VERSION "created by canmatrix"

NS_ :

BS_:

BU_: IPD

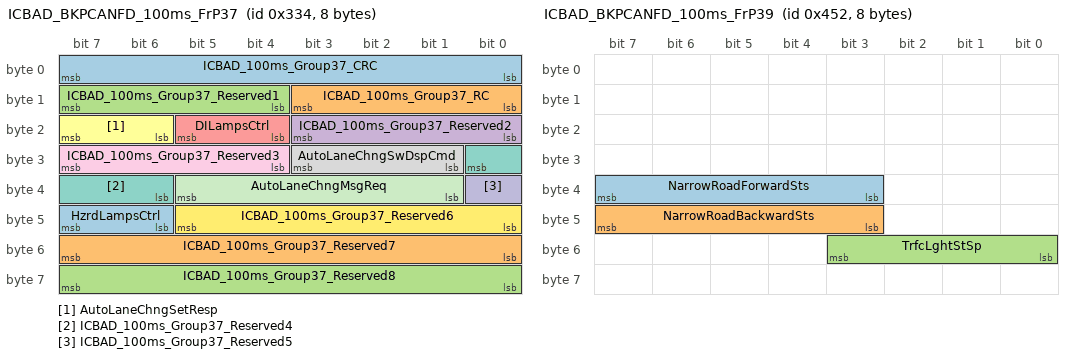
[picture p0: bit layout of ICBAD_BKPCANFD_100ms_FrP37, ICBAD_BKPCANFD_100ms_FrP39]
BO_ 820 ICBAD_BKPCANFD_100ms_FrP37: 8 IPD
 SG_ ICBAD_100ms_Group37_CRC : 7|8@0+ (1,0) [0|255] "null" Vector__XXX
 SG_ ICBAD_100ms_Group37_RC : 11|4@0+ (1,0) [0|15] "null" Vector__XXX
 SG_ ICBAD_100ms_Group37_Reserved1 : 15|4@0+ (1,0) [0|15] "null" Vector__XXX
 SG_ ICBAD_100ms_Group37_Reserved2 : 19|4@0+ (1,0) [0|15] "null" Vector__XXX
 SG_ DILampsCtrl : 21|2@0+ (1,0) [0|3] "null" Vector__XXX
 SG_ AutoLaneChngSetResp : 23|2@0+ (1,0) [0|3] "null" Vector__XXX
 SG_ ICBAD_100ms_Group37_Reserved4 : 24|3@0+ (1,0) [0|7] "null" Vector__XXX
 SG_ AutoLaneChngSwDspCmd : 27|3@0+ (1,0) [0|7] "null" Vector__XXX
 SG_ ICBAD_100ms_Group37_Reserved3 : 31|4@0+ (1,0) [0|15] "null" Vector__XXX
 SG_ ICBAD_100ms_Group37_Reserved5 : 32|1@0+ (1,0) [0|1] "null" Vector__XXX
 SG_ AutoLaneChngMsgReq : 37|5@0+ (1,0) [0|31] "null" Vector__XXX
 SG_ ICBAD_100ms_Group37_Reserved6 : 45|6@0+ (1,0) [0|63] "null" Vector__XXX
 SG_ HzrdLampsCtrl : 47|2@0+ (1,0) [0|3] "null" Vector__XXX
 SG_ ICBAD_100ms_Group37_Reserved7 : 55|8@0+ (1,0) [0|255] "null" Vector__XXX
 SG_ ICBAD_100ms_Group37_Reserved8 : 63|8@0+ (1,0) [0|255] "null" Vector__XXX

BO_ 1105 ICBAD_BKPCANFD_100ms_FrP38: 32 IPD
 SG_ ELKSysFltSts : 74|2@0+ (1,0) [0|3] "null" Vector__XXX
 SG_ NrwroadFwdSta : 122|3@0+ (1,0) [0|7] "null" Vector__XXX
 SG_ NrwroadsltSta : 130|3@0+ (1,0) [0|7] "null" Vector__XXX
 SG_ ELKDspCmd : 194|2@0+ (1,0) [0|3] "null" Vector__XXX
 SG_ MemParkngBtnRcnm : 203|2@0+ (1,0) [0|3] "null" Vector__XXX

BO_ 1106 ICBAD_BKPCANFD_100ms_FrP39: 8 IPD
 SG_ NarrowRoadForwardSts : 39|5@0+ (1,0) [0|31] "null" Vector__XXX
 SG_ NarrowRoadBackwardSts : 47|5@0+ (1,0) [0|31] "null" Vector__XXX
 SG_ TrfcLghtStSp : 51|4@0+ (1,0) [0|15] "null" Vector__XXX

BO_ 151 ICBAD_BKPCANFD_100ms_FrP44: 24 IPD
 SG_ AIParkngEPAMdsts : 32|1@0+ (1,0) [0|1] "null" Vector__XXX
 SG_ D2DSwReqResps : 41|2@0+ (1,0) [0|3] "null" Vector__XXX
 SG_ FCTBSysFltSts : 77|2@0+ (1,0) [0|3] "null" Vector__XXX
 SG_ D2DPriETClanSwReqResps : 79|2@0+ (1,0) [0|3] "null" Vector__XXX

BO_ 382 ICBAD_BKPCANFD_20ms_FrP07: 8 IPD
 SG_ ICBAD_20ms_Group07_CRC : 7|8@0+ (1,0) [0|255] "null" Vector__XXX
 SG_ ICBAD_20ms_Group07_RC : 11|4@0+ (1,0) [0|15] "null" Vector__XXX
 SG_ ACCSdslReq : 12|1@0+ (1,0) [0|1] "null" Vector__XXX
 SG_ ACCGoReq : 13|1@0+ (1,0) [0|1] "null" Vector__XXX
 SG_ ACCAccReqSts_CH : 15|2@0+ (1,0) [0|3] "null" Vector__XXX
 SG_ ACCAccReqVal : 18|11@0+ (0.006,-10.278) [-10.278|2.004] "null" Vector__XXX
 SG_ APAEPBOPReq : 20|2@0+ (1,0) [0|3] "null" Vector__XXX
 SG_ ACCSysFltSts : 23|3@0+ (1,0) [0|7] "null" Vector__XXX
 SG_ AIPkgAPASCSAcclReqVal : 34|11@0+ (0.005,-9.22) [-9.220|1.015] "m/s^2" Vector__XXX
 SG_ ACCSysSts : 37|3@0+ (1,0) [0|7] "null" Vector__XXX
 SG_ APASCSAcclReqSts : 38|1@0+ (1,0) [0|1] "null" Vector__XXX
 SG_ APAEPBOPReqV : 39|1@0+ (1,0) [0|1] "null" Vector__XXX
 SG_ AutodDrvngSysSCSSdslReqV : 48|1@0+ (1,0) [0|1] "null" Vector__XXX
 SG_ AutodDrvngSysSCSSdslReq : 49|1@0+ (1,0) [0|1] "null" Vector__XXX
 SG_ AutodDrvngSysEmgcBrkReqV : 50|1@0+ (1,0) [0|1] "null" Vector__XXX
 SG_ AutodDrvngSysEmgcBrkReq : 51|1@0+ (1,0) [0|1] "null" Vector__XXX
 SG_ ICBAD_20ms_Group07_Reserved1 : 55|4@0+ (1,0) [0|15] "null" Vector__XXX
 SG_ AutodDrvngSysSCSDrvOffReqV : 56|1@0+ (1,0) [0|1] "null" Vector__XXX
 SG_ AutodDrvngSysSCSDrvOffReq : 57|1@0+ (1,0) [0|1] "null" Vector__XXX
 SG_ AutodDrvngSysMdReqV : 58|1@0+ (1,0) [0|1] "null" Vector__XXX
 SG_ AutodDrvngSysMdReq : 59|1@0+ (1,0) [0|1] "null" Vector__XXX
 SG_ AutodDrvngSysFlrStsV : 60|1@0+ (1,0) [0|1] "null" Vector__XXX
 SG_ AutodDrvngSysFlrSts : 63|3@0+ (1,0) [0|7] "null" Vector__XXX

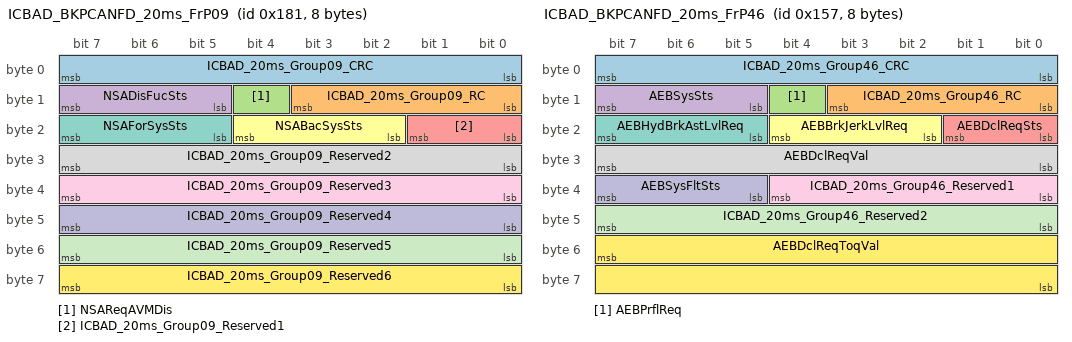
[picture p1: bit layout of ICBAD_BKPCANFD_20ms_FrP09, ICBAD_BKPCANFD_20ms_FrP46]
BO_ 385 ICBAD_BKPCANFD_20ms_FrP09: 8 IPD
 SG_ ICBAD_20ms_Group09_CRC : 7|8@0+ (1,0) [0|255] "null" Vector__XXX
 SG_ ICBAD_20ms_Group09_RC : 11|4@0+ (1,0) [0|15] "null" Vector__XXX
 SG_ NSAReqAVMDis : 12|1@0+ (1,0) [0|1] "null" Vector__XXX
 SG_ NSADisFucSts : 15|3@0+ (1,0) [0|7] "null" Vector__XXX
 SG_ ICBAD_20ms_Group09_Reserved1 : 17|2@0+ (1,0) [0|3] "null" Vector__XXX
 SG_ NSABacSysSts : 20|3@0+ (1,0) [0|7] "null" Vector__XXX
 SG_ NSAForSysSts : 23|3@0+ (1,0) [0|7] "null" Vector__XXX
 SG_ ICBAD_20ms_Group09_Reserved2 : 31|8@0+ (1,0) [0|255] "null" Vector__XXX
 SG_ ICBAD_20ms_Group09_Reserved3 : 39|8@0+ (1,0) [0|255] "null" Vector__XXX
 SG_ ICBAD_20ms_Group09_Reserved4 : 47|8@0+ (1,0) [0|255] "null" Vector__XXX
 SG_ ICBAD_20ms_Group09_Reserved5 : 55|8@0+ (1,0) [0|255] "null" Vector__XXX
 SG_ ICBAD_20ms_Group09_Reserved6 : 63|8@0+ (1,0) [0|255] "null" Vector__XXX

BO_ 343 ICBAD_BKPCANFD_20ms_FrP46: 8 IPD
 SG_ ICBAD_20ms_Group46_CRC : 7|8@0+ (1,0) [0|255] "null" Vector__XXX
 SG_ ICBAD_20ms_Group46_RC : 11|4@0+ (1,0) [0|15] "null" Vector__XXX
 SG_ AEBPrflReq : 12|1@0+ (1,0) [0|1] "null" Vector__XXX
 SG_ AEBSysSts : 15|3@0+ (1,0) [0|7] "null" Vector__XXX
 SG_ AEBDclReqSts : 17|2@0+ (1,0) [0|3] "null" Vector__XXX
 SG_ AEBBrkJerkLvlReq : 20|3@0+ (1,0) [0|7] "null" Vector__XXX
 SG_ AEBHydBrkAstLvlReq : 23|3@0+ (1,0) [0|7] "null" Vector__XXX
 SG_ AEBDclReqVal : 31|8@0+ (0.1,-12.7) [-12.7|12.8] "m/s2" Vector__XXX
 SG_ ICBAD_20ms_Group46_Reserved1 : 36|5@0+ (1,0) [0|31] "null" Vector__XXX
 SG_ AEBSysFltSts : 39|3@0+ (1,0) [0|7] "null" Vector__XXX
 SG_ ICBAD_20ms_Group46_Reserved2 : 47|8@0+ (1,0) [0|255] "null" Vector__XXX
 SG_ AEBDclReqToqVal : 55|16@0+ (1,0) [0|65535] "Nm" Vector__XXX

BO_ 736 ICBAD_BKPCANFD_50ms_FrP17: 20 IPD
 SG_ FrtObsDist : 7|8@0+ (1,0) [0|255] "cm" Vector__XXX
 SG_ FrtMidRObsRng : 11|4@0+ (1,0) [0|15] "null" Vector__XXX
 SG_ FrtPDCAudWrnng : 15|4@0+ (1,0) [0|15] "null" Vector__XXX
 SG_ RrMidLObsRng : 19|4@0+ (1,0) [0|15] "null" Vector__XXX
 SG_ RLObsRng : 23|4@0+ (1,0) [0|15] "null" Vector__XXX
 SG_ RrMidRObsRng : 31|4@0+ (1,0) [0|15] "null" Vector__XXX
 SG_ PDCSysSts : 39|4@0+ (1,0) [0|15] "null" Vector__XXX
 SG_ RrObsDist : 63|8@0+ (1,0) [0|255] "cm" Vector__XXX
 SG_ FLSideObsRng : 67|4@0+ (1,0) [0|15] "null" Vector__XXX
 SG_ RrPDCAudWrnng : 71|4@0+ (1,0) [0|15] "null" Vector__XXX
 SG_ RLSideObsRng : 75|4@0+ (1,0) [0|15] "null" Vector__XXX
 SG_ FRSideObsRng : 79|4@0+ (1,0) [0|15] "null" Vector__XXX
 SG_ RRSideObsRng : 87|4@0+ (1,0) [0|15] "null" Vector__XXX
 SG_ FLObsRng : 123|4@0+ (1,0) [0|15] "null" Vector__XXX
 SG_ RRObsRng : 131|4@0+ (1,0) [0|15] "null" Vector__XXX
 SG_ FRObsRng : 135|4@0+ (1,0) [0|15] "null" Vector__XXX
 SG_ LADSAFnInd_Tester : 139|4@0+ (1,0) [0|15] "null" Vector__XXX
 SG_ FrtMidLObsRng : 143|4@0+ (1,0) [0|15] "null" Vector__XXX
 SG_ FRSObsRng : 147|4@0+ (1,0) [0|15] "null" Vector__XXX
 SG_ FLSObsRng : 151|4@0+ (1,0) [0|15] "null" Vector__XXX
 SG_ RRSObsRng : 155|4@0+ (1,0) [0|15] "null" Vector__XXX
 SG_ RLSObsRng : 159|4@0+ (1,0) [0|15] "null" Vector__XXX

BO_ 893 ICBAD_CHCANFD_100ms_FrP25: 24 IPD
 SG_ ICBAD_100ms_Group25_CRC : 7|8@0+ (1,0) [0|255] "null" Vector__XXX
 SG_ ICBAD_100ms_Group25_RC : 11|4@0+ (1,0) [0|15] "null" Vector__XXX
 SG_ ICBAD_100ms_Group25_Reserved15 : 15|4@0+ (1,0) [0|15] "null" Vector__XXX
 SG_ ICBAD_100ms_Group25_Reserved23 : 23|8@0+ (1,0) [0|255] "null" Vector__XXX
 SG_ ICBAD_100ms_Group25_Reserved31 : 31|8@0+ (1,0) [0|255] "null" Vector__XXX
 SG_ ICBAD_100ms_Group25_Reserved39 : 39|8@0+ (1,0) [0|255] "null" Vector__XXX
 SG_ ICBAD_100ms_Group25_Reserved47 : 47|8@0+ (1,0) [0|255] "null" Vector__XXX
 SG_ ICBAD_100ms_Group25_Reserved55 : 55|8@0+ (1,0) [0|255] "null" Vector__XXX
 SG_ ICBAD_100ms_Group25_Reserved63 : 63|8@0+ (1,0) [0|255] "null" Vector__XXX
 SG_ ICBAD_100ms_Group25_Reserved71 : 71|8@0+ (1,0) [0|255] "null" Vector__XXX
 SG_ ICBAD_100ms_Group25_Reserved79 : 79|8@0+ (1,0) [0|255] "null" Vector__XXX
 SG_ ICBAD_100ms_Group25_Reserved87 : 87|8@0+ (1,0) [0|255] "null" Vector__XXX
 SG_ ICBAD_100ms_Group25_Reserved95 : 95|8@0+ (1,0) [0|255] "null" Vector__XXX
 SG_ MemPkngSwResp : 97|2@0+ (1,0) [0|3] "null" Vector__XXX
 SG_ ICBAD_100ms_Group25_Reserved103 : 103|6@0+ (1,0) [0|63] "null" Vector__XXX
 SG_ MemPkngSlntPtrlEnbSwResp : 105|2@0+ (1,0) [0|3] "null" Vector__XXX
 SG_ ICBAD_100ms_Group25_Reserved111 : 111|6@0+ (1,0) [0|63] "null" Vector__XXX
 SG_ ICBAD_100ms_Group25_Reserved119 : 119|8@0+ (1,0) [0|255] "null" Vector__XXX
 SG_ PEBSysFltSts : 121|2@0+ (1,0) [0|3] "null" Vector__XXX
 SG_ ICBAD_100ms_Group25_Reserved127 : 127|6@0+ (1,0) [0|63] "null" Vector__XXX
 SG_ ICBAD_100ms_Group25_Reserved135 : 135|8@0+ (1,0) [0|255] "null" Vector__XXX
 SG_ ICBAD_100ms_Group25_Reserved143 : 143|8@0+ (1,0) [0|255] "null" Vector__XXX
 SG_ ICBAD_100ms_Group25_Reserved151 : 151|8@0+ (1,0) [0|255] "null" Vector__XXX
 SG_ ICBAD_100ms_Group25_Reserved159 : 159|8@0+ (1,0) [0|255] "null" Vector__XXX
 SG_ ICBAD_100ms_Group25_Reserved167 : 167|8@0+ (1,0) [0|255] "null" Vector__XXX
 SG_ ICBAD_100ms_Group25_Reserved175 : 175|8@0+ (1,0) [0|255] "null" Vector__XXX
 SG_ ICBAD_100ms_Group25_Reserved183 : 183|8@0+ (1,0) [0|255] "null" Vector__XXX
 SG_ ICBAD_100ms_Group25_Reserved191 : 191|8@0+ (1,0) [0|255] "null" Vector__XXX

BO_ 314 ICBAD_CHCANFD_20ms_FrP08: 8 IPD
 SG_ D2DSysSts : 31|4@0+ (1,0) [0|15] "null" Vector__XXX
 SG_ ACCObjDet : 56|1@0+ (1,0) [0|1] "null" Vector__XXX

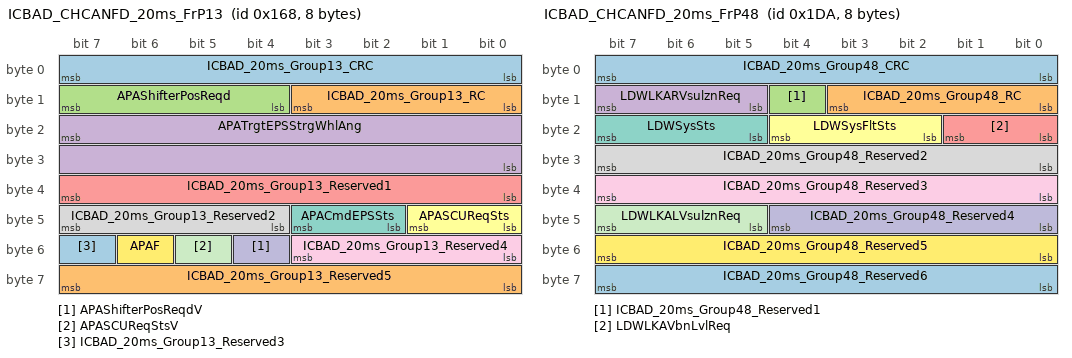
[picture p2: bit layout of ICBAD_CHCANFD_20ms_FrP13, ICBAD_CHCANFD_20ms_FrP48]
BO_ 360 ICBAD_CHCANFD_20ms_FrP13: 8 IPD
 SG_ ICBAD_20ms_Group13_CRC : 7|8@0+ (1,0) [0|255] "null" Vector__XXX
 SG_ ICBAD_20ms_Group13_RC : 11|4@0+ (1,0) [0|15] "null" Vector__XXX
 SG_ APAShifterPosReqd : 15|4@0+ (1,0) [0|15] "null" Vector__XXX
 SG_ APATrgtEPSStrgWhlAng : 23|16@0+ (0.0625,-2048) [-2048.0000|2047.9375] "percent" Vector__XXX
 SG_ ICBAD_20ms_Group13_Reserved1 : 39|8@0+ (1,0) [0|255] "null" Vector__XXX
 SG_ APASCUReqSts : 41|2@0+ (1,0) [0|3] "null" Vector__XXX
 SG_ APACmdEPSSts : 43|2@0+ (1,0) [0|3] "null" Vector__XXX
 SG_ ICBAD_20ms_Group13_Reserved2 : 47|4@0+ (1,0) [0|15] "null" Vector__XXX
 SG_ ICBAD_20ms_Group13_Reserved4 : 51|4@0+ (1,0) [0|15] "null" Vector__XXX
 SG_ APAShifterPosReqdV : 52|1@0+ (1,0) [0|1] "null" Vector__XXX
 SG_ APASCUReqStsV : 53|1@0+ (1,0) [0|1] "null" Vector__XXX
 SG_ APAF : 54|1@0+ (1,0) [0|1] "null" Vector__XXX
 SG_ ICBAD_20ms_Group13_Reserved3 : 55|1@0+ (1,0) [0|1] "null" Vector__XXX
 SG_ ICBAD_20ms_Group13_Reserved5 : 63|8@0+ (1,0) [0|255] "null" Vector__XXX

BO_ 474 ICBAD_CHCANFD_20ms_FrP48: 8 IPD
 SG_ ICBAD_20ms_Group48_CRC : 7|8@0+ (1,0) [0|255] "null" Vector__XXX
 SG_ ICBAD_20ms_Group48_RC : 11|4@0+ (1,0) [0|15] "null" Vector__XXX
 SG_ ICBAD_20ms_Group48_Reserved1 : 12|1@0+ (1,0) [0|1] "null" Vector__XXX
 SG_ LDWLKARVsulznReq : 15|3@0+ (1,0) [0|7] "null" Vector__XXX
 SG_ LDWLKAVbnLvlReq : 17|2@0+ (1,0) [0|3] "null" Vector__XXX
 SG_ LDWSysFltSts : 20|3@0+ (1,0) [0|7] "null" Vector__XXX
 SG_ LDWSysSts : 23|3@0+ (1,0) [0|7] "null" Vector__XXX
 SG_ ICBAD_20ms_Group48_Reserved2 : 31|8@0+ (1,0) [0|255] "null" Vector__XXX
 SG_ ICBAD_20ms_Group48_Reserved3 : 39|8@0+ (1,0) [0|255] "null" Vector__XXX
 SG_ ICBAD_20ms_Group48_Reserved4 : 44|5@0+ (1,0) [0|31] "null" Vector__XXX
 SG_ LDWLKALVsulznReq : 47|3@0+ (1,0) [0|7] "null" Vector__XXX
 SG_ ICBAD_20ms_Group48_Reserved5 : 55|8@0+ (1,0) [0|255] "null" Vector__XXX
 SG_ ICBAD_20ms_Group48_Reserved6 : 63|8@0+ (1,0) [0|255] "null" Vector__XXX

BO_ 351 ICBAD_RZCUCANFD_20ms_FrP05: 20 IPD
 SG_ ICBAD_20ms_Group05_CRC : 7|8@0+ (1,0) [0|255] "null" Vector__XXX
 SG_ ICBAD_20ms_Group05_RC : 11|4@0+ (1,0) [0|15] "null" Vector__XXX
 SG_ ICBAD_20ms_Group05_Reserved1 : 12|1@0+ (1,0) [0|1] "null" Vector__XXX
 SG_ APAVCUReqSts : 15|3@0+ (1,0) [0|7] "null" Vector__XXX
 SG_ ICBAD_20ms_Group05_Reserved2 : 23|8@0+ (1,0) [0|255] "null" Vector__XXX
 SG_ APAToqReqVal : 31|12@0+ (0.5,-848) [-848|1199.5] "Nm" Vector__XXX
 SG_ APACrpSpdReqVal_IPD : 33|10@0+ (0.1,0) [0|102.3] "km/h" Vector__XXX
 SG_ ICBAD_20ms_Group05_Reserved3 : 34|1@0+ (1,0) [0|1] "null" Vector__XXX
 SG_ APARevrDrgReq : 35|1@0+ (1,0) [0|1] "null" Vector__XXX
 SG_ ICBAD_20ms_Group05_Reserved4 : 55|8@0+ (1,0) [0|255] "null" Vector__XXX
 SG_ ICBAD_20ms_Group05_Reserved5 : 63|8@0+ (1,0) [0|255] "null" Vector__XXX
 SG_ APATotWhlToqReqVal : 71|16@0+ (1,-30000) [-30000|35535] "Nm" Vector__XXX
 SG_ ICBAD_20ms_Group05_Reserved6 : 87|8@0+ (1,0) [0|255] "null" Vector__XXX
 SG_ ICBAD_20ms_Group05_Reserved7 : 95|8@0+ (1,0) [0|255] "null" Vector__XXX
 SG_ ICBAD_20ms_Group05_Reserved8 : 103|8@0+ (1,0) [0|255] "null" Vector__XXX
 SG_ ICBAD_20ms_Group05_Reserved9 : 111|8@0+ (1,0) [0|255] "null" Vector__XXX
 SG_ ICBAD_20ms_Group05_Reserved10 : 119|8@0+ (1,0) [0|255] "null" Vector__XXX
 SG_ ICBAD_20ms_Group05_Reserved11 : 127|8@0+ (1,0) [0|255] "null" Vector__XXX
 SG_ ICBAD_20ms_Group05_Reserved12 : 135|8@0+ (1,0) [0|255] "null" Vector__XXX
 SG_ ICBAD_20ms_Group05_Reserved13 : 143|8@0+ (1,0) [0|255] "null" Vector__XXX
 SG_ ICBAD_20ms_Group05_Reserved14 : 151|8@0+ (1,0) [0|255] "null" Vector__XXX
 SG_ ICBAD_20ms_Group05_Reserved15 : 159|8@0+ (1,0) [0|255] "null" Vector__XXX

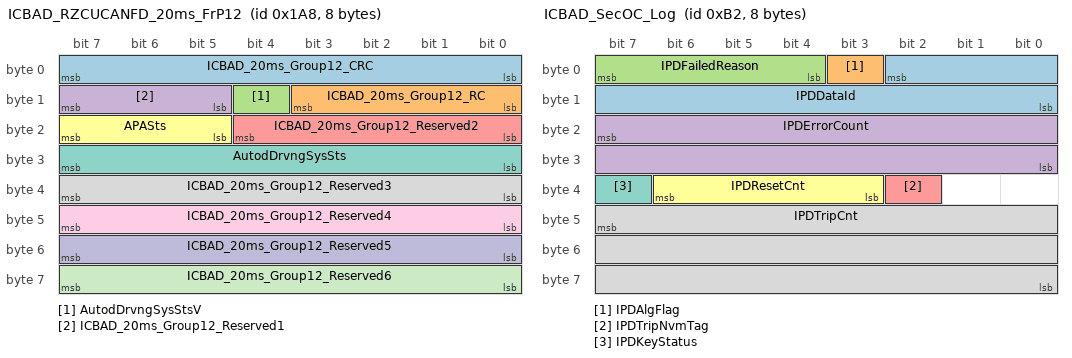
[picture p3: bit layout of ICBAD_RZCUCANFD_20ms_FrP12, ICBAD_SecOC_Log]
BO_ 424 ICBAD_RZCUCANFD_20ms_FrP12: 8 IPD
 SG_ ICBAD_20ms_Group12_CRC : 7|8@0+ (1,0) [0|255] "null" Vector__XXX
 SG_ ICBAD_20ms_Group12_RC : 11|4@0+ (1,0) [0|15] "null" Vector__XXX
 SG_ AutodDrvngSysStsV : 12|1@0+ (1,0) [0|1] "null" Vector__XXX
 SG_ ICBAD_20ms_Group12_Reserved1 : 15|3@0+ (1,0) [0|7] "null" Vector__XXX
 SG_ ICBAD_20ms_Group12_Reserved2 : 20|5@0+ (1,0) [0|31] "null" Vector__XXX
 SG_ APASts : 23|3@0+ (1,0) [0|7] "null" Vector__XXX
 SG_ AutodDrvngSysSts : 31|8@0+ (1,0) [0|255] "null" Vector__XXX
 SG_ ICBAD_20ms_Group12_Reserved3 : 39|8@0+ (1,0) [0|255] "null" Vector__XXX
 SG_ ICBAD_20ms_Group12_Reserved4 : 47|8@0+ (1,0) [0|255] "null" Vector__XXX
 SG_ ICBAD_20ms_Group12_Reserved5 : 55|8@0+ (1,0) [0|255] "null" Vector__XXX
 SG_ ICBAD_20ms_Group12_Reserved6 : 63|8@0+ (1,0) [0|255] "null" Vector__XXX

BO_ 50 ICBAD_SecOC_ComKeyResp: 8 IPD
 SG_ IPDTripCntResetResp : 6|1@0+ (1,0) [0|1] "null" Vector__XXX

BO_ 178 ICBAD_SecOC_Log: 8 IPD
 SG_ IPDDataId : 2|11@0+ (1,0) [0|2047] "null" Vector__XXX
 SG_ IPDAlgFlag : 3|1@0+ (1,0) [0|1] "null" Vector__XXX
 SG_ IPDFailedReason : 7|4@0+ (1,0) [0|15] "null" Vector__XXX
 SG_ IPDErrorCount : 23|16@0+ (1,0) [0|65535] "null" Vector__XXX
 SG_ IPDTripNvmTag : 34|1@0+ (1,0) [0|1] "null" Vector__XXX
 SG_ IPDResetCnt : 38|4@0+ (1,0) [0|15] "null" Vector__XXX
 SG_ IPDKeyStatus : 39|1@0+ (1,0) [0|1] "null" Vector__XXX
 SG_ IPDTripCnt : 47|24@0+ (1,0) [0|16777215] "null" Vector__XXX

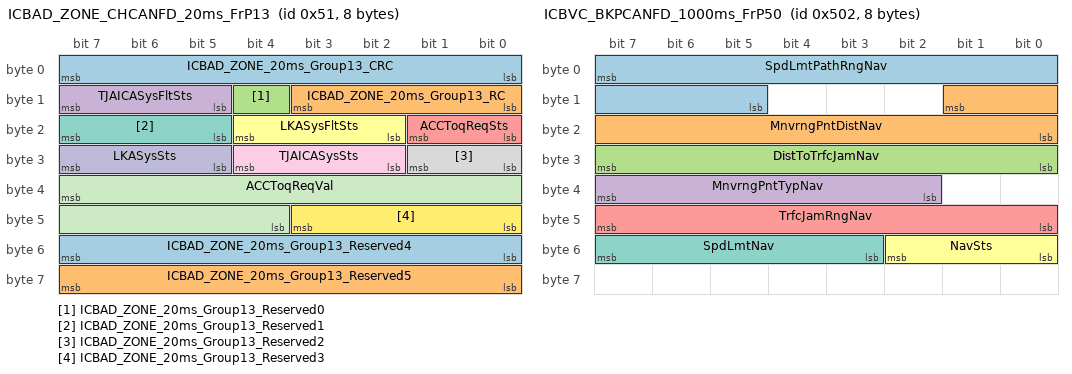
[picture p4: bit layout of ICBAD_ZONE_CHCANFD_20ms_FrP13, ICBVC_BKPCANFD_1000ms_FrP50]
BO_ 81 ICBAD_ZONE_CHCANFD_20ms_FrP13: 8 IPD
 SG_ ICBAD_ZONE_20ms_Group13_CRC : 7|8@0+ (1,0) [0|255] "null" Vector__XXX
 SG_ ICBAD_ZONE_20ms_Group13_RC : 11|4@0+ (1,0) [0|15] "null" Vector__XXX
 SG_ ICBAD_ZONE_20ms_Group13_Reserved0 : 12|1@0+ (1,0) [0|1] "null" Vector__XXX
 SG_ TJAICASysFltSts : 15|3@0+ (1,0) [0|7] "null" Vector__XXX
 SG_ ACCToqReqSts : 17|2@0+ (1,0) [0|3] "null" Vector__XXX
 SG_ LKASysFltSts : 20|3@0+ (1,0) [0|7] "null" Vector__XXX
 SG_ ICBAD_ZONE_20ms_Group13_Reserved1 : 23|3@0+ (1,0) [0|7] "null" Vector__XXX
 SG_ ICBAD_ZONE_20ms_Group13_Reserved2 : 25|2@0+ (1,0) [0|3] "null" Vector__XXX
 SG_ TJAICASysSts : 28|3@0+ (1,0) [0|7] "null" Vector__XXX
 SG_ LKASysSts : 31|3@0+ (1,0) [0|7] "null" Vector__XXX
 SG_ ACCToqReqVal : 39|12@0+ (0.5,-848) [-848|1199.5] "null" Vector__XXX
 SG_ ICBAD_ZONE_20ms_Group13_Reserved3 : 43|4@0+ (1,0) [0|15] "null" Vector__XXX
 SG_ ICBAD_ZONE_20ms_Group13_Reserved4 : 55|8@0+ (1,0) [0|255] "null" Vector__XXX
 SG_ ICBAD_ZONE_20ms_Group13_Reserved5 : 63|8@0+ (1,0) [0|255] "null" Vector__XXX

BO_ 1282 ICBVC_BKPCANFD_1000ms_FrP50: 8 Vector__XXX
 SG_ SpdLmtPathRngNav : 7|11@0+ (0.01,0) [0.00|20.47] "km" IPD
 SG_ MnvrngPntDistNav : 9|10@0+ (1,0) [0|1023] "m" IPD
 SG_ DistToTrfcJamNav : 31|8@0+ (0.1,0) [0|25.5] "km" IPD
 SG_ MnvrngPntTypNav : 39|6@0+ (1,0) [0|63] "null" IPD
 SG_ TrfcJamRngNav : 47|8@0+ (0.1,0) [0|25.5] "km" IPD
 SG_ NavSts : 50|3@0+ (1,0) [0|7] "null" IPD
 SG_ SpdLmtNav : 55|5@0+ (5,0) [0|155] "kph" IPD

BO_ 66 ICBVC_BKPCANFD_100ms_FrP01: 16 Vector__XXX
 SG_ ICBVC_100ms_Group01_CRC : 7|8@0+ (1,0) [0|255] "null" IPD
 SG_ ICBVC_100ms_Group01_RC : 11|4@0+ (1,0) [0|15] "null" IPD
 SG_ ICBVC_100ms_Group01_Reserved14 : 14|3@0+ (1,0) [0|7] "null" IPD
 SG_ DspMeasmtSys : 15|1@0+ (1,0) [0|1] "null" IPD
 SG_ ICBVC_100ms_Group01_Reserved21 : 21|6@0+ (1,0) [0|63] "null" IPD
 SG_ PDCSwReq : 23|2@0+ (1,0) [0|3] "null" IPD
 SG_ PwrMdExtrCtrlAvlbl : 24|1@0+ (1,0) [0|1] "null" IPD
 SG_ MdOfPwrMd : 25|1@0+ (1,0) [0|1] "null" IPD
 SG_ ICBVC_100ms_Group01_Reserved31 : 31|6@0+ (1,0) [0|63] "null" IPD
 SG_ ClstrDspdVehSpd : 39|8@0+ (1,0) [0|255] "kph" IPD
 SG_ ICBVC_100ms_Group01_Reserved47 : 47|8@0+ (1,0) [0|255] "null" IPD
 SG_ ICBVC_100ms_Group01_Reserved55 : 55|8@0+ (1,0) [0|255] "null" IPD
 SG_ ICBVC_100ms_Group01_Reserved63 : 63|8@0+ (1,0) [0|255] "null" IPD
 SG_ ICBVC_100ms_Group01_Reserved71 : 71|8@0+ (1,0) [0|255] "null" IPD
 SG_ ICBVC_100ms_Group01_Reserved72 : 72|1@0+ (1,0) [0|1] "null" IPD
 SG_ FRSeatVentCtrlSts : 75|3@0+ (1,0) [0|7] "null" IPD
 SG_ ICBVC_100ms_Group01_Reserved79 : 79|4@0+ (1,0) [0|15] "null" IPD
 SG_ ICBVC_100ms_Group01_Reserved80 : 80|1@0+ (1,0) [0|1] "null" IPD
 SG_ FLSeatVentCtrlSts : 83|3@0+ (1,0) [0|7] "null" IPD
 SG_ ICBVC_100ms_Group01_Reserved84 : 84|1@0+ (1,0) [0|1] "null" IPD
 SG_ FRSeatHeatCtrlSts : 87|3@0+ (1,0) [0|7] "null" IPD
 SG_ ICBVC_100ms_Group01_Reserved92 : 92|5@0+ (1,0) [0|31] "null" IPD
 SG_ FLSeatHeatCtrlSts : 95|3@0+ (1,0) [0|7] "null" IPD
 SG_ ICBVC_100ms_Group01_Reserved103 : 103|8@0+ (1,0) [0|255] "null" IPD
 SG_ ICBVC_100ms_Group01_Reserved111 : 111|8@0+ (1,0) [0|255] "null" IPD
 SG_ ICBVC_100ms_Group01_Reserved119 : 119|8@0+ (1,0) [0|255] "null" IPD
 SG_ ICBVC_100ms_Group01_Reserved127 : 127|8@0+ (1,0) [0|255] "null" IPD

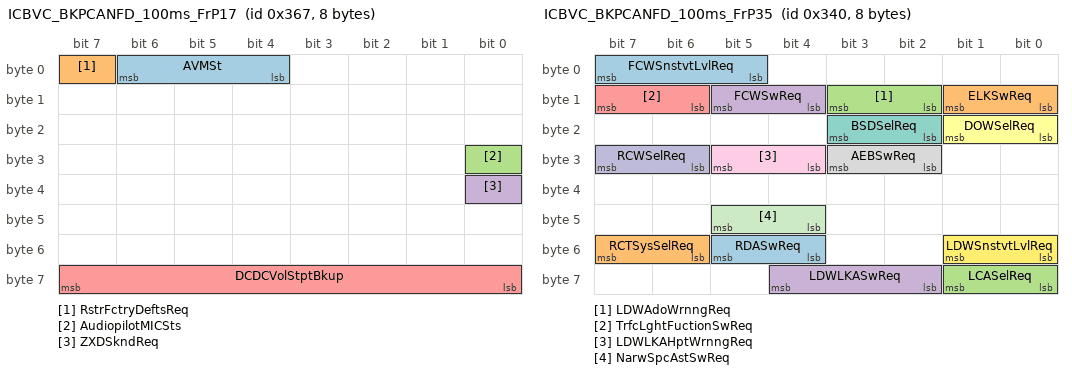
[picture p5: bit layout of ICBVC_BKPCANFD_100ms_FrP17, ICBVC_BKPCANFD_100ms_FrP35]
BO_ 871 ICBVC_BKPCANFD_100ms_FrP17: 8 Vector__XXX
 SG_ AVMSt : 6|3@0+ (1,0) [0|7] "null" IPD
 SG_ RstrFctryDeftsReq : 7|1@0+ (1,0) [0|1] "null" IPD
 SG_ AudiopilotMICSts : 24|1@0+ (1,0) [0|1] "null" Vector__XXX
 SG_ ZXDSkndReq : 32|1@0+ (1,0) [0|1] "null" Vector__XXX
 SG_ DCDCVolStptBkup : 63|8@0+ (0.03125,8.5) [8.50000|16.46875] "V" Vector__XXX

BO_ 906 ICBVC_BKPCANFD_100ms_FrP25: 24 Vector__XXX
 SG_ NavCrntRoadTyp : 3|4@0+ (1,0) [0|15] "null" IPD
 SG_ NavSpdLmtValUnit : 66|2@0+ (1,0) [0|3] "null" IPD
 SG_ NavNewIconDist : 71|5@0+ (0.1,0) [0|3.1] "null" IPD
 SG_ NavSpdLmtValSts : 73|2@0+ (1,0) [0|3] "null" IPD
 SG_ NavDistFromFrtEleccEye : 79|6@0+ (0.1,0) [0|6.3] "null" IPD
 SG_ NavItvalSpdDetnDistRetDist : 87|15@0+ (0.1,0) [0|3276.7] "null" IPD
 SG_ NavSpdLmtVal : 103|15@0+ (0.015625,0) [0.000000|511.984375] "null" IPD
 SG_ NavCndSpdLmtVal : 119|8@0+ (1,0) [0|255] "null" IPD
 SG_ NavSpdLmtTyp : 126|4@0+ (1,0) [0|15] "null" IPD
 SG_ NavNextRampOffset : 135|13@0+ (8.235,-100) [-100.000|67352.885] "m" IPD

BO_ 1104 ICBVC_BKPCANFD_100ms_FrP31: 20 Vector__XXX
 SG_ NrwroadFwdCtlReq : 39|4@0+ (1,0) [0|15] "null" IPD
 SG_ AIParkngSpdsw : 84|3@0+ (1,0) [0|7] "null" IPD
 SG_ NrwroadsltReq : 100|3@0+ (1,0) [0|7] "null" IPD
 SG_ NrwroadFwdReq : 103|3@0+ (1,0) [0|7] "null" IPD
 SG_ MemPkngSwReq : 121|2@0+ (1,0) [0|3] "null" IPD
 SG_ MemPkngSlntPtrlEnbSwReq : 131|2@0+ (1,0) [0|3] "null" IPD

BO_ 832 ICBVC_BKPCANFD_100ms_FrP35: 8 Vector__XXX
 SG_ FCWSnstvtLvlReq : 7|3@0+ (1,0) [0|7] "null" IPD
 SG_ ELKSwReq : 9|2@0+ (1,0) [0|3] "null" IPD
 SG_ LDWAdoWrnngReq : 11|2@0+ (1,0) [0|3] "null" IPD
 SG_ FCWSwReq : 13|2@0+ (1,0) [0|3] "null" IPD
 SG_ TrfcLghtFuctionSwReq : 15|2@0+ (1,0) [0|3] "null" IPD
 SG_ DOWSelReq : 17|2@0+ (1,0) [0|3] "null" IPD
 SG_ BSDSelReq : 19|2@0+ (1,0) [0|3] "null" IPD
 SG_ AEBSwReq : 27|2@0+ (1,0) [0|3] "null" IPD
 SG_ LDWLKAHptWrnngReq : 29|2@0+ (1,0) [0|3] "null" IPD
 SG_ RCWSelReq : 31|2@0+ (1,0) [0|3] "null" IPD
 SG_ NarwSpcAstSwReq : 45|2@0+ (1,0) [0|3] "null" IPD
 SG_ LDWSnstvtLvlReq : 49|2@0+ (1,0) [0|3] "null" IPD
 SG_ RDASwReq : 53|2@0+ (1,0) [0|3] "null" IPD
 SG_ RCTSysSelReq : 55|2@0+ (1,0) [0|3] "null" IPD
 SG_ LCASelReq : 57|2@0+ (1,0) [0|3] "null" IPD
 SG_ LDWLKASwReq : 60|3@0+ (1,0) [0|7] "null" IPD

BO_ 482 ICBVC_BKPCANFD_50ms_FrP11: 8 Vector__XXX
 SG_ ICBVC_50ms_Group11_CRC : 7|8@0+ (1,0) [0|255] "null" IPD
 SG_ ICBVC_50ms_Group11_RC : 11|4@0+ (1,0) [0|15] "null" IPD
 SG_ TrPfShftPtrnSw3A : 12|1@0+ (1,0) [0|1] "null" IPD
 SG_ TrPfShftPtrnSw2A : 13|1@0+ (1,0) [0|1] "null" IPD
 SG_ PfTrTapUpDwnSwSta : 15|2@0+ (1,0) [0|3] "null" IPD
 SG_ ICBVC_50ms_Group11_Reserved1 : 23|8@0+ (1,0) [0|255] "null" IPD
 SG_ ICBVC_50ms_Group11_Reserved2 : 31|8@0+ (1,0) [0|255] "null" IPD
 SG_ StrgWhlTipcSwDataIntgty : 32|1@0+ (1,0) [0|1] "null" IPD
 SG_ ICBVC_50ms_Group11_Reserved3 : 33|1@0+ (1,0) [0|1] "null" IPD
 SG_ CCSwStsDistIncSwA : 34|1@0+ (1,0) [0|1] "null" IPD
 SG_ CCSwStsDistDecSwA : 35|1@0+ (1,0) [0|1] "null" IPD
 SG_ CCSwStsSpdIncSwA : 36|1@0+ (1,0) [0|1] "null" IPD
 SG_ CCSwStsSpdDecSwA : 37|1@0+ (1,0) [0|1] "null" IPD
 SG_ CCSwStsSwDataIntgty : 39|2@0+ (1,0) [0|3] "null" IPD
 SG_ CCSwStsOnSwA : 40|1@0+ (1,0) [0|1] "null" IPD
 SG_ CCSwStsCanclSwA : 41|1@0+ (1,0) [0|1] "null" IPD
 SG_ PfTrTapUpDwnEnbSwSta : 43|2@0+ (1,0) [0|3] "null" IPD
 SG_ PfTrTapUpDwnSecySwSta : 45|2@0+ (1,0) [0|3] "null" IPD
 SG_ ICBVC_50ms_Group11_Reserved4 : 47|2@0+ (1,0) [0|3] "null" IPD
 SG_ TrPfShftPtrnSw1A : 48|1@0+ (1,0) [0|1] "null" IPD
 SG_ ICBVC_50ms_Group11_Reserved5 : 49|1@0+ (1,0) [0|1] "null" IPD
 SG_ SWSSelUpSwA : 50|1@0+ (1,0) [0|1] "null" IPD
 SG_ SWSSelRSwA : 51|1@0+ (1,0) [0|1] "null" IPD
 SG_ SWSSelLSwA : 52|1@0+ (1,0) [0|1] "null" IPD
 SG_ SWSSelDwnSwA : 53|1@0+ (1,0) [0|1] "null" IPD
 SG_ SWSCnfmSwA : 54|1@0+ (1,0) [0|1] "null" IPD
 SG_ CCSwStsRsmSwA : 55|1@0+ (1,0) [0|1] "null" IPD
 SG_ ICBVC_50ms_Group11_Reserved6 : 56|1@0+ (1,0) [0|1] "null" IPD
 SG_ HMISafFltsts : 59|3@0+ (1,0) [0|7] "null" IPD
 SG_ SwStaE2EErr : 62|3@0+ (1,0) [0|7] "null" IPD
 SG_ TrPfShftPtrnSw4A : 63|1@0+ (1,0) [0|1] "null" IPD

BO_ 1010 ICBVC_BKPCANFD_50ms_FrP13: 16 Vector__XXX
 SG_ ICBVC_50ms_Group13_CRC : 7|8@0+ (1,0) [0|255] "null" IPD
 SG_ ICBVC_50ms_Group13_RC : 11|4@0+ (1,0) [0|15] "null" IPD
 SG_ ICBVC_50ms_Group13_Reserved1 : 15|4@0+ (1,0) [0|15] "null" IPD
 SG_ ICBVC_50ms_Group13_Reserved2 : 23|8@0+ (1,0) [0|255] "null" IPD
 SG_ ICBVC_50ms_Group13_Reserved3 : 31|8@0+ (1,0) [0|255] "null" IPD
 SG_ TgtParkingChosed : 35|4@0+ (1,0) [0|15] "null" IPD
 SG_ SpdLmtMdFICM : 37|2@0+ (1,0) [0|3] "null" IPD
 SG_ AutocParkngSwReq : 39|2@0+ (1,0) [0|3] "null" IPD
 SG_ IMATESysSts : 42|3@0+ (1,0) [0|7] "null" IPD
 SG_ ICBVC_50ms_Group13_Reserved4 : 47|5@0+ (1,0) [0|31] "null" IPD
 SG_ ICBVC_50ms_Group13_Reserved5 : 55|8@0+ (1,0) [0|255] "null" IPD
 SG_ PwrMdCtrlResp : 58|3@0+ (1,0) [0|7] "null" IPD
 SG_ ICBVC_50ms_Group13_Reserved6 : 63|5@0+ (1,0) [0|31] "null" IPD
 SG_ ICBVC_50ms_Group13_Reserved7 : 71|8@0+ (1,0) [0|255] "null" IPD
 SG_ ICBVC_50ms_Group13_Reserved8 : 79|8@0+ (1,0) [0|255] "null" IPD
 SG_ ICBVC_50ms_Group13_Reserved10 : 84|5@0+ (1,0) [0|31] "null" IPD
 SG_ FRDircnLghtFltsts : 85|1@0+ (1,0) [0|1] "null" IPD
 SG_ ICBVC_50ms_Group13_Reserved9 : 86|1@0+ (1,0) [0|1] "null" IPD
 SG_ FLDircnLghtFltsts : 87|1@0+ (1,0) [0|1] "null" IPD
 SG_ ICBVC_50ms_Group13_Reserved12 : 90|3@0+ (1,0) [0|7] "null" IPD
 SG_ FrSsdManuCtrl : 92|2@0+ (1,0) [0|3] "null" IPD
 SG_ ICBVC_50ms_Group13_Reserved11 : 95|3@0+ (1,0) [0|7] "null" IPD
 SG_ ICBVC_50ms_Group13_Reserved13 : 103|8@0+ (1,0) [0|255] "null" IPD
 SG_ ICBVC_50ms_Group13_Reserved14 : 111|8@0+ (1,0) [0|255] "null" IPD
 SG_ ICBVC_50ms_Group13_Reserved15 : 119|8@0+ (1,0) [0|255] "null" IPD
 SG_ ICBVC_50ms_Group13_Reserved16 : 127|8@0+ (1,0) [0|255] "null" IPD

BA_DEF_ BO_ "FrameTriggeringName" STRING;
BA_DEF_ BO_ "GenMsgCycleTime" INT 0 65535;
BA_DEF_ BO_ "GenMsgDelayTime" INT 0 65535;
BA_DEF_ BO_ "GenMsgSendType" ENUM  "cyclicX","spontanX","cyclicIfActiveX","spontanWithDelay","cyclicAndSpontanX","cyclicAndSpontanWithDelay","spontanWithRepitition","cyclicIfActiveAndSpontanWD","cyclicIfActiveFast","cyclicWithRepeatOnDemand","none";
BA_DEF_ BO_ "GenMsgStartValue" STRING;
BA_DEF_ BO_ "PduName" STRING;
BA_DEF_ BO_ "SystemMessageLongSymbol" STRING;
BA_DEF_ BO_ "VFrameFormat" ENUM  "StandardCAN","ExtendedCAN","reserved","reserved","reserved","reserved","reserved","reserved","reserved","reserved","reserved","reserved","reserved","reserved","StandardCAN_FD","ExtendedCAN_FD";
BA_DEF_ SG_ "CompuMethodName" STRING;
BA_DEF_ SG_ "GenSigStartValue" FLOAT 0 100000000000;
BA_DEF_ SG_ "ISignalName" STRING;
BA_DEF_ SG_ "LongName" STRING;
BA_DEF_ SG_ "SysSignalName" STRING;
BA_DEF_ SG_ "SystemSignalLongSymbol" STRING;
BA_ "FrameTriggeringName" BO_ 820 "ICBAD_BKPCANFD_100ms_FrP37";
BA_ "GenMsgCycleTime" BO_ 820 100;
BA_ "GenMsgSendType" BO_ 820 0;
BA_ "GenMsgStartValue" BO_ 820 "00f00ff1c13fffff";
BA_ "PduName" BO_ 820 "ICBAD_100ms_PDU37";
BA_ "VFrameFormat" BO_ 820 14;
BA_ "FrameTriggeringName" BO_ 1105 "ICBAD_BKPCANFD_100ms_FrP38";
BA_ "GenMsgCycleTime" BO_ 1105 100;
BA_ "GenMsgSendType" BO_ 1105 0;
BA_ "GenMsgStartValue" BO_ 1105 "0000000000000000000000000000000000000000000000000000000000000000";
BA_ "PduName" BO_ 1105 "ICBAD_100ms_PDU38";
BA_ "VFrameFormat" BO_ 1105 14;
BA_ "FrameTriggeringName" BO_ 1106 "ICBAD_BKPCANFD_100ms_FrP39";
BA_ "GenMsgCycleTime" BO_ 1106 100;
BA_ "GenMsgSendType" BO_ 1106 0;
BA_ "GenMsgStartValue" BO_ 1106 "0000000000000000";
BA_ "PduName" BO_ 1106 "ICBAD_100ms_PDU39";
BA_ "VFrameFormat" BO_ 1106 14;
BA_ "FrameTriggeringName" BO_ 151 "ICBAD_BKPCANFD_100ms_FrP44";
BA_ "GenMsgCycleTime" BO_ 151 100;
BA_ "GenMsgSendType" BO_ 151 0;
BA_ "GenMsgStartValue" BO_ 151 "000000000000000000000000000000000000000000000000";
BA_ "PduName" BO_ 151 "ICBAD_100ms_PDU44";
BA_ "VFrameFormat" BO_ 151 14;
BA_ "FrameTriggeringName" BO_ 382 "ICBAD_BKPCANFD_20ms_FrP07";
BA_ "GenMsgCycleTime" BO_ 382 20;
BA_ "GenMsgSendType" BO_ 382 0;
BA_ "GenMsgStartValue" BO_ 382 "000006b10000f000";
BA_ "PduName" BO_ 382 "ICBAD_20ms_PDU07";
BA_ "VFrameFormat" BO_ 382 14;
BA_ "FrameTriggeringName" BO_ 385 "ICBAD_BKPCANFD_20ms_FrP09";
BA_ "GenMsgCycleTime" BO_ 385 20;
BA_ "GenMsgSendType" BO_ 385 0;
BA_ "GenMsgStartValue" BO_ 385 "000003ffffffffff";
BA_ "PduName" BO_ 385 "ICBAD_20ms_PDU09";
BA_ "VFrameFormat" BO_ 385 14;
BA_ "FrameTriggeringName" BO_ 343 "ICBAD_BKPCANFD_20ms_FrP46";
BA_ "GenMsgCycleTime" BO_ 343 20;
BA_ "GenMsgSendType" BO_ 343 0;
BA_ "GenMsgStartValue" BO_ 343 "0020007f1fff0000";
BA_ "PduName" BO_ 343 "ICBAD_20ms_PDU46";
BA_ "VFrameFormat" BO_ 343 14;
BA_ "FrameTriggeringName" BO_ 736 "ICBAD_BKPCANFD_50ms_FrP17";
BA_ "GenMsgCycleTime" BO_ 736 50;
BA_ "GenMsgSendType" BO_ 736 0;
BA_ "GenMsgStartValue" BO_ 736 "0000000000000000000000000000000000000000";
BA_ "PduName" BO_ 736 "ICBAD_50ms_PDU17";
BA_ "VFrameFormat" BO_ 736 14;
BA_ "FrameTriggeringName" BO_ 893 "ICBAD_CHCANFD_100ms_FrP25";
BA_ "GenMsgCycleTime" BO_ 893 100;
BA_ "GenMsgSendType" BO_ 893 0;
BA_ "GenMsgStartValue" BO_ 893 "00f0fffffffffffffffffffffcfcfffcffffffffffffffff";
BA_ "PduName" BO_ 893 "ICBAD_100ms_PDU25";
BA_ "VFrameFormat" BO_ 893 14;
BA_ "FrameTriggeringName" BO_ 314 "ICBAD_CHCANFD_20ms_FrP08";
BA_ "GenMsgCycleTime" BO_ 314 20;
BA_ "GenMsgSendType" BO_ 314 0;
BA_ "GenMsgStartValue" BO_ 314 "0000000000000000";
BA_ "PduName" BO_ 314 "ICBAD_20ms_PDU08";
BA_ "VFrameFormat" BO_ 314 14;
BA_ "FrameTriggeringName" BO_ 360 "ICBAD_CHCANFD_20ms_FrP13";
BA_ "GenMsgCycleTime" BO_ 360 20;
BA_ "GenMsgSendType" BO_ 360 0;
BA_ "GenMsgStartValue" BO_ 360 "00008000fff08fff";
BA_ "PduName" BO_ 360 "ICBAD_20ms_PDU13";
BA_ "VFrameFormat" BO_ 360 14;
BA_ "FrameTriggeringName" BO_ 474 "ICBAD_CHCANFD_20ms_FrP48";
BA_ "GenMsgCycleTime" BO_ 474 20;
BA_ "GenMsgSendType" BO_ 474 0;
BA_ "GenMsgStartValue" BO_ 474 "001000ffff1fffff";
BA_ "PduName" BO_ 474 "ICBAD_20ms_PDU48";
BA_ "VFrameFormat" BO_ 474 14;
BA_ "FrameTriggeringName" BO_ 351 "ICBAD_RZCUCANFD_20ms_FrP05";
BA_ "GenMsgCycleTime" BO_ 351 20;
BA_ "GenMsgSendType" BO_ 351 0;
BA_ "GenMsgStartValue" BO_ 351 "0010ff000400ffff0000ffffffffffffffffffff";
BA_ "PduName" BO_ 351 "ICBAD_20ms_PDU05";
BA_ "VFrameFormat" BO_ 351 14;
BA_ "FrameTriggeringName" BO_ 424 "ICBAD_RZCUCANFD_20ms_FrP12";
BA_ "GenMsgCycleTime" BO_ 424 20;
BA_ "GenMsgSendType" BO_ 424 0;
BA_ "GenMsgStartValue" BO_ 424 "00e01f00ffffffff";
BA_ "PduName" BO_ 424 "ICBAD_20ms_PDU12";
BA_ "VFrameFormat" BO_ 424 14;
BA_ "FrameTriggeringName" BO_ 50 "ICBAD_SecOC_ComKeyResp";
BA_ "GenMsgSendType" BO_ 50 1;
BA_ "GenMsgStartValue" BO_ 50 "0000000000000000";
BA_ "PduName" BO_ 50 "ICBAD_SecOCComKeyResp_PDU01";
BA_ "VFrameFormat" BO_ 50 14;
BA_ "FrameTriggeringName" BO_ 178 "ICBAD_SecOC_Log";
BA_ "GenMsgSendType" BO_ 178 1;
BA_ "GenMsgStartValue" BO_ 178 "0000000000000000";
BA_ "PduName" BO_ 178 "ICBAD_SecOCLog_PDU01";
BA_ "VFrameFormat" BO_ 178 14;
BA_ "FrameTriggeringName" BO_ 81 "ICBAD_ZONE_CHCANFD_20ms_FrP13";
BA_ "GenMsgCycleTime" BO_ 81 20;
BA_ "GenMsgSendType" BO_ 81 0;
BA_ "GenMsgStartValue" BO_ 81 "0010e0036a0fffff";
BA_ "PduName" BO_ 81 "ICBAD_ZONE_20ms_PDU13";
BA_ "VFrameFormat" BO_ 81 14;
BA_ "FrameTriggeringName" BO_ 1282 "ICBVC_BKPCANFD_1000ms_FrP50";
BA_ "GenMsgCycleTime" BO_ 1282 1000;
BA_ "GenMsgSendType" BO_ 1282 0;
BA_ "GenMsgStartValue" BO_ 1282 "ffe3ffff00fff800";
BA_ "PduName" BO_ 1282 "ICBVC_1000ms_PDU50";
BA_ "VFrameFormat" BO_ 1282 14;
BA_ "FrameTriggeringName" BO_ 66 "ICBVC_BKPCANFD_100ms_FrP01";
BA_ "GenMsgCycleTime" BO_ 66 100;
BA_ "GenMsgSendType" BO_ 66 0;
BA_ "GenMsgStartValue" BO_ 66 "00703ffc00fffffffff1111fffffffff";
BA_ "PduName" BO_ 66 "ICBVC_100ms_PDU01";
BA_ "VFrameFormat" BO_ 66 14;
BA_ "FrameTriggeringName" BO_ 871 "ICBVC_BKPCANFD_100ms_FrP17";
BA_ "GenMsgCycleTime" BO_ 871 100;
BA_ "GenMsgSendType" BO_ 871 0;
BA_ "GenMsgStartValue" BO_ 871 "00000000000000fe";
BA_ "PduName" BO_ 871 "ICBVC_100ms_PDU17";
BA_ "VFrameFormat" BO_ 871 14;
BA_ "FrameTriggeringName" BO_ 906 "ICBVC_BKPCANFD_100ms_FrP25";
BA_ "GenMsgCycleTime" BO_ 906 100;
BA_ "GenMsgSendType" BO_ 906 0;
BA_ "GenMsgStartValue" BO_ 906 "000000000000000004020000000000000000000000000000";
BA_ "PduName" BO_ 906 "ICBVC_100ms_PDU25";
BA_ "VFrameFormat" BO_ 906 14;
BA_ "FrameTriggeringName" BO_ 1104 "ICBVC_BKPCANFD_100ms_FrP31";
BA_ "GenMsgCycleTime" BO_ 1104 100;
BA_ "GenMsgSendType" BO_ 1104 0;
BA_ "GenMsgStartValue" BO_ 1104 "0000000000000000000000000000000000000000";
BA_ "PduName" BO_ 1104 "ICBVC_100ms_PDU31";
BA_ "VFrameFormat" BO_ 1104 14;
BA_ "FrameTriggeringName" BO_ 832 "ICBVC_BKPCANFD_100ms_FrP35";
BA_ "GenMsgCycleTime" BO_ 832 100;
BA_ "GenMsgSendType" BO_ 832 0;
BA_ "GenMsgStartValue" BO_ 832 "0000000000000000";
BA_ "PduName" BO_ 832 "ICBVC_100ms_PDU35";
BA_ "VFrameFormat" BO_ 832 14;
BA_ "FrameTriggeringName" BO_ 482 "ICBVC_BKPCANFD_50ms_FrP11";
BA_ "GenMsgCycleTime" BO_ 482 50;
BA_ "GenMsgSendType" BO_ 482 0;
BA_ "GenMsgStartValue" BO_ 482 "0000ffff02c00201";
BA_ "PduName" BO_ 482 "ICBVC_50ms_PDU11";
BA_ "VFrameFormat" BO_ 482 14;
BA_ "FrameTriggeringName" BO_ 1010 "ICBVC_BKPCANFD_50ms_FrP13";
BA_ "GenMsgCycleTime" BO_ 1010 50;
BA_ "GenMsgSendType" BO_ 1010 0;
BA_ "GenMsgStartValue" BO_ 1010 "00f0ffff00f8fff8ffff5fe7ffffffff";
BA_ "PduName" BO_ 1010 "ICBVC_50ms_PDU13";
BA_ "VFrameFormat" BO_ 1010 14;
BA_ "CompuMethodName" SG_ 820 ICBAD_100ms_Group37_CRC "ICBAD_100ms_Group37_CRC";
BA_ "ISignalName" SG_ 820 ICBAD_100ms_Group37_CRC "IICBAD_100ms_Group37_CRC";
BA_ "LongName" SG_ 820 ICBAD_100ms_Group37_CRC "ICBAD_100ms_Group38_CRC";
BA_ "SysSignalName" SG_ 820 ICBAD_100ms_Group37_CRC "ICBAD_100ms_Group37_CRC";
BA_ "CompuMethodName" SG_ 820 ICBAD_100ms_Group37_RC "ICBAD_100ms_Group37_RC";
BA_ "ISignalName" SG_ 820 ICBAD_100ms_Group37_RC "IICBAD_100ms_Group37_RC";
BA_ "LongName" SG_ 820 ICBAD_100ms_Group37_RC "ICBAD_100ms_Group37_RC";
BA_ "SysSignalName" SG_ 820 ICBAD_100ms_Group37_RC "ICBAD_100ms_Group37_RC";
BA_ "CompuMethodName" SG_ 820 ICBAD_100ms_Group37_Reserved1 "ICBAD_100ms_Group37_Reserved1";
BA_ "GenSigStartValue" SG_ 820 ICBAD_100ms_Group37_Reserved1 15;
BA_ "ISignalName" SG_ 820 ICBAD_100ms_Group37_Reserved1 "IICBAD_100ms_Group37_Reserved1";
BA_ "SysSignalName" SG_ 820 ICBAD_100ms_Group37_Reserved1 "ICBAD_100ms_Group37_Reserved1";
BA_ "CompuMethodName" SG_ 820 ICBAD_100ms_Group37_Reserved2 "ICBAD_100ms_Group37_Reserved2";
BA_ "GenSigStartValue" SG_ 820 ICBAD_100ms_Group37_Reserved2 15;
BA_ "ISignalName" SG_ 820 ICBAD_100ms_Group37_Reserved2 "IICBAD_100ms_Group37_Reserved2";
BA_ "SysSignalName" SG_ 820 ICBAD_100ms_Group37_Reserved2 "ICBAD_100ms_Group37_Reserved2";
BA_ "CompuMethodName" SG_ 820 DILampsCtrl "DILampsCtrl";
BA_ "ISignalName" SG_ 820 DILampsCtrl "IDILampsCtrl";
BA_ "LongName" SG_ 820 DILampsCtrl "Direction_Lamps_Control";
BA_ "SysSignalName" SG_ 820 DILampsCtrl "DILampsCtrl";
BA_ "CompuMethodName" SG_ 820 AutoLaneChngSetResp "AutoLaneChngSetResp";
BA_ "ISignalName" SG_ 820 AutoLaneChngSetResp "IAutoLaneChngSetResp";
BA_ "LongName" SG_ 820 AutoLaneChngSetResp "Auto Lane Change Set Response";
BA_ "SysSignalName" SG_ 820 AutoLaneChngSetResp "AutoLaneChngSetResp";
BA_ "CompuMethodName" SG_ 820 ICBAD_100ms_Group37_Reserved4 "ICBAD_100ms_Group37_Reserved4";
BA_ "GenSigStartValue" SG_ 820 ICBAD_100ms_Group37_Reserved4 7;
BA_ "ISignalName" SG_ 820 ICBAD_100ms_Group37_Reserved4 "IICBAD_100ms_Group37_Reserved4";
BA_ "SysSignalName" SG_ 820 ICBAD_100ms_Group37_Reserved4 "ICBAD_100ms_Group37_Reserved4";
BA_ "CompuMethodName" SG_ 820 AutoLaneChngSwDspCmd "AutoLaneChngSwDspCmd";
BA_ "ISignalName" SG_ 820 AutoLaneChngSwDspCmd "IAutoLaneChngSwDspCmd";
BA_ "LongName" SG_ 820 AutoLaneChngSwDspCmd "Auto_Lane_Change_Switch_Display_Command";
BA_ "SysSignalName" SG_ 820 AutoLaneChngSwDspCmd "AutoLaneChngSwDspCmd";
BA_ "CompuMethodName" SG_ 820 ICBAD_100ms_Group37_Reserved3 "ICBAD_100ms_Group37_Reserved3";
BA_ "GenSigStartValue" SG_ 820 ICBAD_100ms_Group37_Reserved3 15;
BA_ "ISignalName" SG_ 820 ICBAD_100ms_Group37_Reserved3 "IICBAD_100ms_Group37_Reserved3";
BA_ "SysSignalName" SG_ 820 ICBAD_100ms_Group37_Reserved3 "ICBAD_100ms_Group37_Reserved3";
BA_ "CompuMethodName" SG_ 820 ICBAD_100ms_Group37_Reserved5 "ICBAD_100ms_Group37_Reserved5";
BA_ "GenSigStartValue" SG_ 820 ICBAD_100ms_Group37_Reserved5 1;
BA_ "ISignalName" SG_ 820 ICBAD_100ms_Group37_Reserved5 "IICBAD_100ms_Group37_Reserved5";
BA_ "SysSignalName" SG_ 820 ICBAD_100ms_Group37_Reserved5 "ICBAD_100ms_Group37_Reserved5";
BA_ "CompuMethodName" SG_ 820 AutoLaneChngMsgReq "AutoLaneChngMsgReq";
BA_ "ISignalName" SG_ 820 AutoLaneChngMsgReq "IAutoLaneChngMsgReq";
BA_ "LongName" SG_ 820 AutoLaneChngMsgReq "Auto Lane Change Message Request";
BA_ "SysSignalName" SG_ 820 AutoLaneChngMsgReq "AutoLaneChngMsgReq";
BA_ "CompuMethodName" SG_ 820 ICBAD_100ms_Group37_Reserved6 "ICBAD_100ms_Group37_Reserved6";
BA_ "GenSigStartValue" SG_ 820 ICBAD_100ms_Group37_Reserved6 63;
BA_ "ISignalName" SG_ 820 ICBAD_100ms_Group37_Reserved6 "IICBAD_100ms_Group37_Reserved6";
BA_ "SysSignalName" SG_ 820 ICBAD_100ms_Group37_Reserved6 "ICBAD_100ms_Group37_Reserved6";
BA_ "CompuMethodName" SG_ 820 HzrdLampsCtrl "HzrdLampsCtrl";
BA_ "ISignalName" SG_ 820 HzrdLampsCtrl "IHzrdLampsCtrl";
BA_ "LongName" SG_ 820 HzrdLampsCtrl "Hazard Lamps Control";
BA_ "SysSignalName" SG_ 820 HzrdLampsCtrl "HzrdLampsCtrl";
BA_ "CompuMethodName" SG_ 820 ICBAD_100ms_Group37_Reserved7 "ICBAD_100ms_Group37_Reserved7";
BA_ "GenSigStartValue" SG_ 820 ICBAD_100ms_Group37_Reserved7 255;
BA_ "ISignalName" SG_ 820 ICBAD_100ms_Group37_Reserved7 "IICBAD_100ms_Group37_Reserved7";
BA_ "SysSignalName" SG_ 820 ICBAD_100ms_Group37_Reserved7 "ICBAD_100ms_Group37_Reserved7";
BA_ "CompuMethodName" SG_ 820 ICBAD_100ms_Group37_Reserved8 "ICBAD_100ms_Group37_Reserved8";
BA_ "GenSigStartValue" SG_ 820 ICBAD_100ms_Group37_Reserved8 255;
BA_ "ISignalName" SG_ 820 ICBAD_100ms_Group37_Reserved8 "IICBAD_100ms_Group37_Reserved8";
BA_ "SysSignalName" SG_ 820 ICBAD_100ms_Group37_Reserved8 "ICBAD_100ms_Group37_Reserved8";
BA_ "CompuMethodName" SG_ 1105 ELKSysFltSts "ELKSysFltSts";
BA_ "ISignalName" SG_ 1105 ELKSysFltSts "IELKSysFltSts";
BA_ "LongName" SG_ 1105 ELKSysFltSts "ELK System fault status";
BA_ "SysSignalName" SG_ 1105 ELKSysFltSts "ELKSysFltSts";
BA_ "CompuMethodName" SG_ 1105 NrwroadFwdSta "NrwroadFwdSta";
BA_ "ISignalName" SG_ 1105 NrwroadFwdSta "INrwroadFwdSta";
BA_ "LongName" SG_ 1105 NrwroadFwdSta "Narrow Road Forward Switch Response Status";
BA_ "SysSignalName" SG_ 1105 NrwroadFwdSta "NrwroadFwdSta";
BA_ "CompuMethodName" SG_ 1105 NrwroadsltSta "NrwroadsltSta";
BA_ "ISignalName" SG_ 1105 NrwroadsltSta "INrwroadsltSta";
BA_ "LongName" SG_ 1105 NrwroadsltSta "Narrow Road Forward Silently Status";
BA_ "SysSignalName" SG_ 1105 NrwroadsltSta "NrwroadsltSta";
BA_ "CompuMethodName" SG_ 1105 ELKDspCmd "ELKDspCmd";
BA_ "ISignalName" SG_ 1105 ELKDspCmd "IELKDspCmd";
BA_ "LongName" SG_ 1105 ELKDspCmd "ELK Display command";
BA_ "SysSignalName" SG_ 1105 ELKDspCmd "ELKDspCmd";
BA_ "CompuMethodName" SG_ 1105 MemParkngBtnRcnm "MemParkngBtnRcnm";
BA_ "ISignalName" SG_ 1105 MemParkngBtnRcnm "IMemParkngBtnRcnm";
BA_ "LongName" SG_ 1105 MemParkngBtnRcnm "Memory Parking Button Recommand";
BA_ "SysSignalName" SG_ 1105 MemParkngBtnRcnm "MemParkngBtnRcnm";
BA_ "CompuMethodName" SG_ 1106 NarrowRoadForwardSts "NarrowRoadForwardSts";
BA_ "ISignalName" SG_ 1106 NarrowRoadForwardSts "INarrowRoadForwardSts";
BA_ "LongName" SG_ 1106 NarrowRoadForwardSts "Narrow Road Forward Switch Status";
BA_ "SysSignalName" SG_ 1106 NarrowRoadForwardSts "NarrowRoadForwardSts";
BA_ "CompuMethodName" SG_ 1106 NarrowRoadBackwardSts "NarrowRoadBackwardSts";
BA_ "ISignalName" SG_ 1106 NarrowRoadBackwardSts "INarrowRoadBackwardSts";
BA_ "LongName" SG_ 1106 NarrowRoadBackwardSts "Narrow Road Backward Status";
BA_ "SysSignalName" SG_ 1106 NarrowRoadBackwardSts "NarrowRoadBackwardSts";
BA_ "CompuMethodName" SG_ 1106 TrfcLghtStSp "TrfcLghtStSp";
BA_ "ISignalName" SG_ 1106 TrfcLghtStSp "ITrfcLghtStSp";
BA_ "LongName" SG_ 1106 TrfcLghtStSp "Traffic Light Start/Stop Status";
BA_ "SysSignalName" SG_ 1106 TrfcLghtStSp "TrfcLghtStSp";
BA_ "CompuMethodName" SG_ 151 AIParkngEPAMdsts "AIParkngEPAMdsts";
BA_ "ISignalName" SG_ 151 AIParkngEPAMdsts "IAIParkngEPAMdsts";
BA_ "LongName" SG_ 151 AIParkngEPAMdsts "AIParking Exterior Parking Assist Model Status";
BA_ "SysSignalName" SG_ 151 AIParkngEPAMdsts "AIParkngEPAMdsts";
BA_ "CompuMethodName" SG_ 151 D2DSwReqResps "D2DSwReqResps";
BA_ "ISignalName" SG_ 151 D2DSwReqResps "ID2DSwReqResps";
BA_ "LongName" SG_ 151 D2DSwReqResps "D2D Swicth Request Response";
BA_ "SysSignalName" SG_ 151 D2DSwReqResps "D2DSwReqResps";
BA_ "CompuMethodName" SG_ 151 FCTBSysFltSts "FCTBSysFltSts";
BA_ "ISignalName" SG_ 151 FCTBSysFltSts "IFCTBSysFltSts";
BA_ "LongName" SG_ 151 FCTBSysFltSts "FCTB System Fault status";
BA_ "SysSignalName" SG_ 151 FCTBSysFltSts "FCTBSysFltSts";
BA_ "CompuMethodName" SG_ 151 D2DPriETClanSwReqResps "D2DPriETClanSwReqResps";
BA_ "ISignalName" SG_ 151 D2DPriETClanSwReqResps "ID2DPriETClanSwReqResps";
BA_ "LongName" SG_ 151 D2DPriETClanSwReqResps "D2D Priority ETC Lane Switch Request Response";
BA_ "SysSignalName" SG_ 151 D2DPriETClanSwReqResps "D2DPriETClanSwReqResps";
BA_ "CompuMethodName" SG_ 382 ICBAD_20ms_Group07_CRC "ICBAD_20ms_Group07_CRC";
BA_ "ISignalName" SG_ 382 ICBAD_20ms_Group07_CRC "IICBAD_20ms_Group07_CRC";
BA_ "LongName" SG_ 382 ICBAD_20ms_Group07_CRC "ICBAD_20ms_Group07_CRC";
BA_ "SysSignalName" SG_ 382 ICBAD_20ms_Group07_CRC "ICBAD_20ms_Group07_CRC";
BA_ "CompuMethodName" SG_ 382 ICBAD_20ms_Group07_RC "ICBAD_20ms_Group07_RC";
BA_ "ISignalName" SG_ 382 ICBAD_20ms_Group07_RC "IICBAD_20ms_Group07_RC";
BA_ "LongName" SG_ 382 ICBAD_20ms_Group07_RC "ICBAD_20ms_Group07_RC";
BA_ "SysSignalName" SG_ 382 ICBAD_20ms_Group07_RC "ICBAD_20ms_Group07_RC";
BA_ "CompuMethodName" SG_ 382 ACCSdslReq "ACCSdslReq";
BA_ "ISignalName" SG_ 382 ACCSdslReq "IACCSdslReq";
BA_ "LongName" SG_ 382 ACCSdslReq "Adaptive Cruise Control Standstill Request";
BA_ "SysSignalName" SG_ 382 ACCSdslReq "ACCSdslReq";
BA_ "CompuMethodName" SG_ 382 ACCGoReq "ACCGoReq";
BA_ "ISignalName" SG_ 382 ACCGoReq "IACCGoReq";
BA_ "LongName" SG_ 382 ACCGoReq "Adaptive Cruise Control Go Request";
BA_ "SysSignalName" SG_ 382 ACCGoReq "ACCGoReq";
BA_ "CompuMethodName" SG_ 382 ACCAccReqSts_CH "ACCAccReqSts_CH";
BA_ "ISignalName" SG_ 382 ACCAccReqSts_CH "IACCAccReqSts_CH";
BA_ "LongName" SG_ 382 ACCAccReqSts_CH "Adaptive Cruise Control Acceleration Request Status";
BA_ "SysSignalName" SG_ 382 ACCAccReqSts_CH "ACCAccReqSts_CH";
BA_ "CompuMethodName" SG_ 382 ACCAccReqVal "ACCAccReqVal";
BA_ "GenSigStartValue" SG_ 382 ACCAccReqVal 1713;
BA_ "ISignalName" SG_ 382 ACCAccReqVal "IACCAccReqVal";
BA_ "LongName" SG_ 382 ACCAccReqVal "Adaptive Cruise Control Acceleration Request Value";
BA_ "SysSignalName" SG_ 382 ACCAccReqVal "ACCAccReqVal";
BA_ "CompuMethodName" SG_ 382 APAEPBOPReq "APAEPBOPReq";
BA_ "ISignalName" SG_ 382 APAEPBOPReq "IAPAEPBOPReq";
BA_ "LongName" SG_ 382 APAEPBOPReq "Advanced Park Assist Electric Park Brake Operation Request";
BA_ "SysSignalName" SG_ 382 APAEPBOPReq "APAEPBOPReq";
BA_ "CompuMethodName" SG_ 382 ACCSysFltSts "ACCSysFltSts";
BA_ "ISignalName" SG_ 382 ACCSysFltSts "IACCSysFltSts";
BA_ "LongName" SG_ 382 ACCSysFltSts "Adaptive Cruise Control System Fault Status";
BA_ "SysSignalName" SG_ 382 ACCSysFltSts "ACCSysFltSts";
BA_ "CompuMethodName" SG_ 382 AIPkgAPASCSAcclReqVal "AIPkgAPASCSAcclReqVal";
BA_ "ISignalName" SG_ 382 AIPkgAPASCSAcclReqVal "IAIPkgAPASCSAcclReqVal";
BA_ "LongName" SG_ 382 AIPkgAPASCSAcclReqVal "Ai Parking APA Acceleration Request Value";
BA_ "SysSignalName" SG_ 382 AIPkgAPASCSAcclReqVal "AIPkgAPASCSAcclReqVal";
BA_ "CompuMethodName" SG_ 382 ACCSysSts "ACCSysSts";
BA_ "ISignalName" SG_ 382 ACCSysSts "IACCSysSts";
BA_ "LongName" SG_ 382 ACCSysSts "Adaptive Cruise Control System Status";
BA_ "SysSignalName" SG_ 382 ACCSysSts "ACCSysSts";
BA_ "CompuMethodName" SG_ 382 APASCSAcclReqSts "APASCSAcclReqSts";
BA_ "ISignalName" SG_ 382 APASCSAcclReqSts "IAPASCSAcclReqSts";
BA_ "LongName" SG_ 382 APASCSAcclReqSts "Advanced Park Assist Stability Control System Acceleration Request Status";
BA_ "SysSignalName" SG_ 382 APASCSAcclReqSts "APASCSAcclReqSts";
BA_ "CompuMethodName" SG_ 382 APAEPBOPReqV "APAEPBOPReqV";
BA_ "ISignalName" SG_ 382 APAEPBOPReqV "IAPAEPBOPReqV";
BA_ "LongName" SG_ 382 APAEPBOPReqV "Advanced Park Assist Electric Park Brake Operation Request Validity";
BA_ "SysSignalName" SG_ 382 APAEPBOPReqV "APAEPBOPReqV";
BA_ "CompuMethodName" SG_ 382 AutodDrvngSysSCSSdslReqV "AutodDrvngSysSCSSdslReqV";
BA_ "ISignalName" SG_ 382 AutodDrvngSysSCSSdslReqV "IAutodDrvngSysSCSSdslReqV";
BA_ "LongName" SG_ 382 AutodDrvngSysSCSSdslReqV "Automated Driving System Stability Control System Standstill Request Validity";
BA_ "SysSignalName" SG_ 382 AutodDrvngSysSCSSdslReqV "AutodDrvngSysSCSSdslReqV";
BA_ "CompuMethodName" SG_ 382 AutodDrvngSysSCSSdslReq "AutodDrvngSysSCSSdslReq";
BA_ "ISignalName" SG_ 382 AutodDrvngSysSCSSdslReq "IAutodDrvngSysSCSSdslReq";
BA_ "LongName" SG_ 382 AutodDrvngSysSCSSdslReq "Automated Driving System Stability Control System Standstill Request";
BA_ "SysSignalName" SG_ 382 AutodDrvngSysSCSSdslReq "AutodDrvngSysSCSSdslReq";
BA_ "CompuMethodName" SG_ 382 AutodDrvngSysEmgcBrkReqV "AutodDrvngSysEmgcBrkReqV";
BA_ "ISignalName" SG_ 382 AutodDrvngSysEmgcBrkReqV "IAutodDrvngSysEmgcBrkReqV";
BA_ "LongName" SG_ 382 AutodDrvngSysEmgcBrkReqV "Automated_Driving_System_Emergency_Brake_Request_Validity";
BA_ "SysSignalName" SG_ 382 AutodDrvngSysEmgcBrkReqV "AutodDrvngSysEmgcBrkReqV";
BA_ "CompuMethodName" SG_ 382 AutodDrvngSysEmgcBrkReq "AutodDrvngSysEmgcBrkReq";
BA_ "ISignalName" SG_ 382 AutodDrvngSysEmgcBrkReq "IAutodDrvngSysEmgcBrkReq";
BA_ "LongName" SG_ 382 AutodDrvngSysEmgcBrkReq "Automated_Driving_System_Emergency_Brake_Request";
BA_ "SysSignalName" SG_ 382 AutodDrvngSysEmgcBrkReq "AutodDrvngSysEmgcBrkReq";
BA_ "CompuMethodName" SG_ 382 ICBAD_20ms_Group07_Reserved1 "ICBAD_20ms_Group07_Reserved1";
BA_ "GenSigStartValue" SG_ 382 ICBAD_20ms_Group07_Reserved1 15;
BA_ "ISignalName" SG_ 382 ICBAD_20ms_Group07_Reserved1 "IICBAD_20ms_Group07_Reserved1";
BA_ "SysSignalName" SG_ 382 ICBAD_20ms_Group07_Reserved1 "ICBAD_20ms_Group07_Reserved1";
BA_ "CompuMethodName" SG_ 382 AutodDrvngSysSCSDrvOffReqV "AutodDrvngSysSCSDrvOffReqV";
BA_ "ISignalName" SG_ 382 AutodDrvngSysSCSDrvOffReqV "IAutodDrvngSysSCSDrvOffReqV";
BA_ "LongName" SG_ 382 AutodDrvngSysSCSDrvOffReqV "Automated Driving System Stability Control System Drive Off Request Validity";
BA_ "SysSignalName" SG_ 382 AutodDrvngSysSCSDrvOffReqV "AutodDrvngSysSCSDrvOffReqV";
BA_ "CompuMethodName" SG_ 382 AutodDrvngSysSCSDrvOffReq "AutodDrvngSysSCSDrvOffReq";
BA_ "ISignalName" SG_ 382 AutodDrvngSysSCSDrvOffReq "IAutodDrvngSysSCSDrvOffReq";
BA_ "LongName" SG_ 382 AutodDrvngSysSCSDrvOffReq "Automated Driving System Stability Control System Drive Off Request";
BA_ "SysSignalName" SG_ 382 AutodDrvngSysSCSDrvOffReq "AutodDrvngSysSCSDrvOffReq";
BA_ "CompuMethodName" SG_ 382 AutodDrvngSysMdReqV "AutodDrvngSysMdReqV";
BA_ "ISignalName" SG_ 382 AutodDrvngSysMdReqV "IAutodDrvngSysMdReqV";
BA_ "LongName" SG_ 382 AutodDrvngSysMdReqV "Automated Driving System Mode Request Validity";
BA_ "SysSignalName" SG_ 382 AutodDrvngSysMdReqV "AutodDrvngSysMdReqV";
BA_ "CompuMethodName" SG_ 382 AutodDrvngSysMdReq "AutodDrvngSysMdReq";
BA_ "ISignalName" SG_ 382 AutodDrvngSysMdReq "IAutodDrvngSysMdReq";
BA_ "LongName" SG_ 382 AutodDrvngSysMdReq "Automated Driving System Mode Request";
BA_ "SysSignalName" SG_ 382 AutodDrvngSysMdReq "AutodDrvngSysMdReq";
BA_ "CompuMethodName" SG_ 382 AutodDrvngSysFlrStsV "AutodDrvngSysFlrStsV";
BA_ "ISignalName" SG_ 382 AutodDrvngSysFlrStsV "IAutodDrvngSysFlrStsV";
BA_ "LongName" SG_ 382 AutodDrvngSysFlrStsV "Automated Driving System Failure Status Validity";
BA_ "SysSignalName" SG_ 382 AutodDrvngSysFlrStsV "AutodDrvngSysFlrStsV";
BA_ "CompuMethodName" SG_ 382 AutodDrvngSysFlrSts "AutodDrvngSysFlrSts";
BA_ "ISignalName" SG_ 382 AutodDrvngSysFlrSts "IAutodDrvngSysFlrSts";
BA_ "LongName" SG_ 382 AutodDrvngSysFlrSts "Automated Driving System Failure Status";
BA_ "SysSignalName" SG_ 382 AutodDrvngSysFlrSts "AutodDrvngSysFlrSts";
BA_ "CompuMethodName" SG_ 385 ICBAD_20ms_Group09_CRC "ICBAD_20ms_Group09_CRC";
BA_ "ISignalName" SG_ 385 ICBAD_20ms_Group09_CRC "IICBAD_20ms_Group09_CRC";
BA_ "LongName" SG_ 385 ICBAD_20ms_Group09_CRC "ICBAD_20ms_Group09_CRC";
BA_ "SysSignalName" SG_ 385 ICBAD_20ms_Group09_CRC "ICBAD_20ms_Group09_CRC";
BA_ "CompuMethodName" SG_ 385 ICBAD_20ms_Group09_RC "ICBAD_20ms_Group09_RC";
BA_ "ISignalName" SG_ 385 ICBAD_20ms_Group09_RC "IICBAD_20ms_Group09_RC";
BA_ "LongName" SG_ 385 ICBAD_20ms_Group09_RC "ICBAD_20ms_Group09_RC";
BA_ "SysSignalName" SG_ 385 ICBAD_20ms_Group09_RC "ICBAD_20ms_Group09_RC";
BA_ "CompuMethodName" SG_ 385 NSAReqAVMDis "NSAReqAVMDis";
BA_ "ISignalName" SG_ 385 NSAReqAVMDis "INSAReqAVMDis";
BA_ "LongName" SG_ 385 NSAReqAVMDis "NSA Request AVM Display";
BA_ "SysSignalName" SG_ 385 NSAReqAVMDis "NSAReqAVMDis";
BA_ "CompuMethodName" SG_ 385 NSADisFucSts "NSADisFucSts";
BA_ "ISignalName" SG_ 385 NSADisFucSts "INSADisFucSts";
BA_ "LongName" SG_ 385 NSADisFucSts "NSA Display Function Status";
BA_ "SysSignalName" SG_ 385 NSADisFucSts "NSADisFucSts";
BA_ "CompuMethodName" SG_ 385 ICBAD_20ms_Group09_Reserved1 "ICBAD_20ms_Group09_Reserved1";
BA_ "GenSigStartValue" SG_ 385 ICBAD_20ms_Group09_Reserved1 3;
BA_ "ISignalName" SG_ 385 ICBAD_20ms_Group09_Reserved1 "IICBAD_20ms_Group09_Reserved1";
BA_ "SysSignalName" SG_ 385 ICBAD_20ms_Group09_Reserved1 "ICBAD_20ms_Group09_Reserved1";
BA_ "CompuMethodName" SG_ 385 NSABacSysSts "NSABacSysSts";
BA_ "ISignalName" SG_ 385 NSABacSysSts "INSABacSysSts";
BA_ "LongName" SG_ 385 NSABacSysSts "NSA Backward Systerm Status";
BA_ "SysSignalName" SG_ 385 NSABacSysSts "NSABacSysSts";
BA_ "CompuMethodName" SG_ 385 NSAForSysSts "NSAForSysSts";
BA_ "ISignalName" SG_ 385 NSAForSysSts "INSAForSysSts";
BA_ "LongName" SG_ 385 NSAForSysSts "NSA Forward Systerm Status";
BA_ "SysSignalName" SG_ 385 NSAForSysSts "NSAForSysSts";
BA_ "CompuMethodName" SG_ 385 ICBAD_20ms_Group09_Reserved2 "ICBAD_20ms_Group09_Reserved2";
BA_ "GenSigStartValue" SG_ 385 ICBAD_20ms_Group09_Reserved2 255;
BA_ "ISignalName" SG_ 385 ICBAD_20ms_Group09_Reserved2 "IICBAD_20ms_Group09_Reserved2";
BA_ "SysSignalName" SG_ 385 ICBAD_20ms_Group09_Reserved2 "ICBAD_20ms_Group09_Reserved2";
BA_ "CompuMethodName" SG_ 385 ICBAD_20ms_Group09_Reserved3 "ICBAD_20ms_Group09_Reserved3";
BA_ "GenSigStartValue" SG_ 385 ICBAD_20ms_Group09_Reserved3 255;
BA_ "ISignalName" SG_ 385 ICBAD_20ms_Group09_Reserved3 "IICBAD_20ms_Group09_Reserved3";
BA_ "SysSignalName" SG_ 385 ICBAD_20ms_Group09_Reserved3 "ICBAD_20ms_Group09_Reserved3";
BA_ "CompuMethodName" SG_ 385 ICBAD_20ms_Group09_Reserved4 "ICBAD_20ms_Group09_Reserved4";
BA_ "GenSigStartValue" SG_ 385 ICBAD_20ms_Group09_Reserved4 255;
BA_ "ISignalName" SG_ 385 ICBAD_20ms_Group09_Reserved4 "IICBAD_20ms_Group09_Reserved4";
BA_ "SysSignalName" SG_ 385 ICBAD_20ms_Group09_Reserved4 "ICBAD_20ms_Group09_Reserved4";
BA_ "CompuMethodName" SG_ 385 ICBAD_20ms_Group09_Reserved5 "ICBAD_20ms_Group09_Reserved5";
BA_ "GenSigStartValue" SG_ 385 ICBAD_20ms_Group09_Reserved5 255;
BA_ "ISignalName" SG_ 385 ICBAD_20ms_Group09_Reserved5 "IICBAD_20ms_Group09_Reserved5";
BA_ "SysSignalName" SG_ 385 ICBAD_20ms_Group09_Reserved5 "ICBAD_20ms_Group09_Reserved5";
BA_ "CompuMethodName" SG_ 385 ICBAD_20ms_Group09_Reserved6 "ICBAD_20ms_Group09_Reserved6";
BA_ "GenSigStartValue" SG_ 385 ICBAD_20ms_Group09_Reserved6 255;
BA_ "ISignalName" SG_ 385 ICBAD_20ms_Group09_Reserved6 "IICBAD_20ms_Group09_Reserved6";
BA_ "SysSignalName" SG_ 385 ICBAD_20ms_Group09_Reserved6 "ICBAD_20ms_Group09_Reserved6";
BA_ "CompuMethodName" SG_ 343 ICBAD_20ms_Group46_CRC "ICBAD_20ms_Group46_CRC";
BA_ "ISignalName" SG_ 343 ICBAD_20ms_Group46_CRC "IICBAD_20ms_Group46_CRC";
BA_ "LongName" SG_ 343 ICBAD_20ms_Group46_CRC "ICBAD_20ms_Group46_CRC";
BA_ "SysSignalName" SG_ 343 ICBAD_20ms_Group46_CRC "ICBAD_20ms_Group46_CRC";
BA_ "CompuMethodName" SG_ 343 ICBAD_20ms_Group46_RC "ICBAD_20ms_Group46_RC";
BA_ "ISignalName" SG_ 343 ICBAD_20ms_Group46_RC "IICBAD_20ms_Group46_RC";
BA_ "LongName" SG_ 343 ICBAD_20ms_Group46_RC "ICBAD_20ms_Group46_RC";
BA_ "SysSignalName" SG_ 343 ICBAD_20ms_Group46_RC "ICBAD_20ms_Group46_RC";
BA_ "CompuMethodName" SG_ 343 AEBPrflReq "AEBPrflReq";
BA_ "ISignalName" SG_ 343 AEBPrflReq "IAEBPrflReq";
BA_ "LongName" SG_ 343 AEBPrflReq "Autonomous Emergency Braking Prefill Request";
BA_ "SysSignalName" SG_ 343 AEBPrflReq "AEBPrflReq";
BA_ "CompuMethodName" SG_ 343 AEBSysSts "AEBSysSts";
BA_ "GenSigStartValue" SG_ 343 AEBSysSts 1;
BA_ "ISignalName" SG_ 343 AEBSysSts "IAEBSysSts";
BA_ "LongName" SG_ 343 AEBSysSts "Autonomous Emergency Braking System Status";
BA_ "SysSignalName" SG_ 343 AEBSysSts "AEBSysSts";
BA_ "CompuMethodName" SG_ 343 AEBDclReqSts "AEBDclReqSts";
BA_ "ISignalName" SG_ 343 AEBDclReqSts "IAEBDclReqSts";
BA_ "LongName" SG_ 343 AEBDclReqSts "Autonomous Emergency Braking Deceleration Request Status";
BA_ "SysSignalName" SG_ 343 AEBDclReqSts "AEBDclReqSts";
BA_ "CompuMethodName" SG_ 343 AEBBrkJerkLvlReq "AEBBrkJerkLvlReq";
BA_ "ISignalName" SG_ 343 AEBBrkJerkLvlReq "IAEBBrkJerkLvlReq";
BA_ "LongName" SG_ 343 AEBBrkJerkLvlReq "Autonomous Emergency Braking Brake Jerk Level Request";
BA_ "SysSignalName" SG_ 343 AEBBrkJerkLvlReq "AEBBrkJerkLvlReq";
BA_ "CompuMethodName" SG_ 343 AEBHydBrkAstLvlReq "AEBHydBrkAstLvlReq";
BA_ "ISignalName" SG_ 343 AEBHydBrkAstLvlReq "IAEBHydBrkAstLvlReq";
BA_ "LongName" SG_ 343 AEBHydBrkAstLvlReq "Autonomous Emergency Braking Hydraulic Brake Assist Level Request";
BA_ "SysSignalName" SG_ 343 AEBHydBrkAstLvlReq "AEBHydBrkAstLvlReq";
BA_ "CompuMethodName" SG_ 343 AEBDclReqVal "AEBDclReqVal";
BA_ "GenSigStartValue" SG_ 343 AEBDclReqVal 127;
BA_ "ISignalName" SG_ 343 AEBDclReqVal "IAEBDclReqVal";
BA_ "LongName" SG_ 343 AEBDclReqVal "Autonomous Emergency Braking Deceleration Request Value";
BA_ "SysSignalName" SG_ 343 AEBDclReqVal "AEBDclReqVal";
BA_ "CompuMethodName" SG_ 343 ICBAD_20ms_Group46_Reserved1 "ICBAD_20ms_Group46_Reserved1";
BA_ "GenSigStartValue" SG_ 343 ICBAD_20ms_Group46_Reserved1 31;
BA_ "ISignalName" SG_ 343 ICBAD_20ms_Group46_Reserved1 "IICBAD_20ms_Group46_Reserved1";
BA_ "SysSignalName" SG_ 343 ICBAD_20ms_Group46_Reserved1 "ICBAD_20ms_Group46_Reserved1";
BA_ "CompuMethodName" SG_ 343 AEBSysFltSts "AEBSysFltSts";
BA_ "ISignalName" SG_ 343 AEBSysFltSts "IAEBSysFltSts";
BA_ "LongName" SG_ 343 AEBSysFltSts "Autonomous Emergency Braking System Fault Status";
BA_ "SysSignalName" SG_ 343 AEBSysFltSts "AEBSysFltSts";
BA_ "CompuMethodName" SG_ 343 ICBAD_20ms_Group46_Reserved2 "ICBAD_20ms_Group46_Reserved2";
BA_ "GenSigStartValue" SG_ 343 ICBAD_20ms_Group46_Reserved2 255;
BA_ "ISignalName" SG_ 343 ICBAD_20ms_Group46_Reserved2 "IICBAD_20ms_Group46_Reserved2";
BA_ "SysSignalName" SG_ 343 ICBAD_20ms_Group46_Reserved2 "ICBAD_20ms_Group46_Reserved2";
BA_ "CompuMethodName" SG_ 343 AEBDclReqToqVal "AEBDclReqToqVal";
BA_ "ISignalName" SG_ 343 AEBDclReqToqVal "IAEBDclReqToqVal";
BA_ "LongName" SG_ 343 AEBDclReqToqVal "Autonomous Emergency Braking Deceleration Request Torque Value";
BA_ "SysSignalName" SG_ 343 AEBDclReqToqVal "AEBDclReqToqVal";
BA_ "CompuMethodName" SG_ 736 FrtObsDist "FrtObsDist";
BA_ "ISignalName" SG_ 736 FrtObsDist "IFrtObsDist";
BA_ "LongName" SG_ 736 FrtObsDist "Front Obstacle Distance";
BA_ "SysSignalName" SG_ 736 FrtObsDist "FrtObsDist";
BA_ "CompuMethodName" SG_ 736 FrtMidRObsRng "FrtMidRObsRng";
BA_ "ISignalName" SG_ 736 FrtMidRObsRng "IFrtMidRObsRng";
BA_ "LongName" SG_ 736 FrtMidRObsRng "Front Middle Right Obstacle Range";
BA_ "SysSignalName" SG_ 736 FrtMidRObsRng "FrtMidRObsRng";
BA_ "CompuMethodName" SG_ 736 FrtPDCAudWrnng "FrtPDCAudWrnng";
BA_ "ISignalName" SG_ 736 FrtPDCAudWrnng "IFrtPDCAudWrnng";
BA_ "LongName" SG_ 736 FrtPDCAudWrnng "Front Park Distance Control Audible Warning";
BA_ "SysSignalName" SG_ 736 FrtPDCAudWrnng "FrtPDCAudWrnng";
BA_ "CompuMethodName" SG_ 736 RrMidLObsRng "RrMidLObsRng";
BA_ "ISignalName" SG_ 736 RrMidLObsRng "IRrMidLObsRng";
BA_ "LongName" SG_ 736 RrMidLObsRng "Rear_Middle_Left_Obstacle_Range";
BA_ "SysSignalName" SG_ 736 RrMidLObsRng "RrMidLObsRng";
BA_ "CompuMethodName" SG_ 736 RLObsRng "RLObsRng";
BA_ "ISignalName" SG_ 736 RLObsRng "IRLObsRng";
BA_ "LongName" SG_ 736 RLObsRng "Rear Left Obstacle Range";
BA_ "SysSignalName" SG_ 736 RLObsRng "RLObsRng";
BA_ "CompuMethodName" SG_ 736 RrMidRObsRng "RrMidRObsRng";
BA_ "ISignalName" SG_ 736 RrMidRObsRng "IRrMidRObsRng";
BA_ "LongName" SG_ 736 RrMidRObsRng "Rear Middle Right Obstacle Range";
BA_ "SysSignalName" SG_ 736 RrMidRObsRng "RrMidRObsRng";
BA_ "CompuMethodName" SG_ 736 PDCSysSts "PDCSysSts";
BA_ "ISignalName" SG_ 736 PDCSysSts "IPDCSysSts";
BA_ "LongName" SG_ 736 PDCSysSts "Park Distance Control System Status";
BA_ "SysSignalName" SG_ 736 PDCSysSts "PDCSysSts";
BA_ "CompuMethodName" SG_ 736 RrObsDist "RrObsDist";
BA_ "ISignalName" SG_ 736 RrObsDist "IRrObsDist";
BA_ "LongName" SG_ 736 RrObsDist "Rear Right Obstacle Distance";
BA_ "SysSignalName" SG_ 736 RrObsDist "RrObsDist";
BA_ "CompuMethodName" SG_ 736 FLSideObsRng "FLSideObsRng";
BA_ "ISignalName" SG_ 736 FLSideObsRng "IFLSideObsRng";
BA_ "LongName" SG_ 736 FLSideObsRng "Front Left Side Obstacle Distance";
BA_ "SysSignalName" SG_ 736 FLSideObsRng "FLSideObsRng";
BA_ "CompuMethodName" SG_ 736 RrPDCAudWrnng "RrPDCAudWrnng";
BA_ "ISignalName" SG_ 736 RrPDCAudWrnng "IRrPDCAudWrnng";
BA_ "LongName" SG_ 736 RrPDCAudWrnng "Body Control Module Rear Park Distance Control Audible Warning";
BA_ "SysSignalName" SG_ 736 RrPDCAudWrnng "RrPDCAudWrnng";
BA_ "CompuMethodName" SG_ 736 RLSideObsRng "RLSideObsRng";
BA_ "ISignalName" SG_ 736 RLSideObsRng "IRLSideObsRng";
BA_ "LongName" SG_ 736 RLSideObsRng "Rear Left Side Obstacle Distance";
BA_ "SysSignalName" SG_ 736 RLSideObsRng "RLSideObsRng";
BA_ "CompuMethodName" SG_ 736 FRSideObsRng "FRSideObsRng";
BA_ "ISignalName" SG_ 736 FRSideObsRng "IFRSideObsRng";
BA_ "LongName" SG_ 736 FRSideObsRng "Front Right Side Obstacle Distance";
BA_ "SysSignalName" SG_ 736 FRSideObsRng "FRSideObsRng";
BA_ "CompuMethodName" SG_ 736 RRSideObsRng "RRSideObsRng";
BA_ "ISignalName" SG_ 736 RRSideObsRng "IRRSideObsRng";
BA_ "LongName" SG_ 736 RRSideObsRng "Rear Right Side Obstacle Distance";
BA_ "SysSignalName" SG_ 736 RRSideObsRng "RRSideObsRng";
BA_ "CompuMethodName" SG_ 736 FLObsRng "FLObsRng";
BA_ "ISignalName" SG_ 736 FLObsRng "IFLObsRng";
BA_ "LongName" SG_ 736 FLObsRng "Front Left Obstacle Range";
BA_ "SysSignalName" SG_ 736 FLObsRng "FLObsRng";
BA_ "CompuMethodName" SG_ 736 RRObsRng "RRObsRng";
BA_ "ISignalName" SG_ 736 RRObsRng "IRRObsRng";
BA_ "LongName" SG_ 736 RRObsRng "Rear Right Obstacle Range";
BA_ "SysSignalName" SG_ 736 RRObsRng "RRObsRng";
BA_ "CompuMethodName" SG_ 736 FRObsRng "FRObsRng";
BA_ "ISignalName" SG_ 736 FRObsRng "IFRObsRng";
BA_ "LongName" SG_ 736 FRObsRng "Front Right Obstacle Range";
BA_ "SysSignalName" SG_ 736 FRObsRng "FRObsRng";
BA_ "CompuMethodName" SG_ 736 LADSAFnInd_Tester "LADSAFnInd_Tester";
BA_ "ISignalName" SG_ 736 LADSAFnInd_Tester "ILADSAFnInd_Tester";
BA_ "LongName" SG_ 736 LADSAFnInd_Tester "Advanced Park Assist Active Function Indication";
BA_ "SysSignalName" SG_ 736 LADSAFnInd_Tester "LADSAFnInd_Tester";
BA_ "CompuMethodName" SG_ 736 FrtMidLObsRng "FrtMidLObsRng";
BA_ "ISignalName" SG_ 736 FrtMidLObsRng "IFrtMidLObsRng";
BA_ "LongName" SG_ 736 FrtMidLObsRng "Front Middle Left Obstacle Range";
BA_ "SysSignalName" SG_ 736 FrtMidLObsRng "FrtMidLObsRng";
BA_ "CompuMethodName" SG_ 736 FRSObsRng "FRSObsRng";
BA_ "ISignalName" SG_ 736 FRSObsRng "IFRSObsRng";
BA_ "LongName" SG_ 736 FRSObsRng "Front Right Side Obstacle Range";
BA_ "SysSignalName" SG_ 736 FRSObsRng "FRSObsRng";
BA_ "CompuMethodName" SG_ 736 FLSObsRng "FLSObsRng";
BA_ "ISignalName" SG_ 736 FLSObsRng "IFLSObsRng";
BA_ "LongName" SG_ 736 FLSObsRng "Front Left Side Obstacle Range";
BA_ "SysSignalName" SG_ 736 FLSObsRng "FLSObsRng";
BA_ "CompuMethodName" SG_ 736 RRSObsRng "RRSObsRng";
BA_ "ISignalName" SG_ 736 RRSObsRng "IRRSObsRng";
BA_ "LongName" SG_ 736 RRSObsRng "Rear Right Side Obstacle Range";
BA_ "SysSignalName" SG_ 736 RRSObsRng "RRSObsRng";
BA_ "CompuMethodName" SG_ 736 RLSObsRng "RLSObsRng";
BA_ "ISignalName" SG_ 736 RLSObsRng "IRLSObsRng";
BA_ "LongName" SG_ 736 RLSObsRng "Rear Left Side Obstacle Range";
BA_ "SysSignalName" SG_ 736 RLSObsRng "RLSObsRng";
BA_ "CompuMethodName" SG_ 893 ICBAD_100ms_Group25_CRC "ICBAD_100ms_Group25_CRC";
BA_ "ISignalName" SG_ 893 ICBAD_100ms_Group25_CRC "IICBAD_100ms_Group25_CRC";
BA_ "SysSignalName" SG_ 893 ICBAD_100ms_Group25_CRC "ICBAD_100ms_Group25_CRC";
BA_ "CompuMethodName" SG_ 893 ICBAD_100ms_Group25_RC "ICBAD_100ms_Group25_RC";
BA_ "ISignalName" SG_ 893 ICBAD_100ms_Group25_RC "IICBAD_100ms_Group25_RC";
BA_ "SysSignalName" SG_ 893 ICBAD_100ms_Group25_RC "ICBAD_100ms_Group25_RC";
BA_ "CompuMethodName" SG_ 893 ICBAD_100ms_Group25_Reserved15 "ICBAD_100ms_Group25_Reserved15";
BA_ "GenSigStartValue" SG_ 893 ICBAD_100ms_Group25_Reserved15 15;
BA_ "ISignalName" SG_ 893 ICBAD_100ms_Group25_Reserved15 "IICBAD_100ms_Group25_Reserved15";
BA_ "SysSignalName" SG_ 893 ICBAD_100ms_Group25_Reserved15 "ICBAD_100ms_Group25_Reserved15";
BA_ "CompuMethodName" SG_ 893 ICBAD_100ms_Group25_Reserved23 "ICBAD_100ms_Group25_Reserved23";
BA_ "GenSigStartValue" SG_ 893 ICBAD_100ms_Group25_Reserved23 255;
BA_ "ISignalName" SG_ 893 ICBAD_100ms_Group25_Reserved23 "IICBAD_100ms_Group25_Reserved23";
BA_ "SysSignalName" SG_ 893 ICBAD_100ms_Group25_Reserved23 "ICBAD_100ms_Group25_Reserved23";
BA_ "CompuMethodName" SG_ 893 ICBAD_100ms_Group25_Reserved31 "ICBAD_100ms_Group25_Reserved31";
BA_ "GenSigStartValue" SG_ 893 ICBAD_100ms_Group25_Reserved31 255;
BA_ "ISignalName" SG_ 893 ICBAD_100ms_Group25_Reserved31 "IICBAD_100ms_Group25_Reserved31";
BA_ "SysSignalName" SG_ 893 ICBAD_100ms_Group25_Reserved31 "ICBAD_100ms_Group25_Reserved31";
BA_ "CompuMethodName" SG_ 893 ICBAD_100ms_Group25_Reserved39 "ICBAD_100ms_Group25_Reserved39";
BA_ "GenSigStartValue" SG_ 893 ICBAD_100ms_Group25_Reserved39 255;
BA_ "ISignalName" SG_ 893 ICBAD_100ms_Group25_Reserved39 "IICBAD_100ms_Group25_Reserved39";
BA_ "SysSignalName" SG_ 893 ICBAD_100ms_Group25_Reserved39 "ICBAD_100ms_Group25_Reserved39";
BA_ "CompuMethodName" SG_ 893 ICBAD_100ms_Group25_Reserved47 "ICBAD_100ms_Group25_Reserved47";
BA_ "GenSigStartValue" SG_ 893 ICBAD_100ms_Group25_Reserved47 255;
BA_ "ISignalName" SG_ 893 ICBAD_100ms_Group25_Reserved47 "IICBAD_100ms_Group25_Reserved47";
BA_ "SysSignalName" SG_ 893 ICBAD_100ms_Group25_Reserved47 "ICBAD_100ms_Group25_Reserved47";
BA_ "CompuMethodName" SG_ 893 ICBAD_100ms_Group25_Reserved55 "ICBAD_100ms_Group25_Reserved55";
BA_ "GenSigStartValue" SG_ 893 ICBAD_100ms_Group25_Reserved55 255;
BA_ "ISignalName" SG_ 893 ICBAD_100ms_Group25_Reserved55 "IICBAD_100ms_Group25_Reserved55";
BA_ "SysSignalName" SG_ 893 ICBAD_100ms_Group25_Reserved55 "ICBAD_100ms_Group25_Reserved55";
BA_ "CompuMethodName" SG_ 893 ICBAD_100ms_Group25_Reserved63 "ICBAD_100ms_Group25_Reserved63";
BA_ "GenSigStartValue" SG_ 893 ICBAD_100ms_Group25_Reserved63 255;
BA_ "ISignalName" SG_ 893 ICBAD_100ms_Group25_Reserved63 "IICBAD_100ms_Group25_Reserved63";
BA_ "SysSignalName" SG_ 893 ICBAD_100ms_Group25_Reserved63 "ICBAD_100ms_Group25_Reserved63";
BA_ "CompuMethodName" SG_ 893 ICBAD_100ms_Group25_Reserved71 "ICBAD_100ms_Group25_Reserved71";
BA_ "GenSigStartValue" SG_ 893 ICBAD_100ms_Group25_Reserved71 255;
BA_ "ISignalName" SG_ 893 ICBAD_100ms_Group25_Reserved71 "IICBAD_100ms_Group25_Reserved71";
BA_ "SysSignalName" SG_ 893 ICBAD_100ms_Group25_Reserved71 "ICBAD_100ms_Group25_Reserved71";
BA_ "CompuMethodName" SG_ 893 ICBAD_100ms_Group25_Reserved79 "ICBAD_100ms_Group25_Reserved79";
BA_ "GenSigStartValue" SG_ 893 ICBAD_100ms_Group25_Reserved79 255;
BA_ "ISignalName" SG_ 893 ICBAD_100ms_Group25_Reserved79 "IICBAD_100ms_Group25_Reserved79";
BA_ "SysSignalName" SG_ 893 ICBAD_100ms_Group25_Reserved79 "ICBAD_100ms_Group25_Reserved79";
BA_ "CompuMethodName" SG_ 893 ICBAD_100ms_Group25_Reserved87 "ICBAD_100ms_Group25_Reserved87";
BA_ "GenSigStartValue" SG_ 893 ICBAD_100ms_Group25_Reserved87 255;
BA_ "ISignalName" SG_ 893 ICBAD_100ms_Group25_Reserved87 "IICBAD_100ms_Group25_Reserved87";
BA_ "SysSignalName" SG_ 893 ICBAD_100ms_Group25_Reserved87 "ICBAD_100ms_Group25_Reserved87";
BA_ "CompuMethodName" SG_ 893 ICBAD_100ms_Group25_Reserved95 "ICBAD_100ms_Group25_Reserved95";
BA_ "GenSigStartValue" SG_ 893 ICBAD_100ms_Group25_Reserved95 255;
BA_ "ISignalName" SG_ 893 ICBAD_100ms_Group25_Reserved95 "IICBAD_100ms_Group25_Reserved95";
BA_ "SysSignalName" SG_ 893 ICBAD_100ms_Group25_Reserved95 "ICBAD_100ms_Group25_Reserved95";
BA_ "CompuMethodName" SG_ 893 MemPkngSwResp "MemPkngSwResp";
BA_ "ISignalName" SG_ 893 MemPkngSwResp "IMemPkngSwResp";
BA_ "LongName" SG_ 893 MemPkngSwResp "Memory_Parking_Switch_Response";
BA_ "SysSignalName" SG_ 893 MemPkngSwResp "MemPkngSwResp";
BA_ "CompuMethodName" SG_ 893 ICBAD_100ms_Group25_Reserved103 "ICBAD_100ms_Group25_Reserved103";
BA_ "GenSigStartValue" SG_ 893 ICBAD_100ms_Group25_Reserved103 63;
BA_ "ISignalName" SG_ 893 ICBAD_100ms_Group25_Reserved103 "IICBAD_100ms_Group25_Reserved103";
BA_ "SysSignalName" SG_ 893 ICBAD_100ms_Group25_Reserved103 "ICBAD_100ms_Group25_Reserved103";
BA_ "CompuMethodName" SG_ 893 MemPkngSlntPtrlEnbSwResp "MemPkngSlntPtrlEnbSwResp";
BA_ "ISignalName" SG_ 893 MemPkngSlntPtrlEnbSwResp "IMemPkngSlntPtrlEnbSwResp";
BA_ "LongName" SG_ 893 MemPkngSlntPtrlEnbSwResp "Memory_Parking_Silent_Patrol_Enable_Switch_Response";
BA_ "SysSignalName" SG_ 893 MemPkngSlntPtrlEnbSwResp "MemPkngSlntPtrlEnbSwResp";
BA_ "CompuMethodName" SG_ 893 ICBAD_100ms_Group25_Reserved111 "ICBAD_100ms_Group25_Reserved111";
BA_ "GenSigStartValue" SG_ 893 ICBAD_100ms_Group25_Reserved111 63;
BA_ "ISignalName" SG_ 893 ICBAD_100ms_Group25_Reserved111 "IICBAD_100ms_Group25_Reserved111";
BA_ "SysSignalName" SG_ 893 ICBAD_100ms_Group25_Reserved111 "ICBAD_100ms_Group25_Reserved111";
BA_ "CompuMethodName" SG_ 893 ICBAD_100ms_Group25_Reserved119 "ICBAD_100ms_Group25_Reserved119";
BA_ "GenSigStartValue" SG_ 893 ICBAD_100ms_Group25_Reserved119 255;
BA_ "ISignalName" SG_ 893 ICBAD_100ms_Group25_Reserved119 "IICBAD_100ms_Group25_Reserved119";
BA_ "SysSignalName" SG_ 893 ICBAD_100ms_Group25_Reserved119 "ICBAD_100ms_Group25_Reserved119";
BA_ "CompuMethodName" SG_ 893 PEBSysFltSts "PEBSysFltSts";
BA_ "ISignalName" SG_ 893 PEBSysFltSts "IPEBSysFltSts";
BA_ "LongName" SG_ 893 PEBSysFltSts "Parking_Emergency_Brake_System_fault_status";
BA_ "SysSignalName" SG_ 893 PEBSysFltSts "PEBSysFltSts";
BA_ "CompuMethodName" SG_ 893 ICBAD_100ms_Group25_Reserved127 "ICBAD_100ms_Group25_Reserved127";
BA_ "GenSigStartValue" SG_ 893 ICBAD_100ms_Group25_Reserved127 63;
BA_ "ISignalName" SG_ 893 ICBAD_100ms_Group25_Reserved127 "IICBAD_100ms_Group25_Reserved127";
BA_ "SysSignalName" SG_ 893 ICBAD_100ms_Group25_Reserved127 "ICBAD_100ms_Group25_Reserved127";
BA_ "CompuMethodName" SG_ 893 ICBAD_100ms_Group25_Reserved135 "ICBAD_100ms_Group25_Reserved135";
BA_ "GenSigStartValue" SG_ 893 ICBAD_100ms_Group25_Reserved135 255;
BA_ "ISignalName" SG_ 893 ICBAD_100ms_Group25_Reserved135 "IICBAD_100ms_Group25_Reserved135";
BA_ "SysSignalName" SG_ 893 ICBAD_100ms_Group25_Reserved135 "ICBAD_100ms_Group25_Reserved135";
BA_ "CompuMethodName" SG_ 893 ICBAD_100ms_Group25_Reserved143 "ICBAD_100ms_Group25_Reserved143";
BA_ "GenSigStartValue" SG_ 893 ICBAD_100ms_Group25_Reserved143 255;
BA_ "ISignalName" SG_ 893 ICBAD_100ms_Group25_Reserved143 "IICBAD_100ms_Group25_Reserved143";
BA_ "SysSignalName" SG_ 893 ICBAD_100ms_Group25_Reserved143 "ICBAD_100ms_Group25_Reserved143";
BA_ "CompuMethodName" SG_ 893 ICBAD_100ms_Group25_Reserved151 "ICBAD_100ms_Group25_Reserved151";
BA_ "GenSigStartValue" SG_ 893 ICBAD_100ms_Group25_Reserved151 255;
BA_ "ISignalName" SG_ 893 ICBAD_100ms_Group25_Reserved151 "IICBAD_100ms_Group25_Reserved151";
BA_ "SysSignalName" SG_ 893 ICBAD_100ms_Group25_Reserved151 "ICBAD_100ms_Group25_Reserved151";
BA_ "CompuMethodName" SG_ 893 ICBAD_100ms_Group25_Reserved159 "ICBAD_100ms_Group25_Reserved159";
BA_ "GenSigStartValue" SG_ 893 ICBAD_100ms_Group25_Reserved159 255;
BA_ "ISignalName" SG_ 893 ICBAD_100ms_Group25_Reserved159 "IICBAD_100ms_Group25_Reserved159";
BA_ "SysSignalName" SG_ 893 ICBAD_100ms_Group25_Reserved159 "ICBAD_100ms_Group25_Reserved159";
BA_ "CompuMethodName" SG_ 893 ICBAD_100ms_Group25_Reserved167 "ICBAD_100ms_Group25_Reserved167";
BA_ "GenSigStartValue" SG_ 893 ICBAD_100ms_Group25_Reserved167 255;
BA_ "ISignalName" SG_ 893 ICBAD_100ms_Group25_Reserved167 "IICBAD_100ms_Group25_Reserved167";
BA_ "SysSignalName" SG_ 893 ICBAD_100ms_Group25_Reserved167 "ICBAD_100ms_Group25_Reserved167";
BA_ "CompuMethodName" SG_ 893 ICBAD_100ms_Group25_Reserved175 "ICBAD_100ms_Group25_Reserved175";
BA_ "GenSigStartValue" SG_ 893 ICBAD_100ms_Group25_Reserved175 255;
BA_ "ISignalName" SG_ 893 ICBAD_100ms_Group25_Reserved175 "IICBAD_100ms_Group25_Reserved175";
BA_ "SysSignalName" SG_ 893 ICBAD_100ms_Group25_Reserved175 "ICBAD_100ms_Group25_Reserved175";
BA_ "CompuMethodName" SG_ 893 ICBAD_100ms_Group25_Reserved183 "ICBAD_100ms_Group25_Reserved183";
BA_ "GenSigStartValue" SG_ 893 ICBAD_100ms_Group25_Reserved183 255;
BA_ "ISignalName" SG_ 893 ICBAD_100ms_Group25_Reserved183 "IICBAD_100ms_Group25_Reserved183";
BA_ "SysSignalName" SG_ 893 ICBAD_100ms_Group25_Reserved183 "ICBAD_100ms_Group25_Reserved183";
BA_ "CompuMethodName" SG_ 893 ICBAD_100ms_Group25_Reserved191 "ICBAD_100ms_Group25_Reserved191";
BA_ "GenSigStartValue" SG_ 893 ICBAD_100ms_Group25_Reserved191 255;
BA_ "ISignalName" SG_ 893 ICBAD_100ms_Group25_Reserved191 "IICBAD_100ms_Group25_Reserved191";
BA_ "SysSignalName" SG_ 893 ICBAD_100ms_Group25_Reserved191 "ICBAD_100ms_Group25_Reserved191";
BA_ "CompuMethodName" SG_ 314 D2DSysSts "D2DSysSts";
BA_ "ISignalName" SG_ 314 D2DSysSts "ID2DSysSts";
BA_ "LongName" SG_ 314 D2DSysSts "D2D System Status";
BA_ "SysSignalName" SG_ 314 D2DSysSts "D2DSysSts";
BA_ "CompuMethodName" SG_ 314 ACCObjDet "ACCObjDet";
BA_ "ISignalName" SG_ 314 ACCObjDet "IACCObjDet";
BA_ "LongName" SG_ 314 ACCObjDet "Adaptive Cruise Control Object Detected";
BA_ "SysSignalName" SG_ 314 ACCObjDet "ACCObjDet";
BA_ "CompuMethodName" SG_ 360 ICBAD_20ms_Group13_CRC "ICBAD_20ms_Group13_CRC";
BA_ "ISignalName" SG_ 360 ICBAD_20ms_Group13_CRC "IICBAD_20ms_Group13_CRC";
BA_ "LongName" SG_ 360 ICBAD_20ms_Group13_CRC "ICBAD_20ms_Group13_CRC";
BA_ "SysSignalName" SG_ 360 ICBAD_20ms_Group13_CRC "ICBAD_20ms_Group13_CRC";
BA_ "CompuMethodName" SG_ 360 ICBAD_20ms_Group13_RC "ICBAD_20ms_Group13_RC";
BA_ "ISignalName" SG_ 360 ICBAD_20ms_Group13_RC "IICBAD_20ms_Group13_RC";
BA_ "LongName" SG_ 360 ICBAD_20ms_Group13_RC "ICBAD_20ms_Group13_RC";
BA_ "SysSignalName" SG_ 360 ICBAD_20ms_Group13_RC "ICBAD_20ms_Group13_RC";
BA_ "CompuMethodName" SG_ 360 APAShifterPosReqd "APAShifterPosReqd";
BA_ "ISignalName" SG_ 360 APAShifterPosReqd "IAPAShifterPosReqd";
BA_ "LongName" SG_ 360 APAShifterPosReqd "Advanced Park Assist Shifter Position Requested";
BA_ "SysSignalName" SG_ 360 APAShifterPosReqd "APAShifterPosReqd";
BA_ "CompuMethodName" SG_ 360 APATrgtEPSStrgWhlAng "APATrgtEPSStrgWhlAng";
BA_ "GenSigStartValue" SG_ 360 APATrgtEPSStrgWhlAng 32768;
BA_ "ISignalName" SG_ 360 APATrgtEPSStrgWhlAng "IAPATrgtEPSStrgWhlAng";
BA_ "LongName" SG_ 360 APATrgtEPSStrgWhlAng "Advanced Park Assist Target Electric Power Steering Steering Wheel Angle";
BA_ "SysSignalName" SG_ 360 APATrgtEPSStrgWhlAng "APATrgtEPSStrgWhlAng";
BA_ "CompuMethodName" SG_ 360 ICBAD_20ms_Group13_Reserved1 "ICBAD_20ms_Group13_Reserved1";
BA_ "GenSigStartValue" SG_ 360 ICBAD_20ms_Group13_Reserved1 255;
BA_ "ISignalName" SG_ 360 ICBAD_20ms_Group13_Reserved1 "IICBAD_20ms_Group13_Reserved1";
BA_ "SysSignalName" SG_ 360 ICBAD_20ms_Group13_Reserved1 "ICBAD_20ms_Group13_Reserved1";
BA_ "CompuMethodName" SG_ 360 APASCUReqSts "APASCUReqSts";
BA_ "ISignalName" SG_ 360 APASCUReqSts "IAPASCUReqSts";
BA_ "LongName" SG_ 360 APASCUReqSts "Advanced Park Assist Shifter Control Unit Request Status";
BA_ "SysSignalName" SG_ 360 APASCUReqSts "APASCUReqSts";
BA_ "CompuMethodName" SG_ 360 APACmdEPSSts "APACmdEPSSts";
BA_ "ISignalName" SG_ 360 APACmdEPSSts "IAPACmdEPSSts";
BA_ "LongName" SG_ 360 APACmdEPSSts "Advanced Park Assist Command Electric Power Steering Status";
BA_ "SysSignalName" SG_ 360 APACmdEPSSts "APACmdEPSSts";
BA_ "CompuMethodName" SG_ 360 ICBAD_20ms_Group13_Reserved2 "ICBAD_20ms_Group13_Reserved2";
BA_ "GenSigStartValue" SG_ 360 ICBAD_20ms_Group13_Reserved2 15;
BA_ "ISignalName" SG_ 360 ICBAD_20ms_Group13_Reserved2 "IICBAD_20ms_Group13_Reserved2";
BA_ "SysSignalName" SG_ 360 ICBAD_20ms_Group13_Reserved2 "ICBAD_20ms_Group13_Reserved2";
BA_ "CompuMethodName" SG_ 360 ICBAD_20ms_Group13_Reserved4 "ICBAD_20ms_Group13_Reserved4";
BA_ "GenSigStartValue" SG_ 360 ICBAD_20ms_Group13_Reserved4 15;
BA_ "ISignalName" SG_ 360 ICBAD_20ms_Group13_Reserved4 "IICBAD_20ms_Group13_Reserved4";
BA_ "SysSignalName" SG_ 360 ICBAD_20ms_Group13_Reserved4 "ICBAD_20ms_Group13_Reserved4";
BA_ "CompuMethodName" SG_ 360 APAShifterPosReqdV "APAShifterPosReqdV";
BA_ "ISignalName" SG_ 360 APAShifterPosReqdV "IAPAShifterPosReqdV";
BA_ "LongName" SG_ 360 APAShifterPosReqdV "Advanced Park Assist Shifter Position Requested Validity";
BA_ "SysSignalName" SG_ 360 APAShifterPosReqdV "APAShifterPosReqdV";
BA_ "CompuMethodName" SG_ 360 APASCUReqStsV "APASCUReqStsV";
BA_ "ISignalName" SG_ 360 APASCUReqStsV "IAPASCUReqStsV";
BA_ "LongName" SG_ 360 APASCUReqStsV "Advanced Park Assist Shifter Control Unit Request Status Validity";
BA_ "SysSignalName" SG_ 360 APASCUReqStsV "APASCUReqStsV";
BA_ "CompuMethodName" SG_ 360 APAF "APAF";
BA_ "ISignalName" SG_ 360 APAF "IAPAF";
BA_ "LongName" SG_ 360 APAF "Advanced Park Assist Failed";
BA_ "SysSignalName" SG_ 360 APAF "APAF";
BA_ "CompuMethodName" SG_ 360 ICBAD_20ms_Group13_Reserved3 "ICBAD_20ms_Group13_Reserved3";
BA_ "GenSigStartValue" SG_ 360 ICBAD_20ms_Group13_Reserved3 1;
BA_ "ISignalName" SG_ 360 ICBAD_20ms_Group13_Reserved3 "IICBAD_20ms_Group13_Reserved3";
BA_ "SysSignalName" SG_ 360 ICBAD_20ms_Group13_Reserved3 "ICBAD_20ms_Group13_Reserved3";
BA_ "CompuMethodName" SG_ 360 ICBAD_20ms_Group13_Reserved5 "ICBAD_20ms_Group13_Reserved5";
BA_ "GenSigStartValue" SG_ 360 ICBAD_20ms_Group13_Reserved5 255;
BA_ "ISignalName" SG_ 360 ICBAD_20ms_Group13_Reserved5 "IICBAD_20ms_Group13_Reserved5";
BA_ "SysSignalName" SG_ 360 ICBAD_20ms_Group13_Reserved5 "ICBAD_20ms_Group13_Reserved5";
BA_ "CompuMethodName" SG_ 474 ICBAD_20ms_Group48_CRC "ICBAD_20ms_Group48_CRC";
BA_ "ISignalName" SG_ 474 ICBAD_20ms_Group48_CRC "IICBAD_20ms_Group48_CRC";
BA_ "LongName" SG_ 474 ICBAD_20ms_Group48_CRC "ICBAD_20ms_Group48_CRC";
BA_ "SysSignalName" SG_ 474 ICBAD_20ms_Group48_CRC "ICBAD_20ms_Group48_CRC";
BA_ "CompuMethodName" SG_ 474 ICBAD_20ms_Group48_RC "ICBAD_20ms_Group48_RC";
BA_ "ISignalName" SG_ 474 ICBAD_20ms_Group48_RC "IICBAD_20ms_Group48_RC";
BA_ "LongName" SG_ 474 ICBAD_20ms_Group48_RC "ICBAD_20ms_Group48_RC";
BA_ "SysSignalName" SG_ 474 ICBAD_20ms_Group48_RC "ICBAD_20ms_Group48_RC";
BA_ "CompuMethodName" SG_ 474 ICBAD_20ms_Group48_Reserved1 "ICBAD_20ms_Group48_Reserved1";
BA_ "GenSigStartValue" SG_ 474 ICBAD_20ms_Group48_Reserved1 1;
BA_ "ISignalName" SG_ 474 ICBAD_20ms_Group48_Reserved1 "IICBAD_20ms_Group48_Reserved1";
BA_ "SysSignalName" SG_ 474 ICBAD_20ms_Group48_Reserved1 "ICBAD_20ms_Group48_Reserved1";
BA_ "CompuMethodName" SG_ 474 LDWLKARVsulznReq "LDWLKARVsulznReq";
BA_ "ISignalName" SG_ 474 LDWLKARVsulznReq "ILDWLKARVsulznReq";
BA_ "LongName" SG_ 474 LDWLKARVsulznReq "Lane Departure Warning Lane Keeping Assist Right Visualization Request";
BA_ "SysSignalName" SG_ 474 LDWLKARVsulznReq "LDWLKARVsulznReq";
BA_ "CompuMethodName" SG_ 474 LDWLKAVbnLvlReq "LDWLKAVbnLvlReq";
BA_ "ISignalName" SG_ 474 LDWLKAVbnLvlReq "ILDWLKAVbnLvlReq";
BA_ "LongName" SG_ 474 LDWLKAVbnLvlReq "Lane Departure Warning Lane Keeping Assist Vibration Level Request";
BA_ "SysSignalName" SG_ 474 LDWLKAVbnLvlReq "LDWLKAVbnLvlReq";
BA_ "CompuMethodName" SG_ 474 LDWSysFltSts "LDWSysFltSts";
BA_ "ISignalName" SG_ 474 LDWSysFltSts "ILDWSysFltSts";
BA_ "LongName" SG_ 474 LDWSysFltSts "Lane Departure Warning System Fault Status";
BA_ "SysSignalName" SG_ 474 LDWSysFltSts "LDWSysFltSts";
BA_ "CompuMethodName" SG_ 474 LDWSysSts "LDWSysSts";
BA_ "ISignalName" SG_ 474 LDWSysSts "ILDWSysSts";
BA_ "LongName" SG_ 474 LDWSysSts "Lane Departure Warning System Status";
BA_ "SysSignalName" SG_ 474 LDWSysSts "LDWSysSts";
BA_ "CompuMethodName" SG_ 474 ICBAD_20ms_Group48_Reserved2 "ICBAD_20ms_Group48_Reserved2";
BA_ "GenSigStartValue" SG_ 474 ICBAD_20ms_Group48_Reserved2 255;
BA_ "ISignalName" SG_ 474 ICBAD_20ms_Group48_Reserved2 "IICBAD_20ms_Group48_Reserved2";
BA_ "SysSignalName" SG_ 474 ICBAD_20ms_Group48_Reserved2 "ICBAD_20ms_Group48_Reserved2";
BA_ "CompuMethodName" SG_ 474 ICBAD_20ms_Group48_Reserved3 "ICBAD_20ms_Group48_Reserved3";
BA_ "GenSigStartValue" SG_ 474 ICBAD_20ms_Group48_Reserved3 255;
BA_ "ISignalName" SG_ 474 ICBAD_20ms_Group48_Reserved3 "IICBAD_20ms_Group48_Reserved3";
BA_ "SysSignalName" SG_ 474 ICBAD_20ms_Group48_Reserved3 "ICBAD_20ms_Group48_Reserved3";
BA_ "CompuMethodName" SG_ 474 ICBAD_20ms_Group48_Reserved4 "ICBAD_20ms_Group48_Reserved4";
BA_ "GenSigStartValue" SG_ 474 ICBAD_20ms_Group48_Reserved4 31;
BA_ "ISignalName" SG_ 474 ICBAD_20ms_Group48_Reserved4 "IICBAD_20ms_Group48_Reserved4";
BA_ "SysSignalName" SG_ 474 ICBAD_20ms_Group48_Reserved4 "ICBAD_20ms_Group48_Reserved4";
BA_ "CompuMethodName" SG_ 474 LDWLKALVsulznReq "LDWLKALVsulznReq";
BA_ "ISignalName" SG_ 474 LDWLKALVsulznReq "ILDWLKALVsulznReq";
BA_ "LongName" SG_ 474 LDWLKALVsulznReq "Lane Departure Warning Lane Keeping Assist Left Visualization Request";
BA_ "SysSignalName" SG_ 474 LDWLKALVsulznReq "LDWLKALVsulznReq";
BA_ "CompuMethodName" SG_ 474 ICBAD_20ms_Group48_Reserved5 "ICBAD_20ms_Group48_Reserved5";
BA_ "GenSigStartValue" SG_ 474 ICBAD_20ms_Group48_Reserved5 255;
BA_ "ISignalName" SG_ 474 ICBAD_20ms_Group48_Reserved5 "IICBAD_20ms_Group48_Reserved5";
BA_ "SysSignalName" SG_ 474 ICBAD_20ms_Group48_Reserved5 "ICBAD_20ms_Group48_Reserved5";
BA_ "CompuMethodName" SG_ 474 ICBAD_20ms_Group48_Reserved6 "ICBAD_20ms_Group48_Reserved6";
BA_ "GenSigStartValue" SG_ 474 ICBAD_20ms_Group48_Reserved6 255;
BA_ "ISignalName" SG_ 474 ICBAD_20ms_Group48_Reserved6 "IICBAD_20ms_Group48_Reserved6";
BA_ "SysSignalName" SG_ 474 ICBAD_20ms_Group48_Reserved6 "ICBAD_20ms_Group48_Reserved6";
BA_ "CompuMethodName" SG_ 351 ICBAD_20ms_Group05_CRC "ICBAD_20ms_Group05_CRC";
BA_ "ISignalName" SG_ 351 ICBAD_20ms_Group05_CRC "IICBAD_20ms_Group05_CRC";
BA_ "LongName" SG_ 351 ICBAD_20ms_Group05_CRC "ICBAD_20ms_Group05_CRC";
BA_ "SysSignalName" SG_ 351 ICBAD_20ms_Group05_CRC "ICBAD_20ms_Group05_CRC";
BA_ "CompuMethodName" SG_ 351 ICBAD_20ms_Group05_RC "ICBAD_20ms_Group05_RC";
BA_ "ISignalName" SG_ 351 ICBAD_20ms_Group05_RC "IICBAD_20ms_Group05_RC";
BA_ "LongName" SG_ 351 ICBAD_20ms_Group05_RC "ICBAD_20ms_Group05_RC";
BA_ "SysSignalName" SG_ 351 ICBAD_20ms_Group05_RC "ICBAD_20ms_Group05_RC";
BA_ "CompuMethodName" SG_ 351 ICBAD_20ms_Group05_Reserved1 "ICBAD_20ms_Group05_Reserved1";
BA_ "GenSigStartValue" SG_ 351 ICBAD_20ms_Group05_Reserved1 1;
BA_ "ISignalName" SG_ 351 ICBAD_20ms_Group05_Reserved1 "IICBAD_20ms_Group05_Reserved1";
BA_ "SysSignalName" SG_ 351 ICBAD_20ms_Group05_Reserved1 "ICBAD_20ms_Group05_Reserved1";
BA_ "CompuMethodName" SG_ 351 APAVCUReqSts "APAVCUReqSts";
BA_ "ISignalName" SG_ 351 APAVCUReqSts "IAPAVCUReqSts";
BA_ "LongName" SG_ 351 APAVCUReqSts "Apa Vcu Request Status";
BA_ "SysSignalName" SG_ 351 APAVCUReqSts "APAVCUReqSts";
BA_ "CompuMethodName" SG_ 351 ICBAD_20ms_Group05_Reserved2 "ICBAD_20ms_Group05_Reserved2";
BA_ "GenSigStartValue" SG_ 351 ICBAD_20ms_Group05_Reserved2 255;
BA_ "ISignalName" SG_ 351 ICBAD_20ms_Group05_Reserved2 "IICBAD_20ms_Group05_Reserved2";
BA_ "SysSignalName" SG_ 351 ICBAD_20ms_Group05_Reserved2 "ICBAD_20ms_Group05_Reserved2";
BA_ "CompuMethodName" SG_ 351 APAToqReqVal "APAToqReqVal";
BA_ "ISignalName" SG_ 351 APAToqReqVal "IAPAToqReqVal";
BA_ "LongName" SG_ 351 APAToqReqVal "Advanced Park Assist Torque Request Value";
BA_ "SysSignalName" SG_ 351 APAToqReqVal "APAToqReqVal";
BA_ "CompuMethodName" SG_ 351 APACrpSpdReqVal_IPD "APACrpSpdReqVal_IPD";
BA_ "ISignalName" SG_ 351 APACrpSpdReqVal_IPD "IAPACrpSpdReqVal_IPD";
BA_ "LongName" SG_ 351 APACrpSpdReqVal_IPD "Advanced Park Assist Creep Speed Request Value";
BA_ "SysSignalName" SG_ 351 APACrpSpdReqVal_IPD "APACrpSpdReqVal_IPD";
BA_ "CompuMethodName" SG_ 351 ICBAD_20ms_Group05_Reserved3 "ICBAD_20ms_Group05_Reserved3";
BA_ "GenSigStartValue" SG_ 351 ICBAD_20ms_Group05_Reserved3 1;
BA_ "ISignalName" SG_ 351 ICBAD_20ms_Group05_Reserved3 "IICBAD_20ms_Group05_Reserved3";
BA_ "SysSignalName" SG_ 351 ICBAD_20ms_Group05_Reserved3 "ICBAD_20ms_Group05_Reserved3";
BA_ "CompuMethodName" SG_ 351 APARevrDrgReq "APARevrDrgReq";
BA_ "ISignalName" SG_ 351 APARevrDrgReq "IAPARevrDrgReq";
BA_ "LongName" SG_ 351 APARevrDrgReq "Advanced Park Assist Reverse Drag Request";
BA_ "SysSignalName" SG_ 351 APARevrDrgReq "APARevrDrgReq";
BA_ "CompuMethodName" SG_ 351 ICBAD_20ms_Group05_Reserved4 "ICBAD_20ms_Group05_Reserved4";
BA_ "GenSigStartValue" SG_ 351 ICBAD_20ms_Group05_Reserved4 255;
BA_ "ISignalName" SG_ 351 ICBAD_20ms_Group05_Reserved4 "IICBAD_20ms_Group05_Reserved4";
BA_ "SysSignalName" SG_ 351 ICBAD_20ms_Group05_Reserved4 "ICBAD_20ms_Group05_Reserved4";
BA_ "CompuMethodName" SG_ 351 ICBAD_20ms_Group05_Reserved5 "ICBAD_20ms_Group05_Reserved5";
BA_ "GenSigStartValue" SG_ 351 ICBAD_20ms_Group05_Reserved5 255;
BA_ "ISignalName" SG_ 351 ICBAD_20ms_Group05_Reserved5 "IICBAD_20ms_Group05_Reserved5";
BA_ "SysSignalName" SG_ 351 ICBAD_20ms_Group05_Reserved5 "ICBAD_20ms_Group05_Reserved5";
BA_ "CompuMethodName" SG_ 351 APATotWhlToqReqVal "APATotWhlToqReqVal";
BA_ "ISignalName" SG_ 351 APATotWhlToqReqVal "IAPATotWhlToqReqVal";
BA_ "LongName" SG_ 351 APATotWhlToqReqVal "Advanced_Park_Assist_Total_Wheel_Torque_Request_Value";
BA_ "SysSignalName" SG_ 351 APATotWhlToqReqVal "APATotWhlToqReqVal";
BA_ "CompuMethodName" SG_ 351 ICBAD_20ms_Group05_Reserved6 "ICBAD_20ms_Group05_Reserved6";
BA_ "GenSigStartValue" SG_ 351 ICBAD_20ms_Group05_Reserved6 255;
BA_ "ISignalName" SG_ 351 ICBAD_20ms_Group05_Reserved6 "IICBAD_20ms_Group05_Reserved6";
BA_ "SysSignalName" SG_ 351 ICBAD_20ms_Group05_Reserved6 "ICBAD_20ms_Group05_Reserved6";
BA_ "CompuMethodName" SG_ 351 ICBAD_20ms_Group05_Reserved7 "ICBAD_20ms_Group05_Reserved7";
BA_ "GenSigStartValue" SG_ 351 ICBAD_20ms_Group05_Reserved7 255;
BA_ "ISignalName" SG_ 351 ICBAD_20ms_Group05_Reserved7 "IICBAD_20ms_Group05_Reserved7";
BA_ "SysSignalName" SG_ 351 ICBAD_20ms_Group05_Reserved7 "ICBAD_20ms_Group05_Reserved7";
BA_ "CompuMethodName" SG_ 351 ICBAD_20ms_Group05_Reserved8 "ICBAD_20ms_Group05_Reserved8";
BA_ "GenSigStartValue" SG_ 351 ICBAD_20ms_Group05_Reserved8 255;
BA_ "ISignalName" SG_ 351 ICBAD_20ms_Group05_Reserved8 "IICBAD_20ms_Group05_Reserved8";
BA_ "SysSignalName" SG_ 351 ICBAD_20ms_Group05_Reserved8 "ICBAD_20ms_Group05_Reserved8";
BA_ "CompuMethodName" SG_ 351 ICBAD_20ms_Group05_Reserved9 "ICBAD_20ms_Group05_Reserved9";
BA_ "GenSigStartValue" SG_ 351 ICBAD_20ms_Group05_Reserved9 255;
BA_ "ISignalName" SG_ 351 ICBAD_20ms_Group05_Reserved9 "IICBAD_20ms_Group05_Reserved9";
BA_ "SysSignalName" SG_ 351 ICBAD_20ms_Group05_Reserved9 "ICBAD_20ms_Group05_Reserved9";
BA_ "CompuMethodName" SG_ 351 ICBAD_20ms_Group05_Reserved10 "ICBAD_20ms_Group05_Reserved10";
BA_ "GenSigStartValue" SG_ 351 ICBAD_20ms_Group05_Reserved10 255;
BA_ "ISignalName" SG_ 351 ICBAD_20ms_Group05_Reserved10 "IICBAD_20ms_Group05_Reserved10";
BA_ "SysSignalName" SG_ 351 ICBAD_20ms_Group05_Reserved10 "ICBAD_20ms_Group05_Reserved10";
BA_ "CompuMethodName" SG_ 351 ICBAD_20ms_Group05_Reserved11 "ICBAD_20ms_Group05_Reserved11";
BA_ "GenSigStartValue" SG_ 351 ICBAD_20ms_Group05_Reserved11 255;
BA_ "ISignalName" SG_ 351 ICBAD_20ms_Group05_Reserved11 "IICBAD_20ms_Group05_Reserved11";
BA_ "SysSignalName" SG_ 351 ICBAD_20ms_Group05_Reserved11 "ICBAD_20ms_Group05_Reserved11";
BA_ "CompuMethodName" SG_ 351 ICBAD_20ms_Group05_Reserved12 "ICBAD_20ms_Group05_Reserved12";
BA_ "GenSigStartValue" SG_ 351 ICBAD_20ms_Group05_Reserved12 255;
BA_ "ISignalName" SG_ 351 ICBAD_20ms_Group05_Reserved12 "IICBAD_20ms_Group05_Reserved12";
BA_ "SysSignalName" SG_ 351 ICBAD_20ms_Group05_Reserved12 "ICBAD_20ms_Group05_Reserved12";
BA_ "CompuMethodName" SG_ 351 ICBAD_20ms_Group05_Reserved13 "ICBAD_20ms_Group05_Reserved13";
BA_ "GenSigStartValue" SG_ 351 ICBAD_20ms_Group05_Reserved13 255;
BA_ "ISignalName" SG_ 351 ICBAD_20ms_Group05_Reserved13 "IICBAD_20ms_Group05_Reserved13";
BA_ "SysSignalName" SG_ 351 ICBAD_20ms_Group05_Reserved13 "ICBAD_20ms_Group05_Reserved13";
BA_ "CompuMethodName" SG_ 351 ICBAD_20ms_Group05_Reserved14 "ICBAD_20ms_Group05_Reserved14";
BA_ "GenSigStartValue" SG_ 351 ICBAD_20ms_Group05_Reserved14 255;
BA_ "ISignalName" SG_ 351 ICBAD_20ms_Group05_Reserved14 "IICBAD_20ms_Group05_Reserved14";
BA_ "SysSignalName" SG_ 351 ICBAD_20ms_Group05_Reserved14 "ICBAD_20ms_Group05_Reserved14";
BA_ "CompuMethodName" SG_ 351 ICBAD_20ms_Group05_Reserved15 "ICBAD_20ms_Group05_Reserved15";
BA_ "GenSigStartValue" SG_ 351 ICBAD_20ms_Group05_Reserved15 255;
BA_ "ISignalName" SG_ 351 ICBAD_20ms_Group05_Reserved15 "IICBAD_20ms_Group05_Reserved15";
BA_ "SysSignalName" SG_ 351 ICBAD_20ms_Group05_Reserved15 "ICBAD_20ms_Group05_Reserved15";
BA_ "CompuMethodName" SG_ 424 ICBAD_20ms_Group12_CRC "ICBAD_20ms_Group12_CRC";
BA_ "ISignalName" SG_ 424 ICBAD_20ms_Group12_CRC "IICBAD_20ms_Group12_CRC";
BA_ "LongName" SG_ 424 ICBAD_20ms_Group12_CRC "ICBAD_20ms_Group12_CRC";
BA_ "SysSignalName" SG_ 424 ICBAD_20ms_Group12_CRC "ICBAD_20ms_Group12_CRC";
BA_ "CompuMethodName" SG_ 424 ICBAD_20ms_Group12_RC "ICBAD_20ms_Group12_RC";
BA_ "ISignalName" SG_ 424 ICBAD_20ms_Group12_RC "IICBAD_20ms_Group12_RC";
BA_ "LongName" SG_ 424 ICBAD_20ms_Group12_RC "ICBAD_20ms_Group12_RC";
BA_ "SysSignalName" SG_ 424 ICBAD_20ms_Group12_RC "ICBAD_20ms_Group12_RC";
BA_ "CompuMethodName" SG_ 424 AutodDrvngSysStsV "AutodDrvngSysStsV";
BA_ "ISignalName" SG_ 424 AutodDrvngSysStsV "IAutodDrvngSysStsV";
BA_ "LongName" SG_ 424 AutodDrvngSysStsV "Automated Driving System Status Validity";
BA_ "SysSignalName" SG_ 424 AutodDrvngSysStsV "AutodDrvngSysStsV";
BA_ "CompuMethodName" SG_ 424 ICBAD_20ms_Group12_Reserved1 "ICBAD_20ms_Group12_Reserved1";
BA_ "GenSigStartValue" SG_ 424 ICBAD_20ms_Group12_Reserved1 7;
BA_ "ISignalName" SG_ 424 ICBAD_20ms_Group12_Reserved1 "IICBAD_20ms_Group12_Reserved1";
BA_ "SysSignalName" SG_ 424 ICBAD_20ms_Group12_Reserved1 "ICBAD_20ms_Group12_Reserved1";
BA_ "CompuMethodName" SG_ 424 ICBAD_20ms_Group12_Reserved2 "ICBAD_20ms_Group12_Reserved2";
BA_ "GenSigStartValue" SG_ 424 ICBAD_20ms_Group12_Reserved2 31;
BA_ "ISignalName" SG_ 424 ICBAD_20ms_Group12_Reserved2 "IICBAD_20ms_Group12_Reserved2";
BA_ "SysSignalName" SG_ 424 ICBAD_20ms_Group12_Reserved2 "ICBAD_20ms_Group12_Reserved2";
BA_ "CompuMethodName" SG_ 424 APASts "APASts";
BA_ "ISignalName" SG_ 424 APASts "IAPASts";
BA_ "LongName" SG_ 424 APASts "Advanced_Park_Assist_Status";
BA_ "SysSignalName" SG_ 424 APASts "APASts";
BA_ "CompuMethodName" SG_ 424 AutodDrvngSysSts "AutodDrvngSysSts";
BA_ "ISignalName" SG_ 424 AutodDrvngSysSts "IAutodDrvngSysSts";
BA_ "LongName" SG_ 424 AutodDrvngSysSts "Automated_Driving_System_Status";
BA_ "SysSignalName" SG_ 424 AutodDrvngSysSts "AutodDrvngSysSts";
BA_ "CompuMethodName" SG_ 424 ICBAD_20ms_Group12_Reserved3 "ICBAD_20ms_Group12_Reserved3";
BA_ "GenSigStartValue" SG_ 424 ICBAD_20ms_Group12_Reserved3 255;
BA_ "ISignalName" SG_ 424 ICBAD_20ms_Group12_Reserved3 "IICBAD_20ms_Group12_Reserved3";
BA_ "SysSignalName" SG_ 424 ICBAD_20ms_Group12_Reserved3 "ICBAD_20ms_Group12_Reserved3";
BA_ "CompuMethodName" SG_ 424 ICBAD_20ms_Group12_Reserved4 "ICBAD_20ms_Group12_Reserved4";
BA_ "GenSigStartValue" SG_ 424 ICBAD_20ms_Group12_Reserved4 255;
BA_ "ISignalName" SG_ 424 ICBAD_20ms_Group12_Reserved4 "IICBAD_20ms_Group12_Reserved4";
BA_ "SysSignalName" SG_ 424 ICBAD_20ms_Group12_Reserved4 "ICBAD_20ms_Group12_Reserved4";
BA_ "CompuMethodName" SG_ 424 ICBAD_20ms_Group12_Reserved5 "ICBAD_20ms_Group12_Reserved5";
BA_ "GenSigStartValue" SG_ 424 ICBAD_20ms_Group12_Reserved5 255;
BA_ "ISignalName" SG_ 424 ICBAD_20ms_Group12_Reserved5 "IICBAD_20ms_Group12_Reserved5";
BA_ "SysSignalName" SG_ 424 ICBAD_20ms_Group12_Reserved5 "ICBAD_20ms_Group12_Reserved5";
BA_ "CompuMethodName" SG_ 424 ICBAD_20ms_Group12_Reserved6 "ICBAD_20ms_Group12_Reserved6";
BA_ "GenSigStartValue" SG_ 424 ICBAD_20ms_Group12_Reserved6 255;
BA_ "ISignalName" SG_ 424 ICBAD_20ms_Group12_Reserved6 "IICBAD_20ms_Group12_Reserved6";
BA_ "SysSignalName" SG_ 424 ICBAD_20ms_Group12_Reserved6 "ICBAD_20ms_Group12_Reserved6";
BA_ "CompuMethodName" SG_ 50 IPDTripCntResetResp "IPDTripCntResetResp";
BA_ "ISignalName" SG_ 50 IPDTripCntResetResp "IIPDTripCntResetResp";
BA_ "LongName" SG_ 50 IPDTripCntResetResp "IPD Trip Counter Reset Response";
BA_ "SysSignalName" SG_ 50 IPDTripCntResetResp "IPDTripCntResetResp";
BA_ "CompuMethodName" SG_ 178 IPDDataId "IPDDataId";
BA_ "ISignalName" SG_ 178 IPDDataId "IIPDDataId";
BA_ "LongName" SG_ 178 IPDDataId "IPDDataId";
BA_ "SysSignalName" SG_ 178 IPDDataId "IPDDataId";
BA_ "CompuMethodName" SG_ 178 IPDAlgFlag "IPDAlgFlag";
BA_ "ISignalName" SG_ 178 IPDAlgFlag "IIPDAlgFlag";
BA_ "LongName" SG_ 178 IPDAlgFlag "IPDAlgorismFlag";
BA_ "SysSignalName" SG_ 178 IPDAlgFlag "IPDAlgFlag";
BA_ "CompuMethodName" SG_ 178 IPDFailedReason "IPDFailedReason";
BA_ "ISignalName" SG_ 178 IPDFailedReason "IIPDFailedReason";
BA_ "LongName" SG_ 178 IPDFailedReason "IPDFailedReason";
BA_ "SysSignalName" SG_ 178 IPDFailedReason "IPDFailedReason";
BA_ "CompuMethodName" SG_ 178 IPDErrorCount "IPDErrorCount";
BA_ "ISignalName" SG_ 178 IPDErrorCount "IIPDErrorCount";
BA_ "LongName" SG_ 178 IPDErrorCount "IPDErrorCount";
BA_ "SysSignalName" SG_ 178 IPDErrorCount "IPDErrorCount";
BA_ "CompuMethodName" SG_ 178 IPDTripNvmTag "IPDTripNvmTag";
BA_ "ISignalName" SG_ 178 IPDTripNvmTag "IIPDTripNvmTag";
BA_ "LongName" SG_ 178 IPDTripNvmTag "IPDTripNvmTag";
BA_ "SysSignalName" SG_ 178 IPDTripNvmTag "IPDTripNvmTag";
BA_ "CompuMethodName" SG_ 178 IPDResetCnt "IPDResetCnt";
BA_ "ISignalName" SG_ 178 IPDResetCnt "IIPDResetCnt";
BA_ "LongName" SG_ 178 IPDResetCnt "IPDResetCounter";
BA_ "SysSignalName" SG_ 178 IPDResetCnt "IPDResetCnt";
BA_ "CompuMethodName" SG_ 178 IPDKeyStatus "IPDKeyStatus";
BA_ "ISignalName" SG_ 178 IPDKeyStatus "IIPDKeyStatus";
BA_ "LongName" SG_ 178 IPDKeyStatus "IPDKeyStatus";
BA_ "SysSignalName" SG_ 178 IPDKeyStatus "IPDKeyStatus";
BA_ "CompuMethodName" SG_ 178 IPDTripCnt "IPDTripCnt";
BA_ "ISignalName" SG_ 178 IPDTripCnt "IIPDTripCnt";
BA_ "LongName" SG_ 178 IPDTripCnt "IPDTripCounter";
BA_ "SysSignalName" SG_ 178 IPDTripCnt "IPDTripCnt";
BA_ "CompuMethodName" SG_ 81 ICBAD_ZONE_20ms_Group13_CRC "ICBAD_ZONE_20ms_Group13_CRC";
BA_ "ISignalName" SG_ 81 ICBAD_ZONE_20ms_Group13_CRC "IICBAD_ZONE_20ms_Group13_CRC";
BA_ "LongName" SG_ 81 ICBAD_ZONE_20ms_Group13_CRC "ICBAD_ZONE_20ms_Group13_CRC";
BA_ "SysSignalName" SG_ 81 ICBAD_ZONE_20ms_Group13_CRC "ICBAD_ZONE_20ms_Group13_CRC";
BA_ "CompuMethodName" SG_ 81 ICBAD_ZONE_20ms_Group13_RC "ICBAD_ZONE_20ms_Group13_RC";
BA_ "ISignalName" SG_ 81 ICBAD_ZONE_20ms_Group13_RC "IICBAD_ZONE_20ms_Group13_RC";
BA_ "LongName" SG_ 81 ICBAD_ZONE_20ms_Group13_RC "ICBAD_ZONE_20ms_Group13_RC";
BA_ "SysSignalName" SG_ 81 ICBAD_ZONE_20ms_Group13_RC "ICBAD_ZONE_20ms_Group13_RC";
BA_ "CompuMethodName" SG_ 81 ICBAD_ZONE_20ms_Group13_Reserved0 "ICBAD_ZONE_20ms_Group13_Reserved1";
BA_ "GenSigStartValue" SG_ 81 ICBAD_ZONE_20ms_Group13_Reserved0 1;
BA_ "ISignalName" SG_ 81 ICBAD_ZONE_20ms_Group13_Reserved0 "IICBAD_ZONE_20ms_Group13_Reserved1";
BA_ "SysSignalName" SG_ 81 ICBAD_ZONE_20ms_Group13_Reserved0 "ICBAD_ZONE_20ms_Group13_Reserved1";
BA_ "SystemSignalLongSymbol" SG_ 81 ICBAD_ZONE_20ms_Group13_Reserved0 "ICBAD_ZONE_20ms_Group13_Reserved1";
BA_ "CompuMethodName" SG_ 81 TJAICASysFltSts "TJAICASysFltSts";
BA_ "ISignalName" SG_ 81 TJAICASysFltSts "ITJAICASysFltSts";
BA_ "LongName" SG_ 81 TJAICASysFltSts "Traffic Jam Assist Integrated Cruise Assist Fault Status";
BA_ "SysSignalName" SG_ 81 TJAICASysFltSts "TJAICASysFltSts";
BA_ "CompuMethodName" SG_ 81 ACCToqReqSts "ACCToqReqSts";
BA_ "ISignalName" SG_ 81 ACCToqReqSts "IACCToqReqSts";
BA_ "SysSignalName" SG_ 81 ACCToqReqSts "ACCToqReqSts";
BA_ "CompuMethodName" SG_ 81 LKASysFltSts "LKASysFltSts";
BA_ "ISignalName" SG_ 81 LKASysFltSts "ILKASysFltSts";
BA_ "LongName" SG_ 81 LKASysFltSts "Lane Keeping Assist System Fault Status";
BA_ "SysSignalName" SG_ 81 LKASysFltSts "LKASysFltSts";
BA_ "CompuMethodName" SG_ 81 ICBAD_ZONE_20ms_Group13_Reserved1 "ICBAD_ZONE_20ms_Group13_Reserved2";
BA_ "GenSigStartValue" SG_ 81 ICBAD_ZONE_20ms_Group13_Reserved1 7;
BA_ "ISignalName" SG_ 81 ICBAD_ZONE_20ms_Group13_Reserved1 "IICBAD_ZONE_20ms_Group13_Reserved2";
BA_ "SysSignalName" SG_ 81 ICBAD_ZONE_20ms_Group13_Reserved1 "ICBAD_ZONE_20ms_Group13_Reserved2";
BA_ "SystemSignalLongSymbol" SG_ 81 ICBAD_ZONE_20ms_Group13_Reserved1 "ICBAD_ZONE_20ms_Group13_Reserved2";
BA_ "CompuMethodName" SG_ 81 ICBAD_ZONE_20ms_Group13_Reserved2 "ICBAD_ZONE_20ms_Group13_Reserved3";
BA_ "GenSigStartValue" SG_ 81 ICBAD_ZONE_20ms_Group13_Reserved2 3;
BA_ "ISignalName" SG_ 81 ICBAD_ZONE_20ms_Group13_Reserved2 "IICBAD_ZONE_20ms_Group13_Reserved3";
BA_ "SysSignalName" SG_ 81 ICBAD_ZONE_20ms_Group13_Reserved2 "ICBAD_ZONE_20ms_Group13_Reserved3";
BA_ "SystemSignalLongSymbol" SG_ 81 ICBAD_ZONE_20ms_Group13_Reserved2 "ICBAD_ZONE_20ms_Group13_Reserved3";
BA_ "CompuMethodName" SG_ 81 TJAICASysSts "TJAICASysSts";
BA_ "ISignalName" SG_ 81 TJAICASysSts "ITJAICASysSts";
BA_ "LongName" SG_ 81 TJAICASysSts "Traffic Jam Assist Integrated Cruise Assist System Status";
BA_ "SysSignalName" SG_ 81 TJAICASysSts "TJAICASysSts";
BA_ "CompuMethodName" SG_ 81 LKASysSts "LKASysSts";
BA_ "ISignalName" SG_ 81 LKASysSts "ILKASysSts";
BA_ "LongName" SG_ 81 LKASysSts "Lane Keeping Assist System Status";
BA_ "SysSignalName" SG_ 81 LKASysSts "LKASysSts";
BA_ "CompuMethodName" SG_ 81 ACCToqReqVal "ACCToqReqVal";
BA_ "GenSigStartValue" SG_ 81 ACCToqReqVal 1696;
BA_ "ISignalName" SG_ 81 ACCToqReqVal "IACCToqReqVal";
BA_ "SysSignalName" SG_ 81 ACCToqReqVal "ACCToqReqVal";
BA_ "CompuMethodName" SG_ 81 ICBAD_ZONE_20ms_Group13_Reserved3 "ICBAD_ZONE_20ms_Group13_Reserved4";
BA_ "GenSigStartValue" SG_ 81 ICBAD_ZONE_20ms_Group13_Reserved3 15;
BA_ "ISignalName" SG_ 81 ICBAD_ZONE_20ms_Group13_Reserved3 "IICBAD_ZONE_20ms_Group13_Reserved4";
BA_ "SysSignalName" SG_ 81 ICBAD_ZONE_20ms_Group13_Reserved3 "ICBAD_ZONE_20ms_Group13_Reserved4";
BA_ "SystemSignalLongSymbol" SG_ 81 ICBAD_ZONE_20ms_Group13_Reserved3 "ICBAD_ZONE_20ms_Group13_Reserved4";
BA_ "CompuMethodName" SG_ 81 ICBAD_ZONE_20ms_Group13_Reserved4 "ICBAD_ZONE_20ms_Group13_Reserved5";
BA_ "GenSigStartValue" SG_ 81 ICBAD_ZONE_20ms_Group13_Reserved4 255;
BA_ "ISignalName" SG_ 81 ICBAD_ZONE_20ms_Group13_Reserved4 "IICBAD_ZONE_20ms_Group13_Reserved5";
BA_ "SysSignalName" SG_ 81 ICBAD_ZONE_20ms_Group13_Reserved4 "ICBAD_ZONE_20ms_Group13_Reserved5";
BA_ "SystemSignalLongSymbol" SG_ 81 ICBAD_ZONE_20ms_Group13_Reserved4 "ICBAD_ZONE_20ms_Group13_Reserved5";
BA_ "CompuMethodName" SG_ 81 ICBAD_ZONE_20ms_Group13_Reserved5 "ICBAD_ZONE_20ms_Group13_Reserved6";
BA_ "GenSigStartValue" SG_ 81 ICBAD_ZONE_20ms_Group13_Reserved5 255;
BA_ "ISignalName" SG_ 81 ICBAD_ZONE_20ms_Group13_Reserved5 "IICBAD_ZONE_20ms_Group13_Reserved6";
BA_ "SysSignalName" SG_ 81 ICBAD_ZONE_20ms_Group13_Reserved5 "ICBAD_ZONE_20ms_Group13_Reserved6";
BA_ "SystemSignalLongSymbol" SG_ 81 ICBAD_ZONE_20ms_Group13_Reserved5 "ICBAD_ZONE_20ms_Group13_Reserved6";
BA_ "CompuMethodName" SG_ 1282 SpdLmtPathRngNav "SpdLmtPathRngNav";
BA_ "GenSigStartValue" SG_ 1282 SpdLmtPathRngNav 2047;
BA_ "ISignalName" SG_ 1282 SpdLmtPathRngNav "ISpdLmtPathRngNav";
BA_ "LongName" SG_ 1282 SpdLmtPathRngNav "Speed_Limit_Path_Range_Navigation";
BA_ "SysSignalName" SG_ 1282 SpdLmtPathRngNav "SpdLmtPathRngNav";
BA_ "CompuMethodName" SG_ 1282 MnvrngPntDistNav "MnvrngPntDistNav";
BA_ "GenSigStartValue" SG_ 1282 MnvrngPntDistNav 1023;
BA_ "ISignalName" SG_ 1282 MnvrngPntDistNav "IMnvrngPntDistNav";
BA_ "LongName" SG_ 1282 MnvrngPntDistNav "Maneuvering_Point_Distance_Navigation";
BA_ "SysSignalName" SG_ 1282 MnvrngPntDistNav "MnvrngPntDistNav";
BA_ "CompuMethodName" SG_ 1282 DistToTrfcJamNav "DistToTrfcJamNav";
BA_ "GenSigStartValue" SG_ 1282 DistToTrfcJamNav 255;
BA_ "ISignalName" SG_ 1282 DistToTrfcJamNav "IDistToTrfcJamNav";
BA_ "LongName" SG_ 1282 DistToTrfcJamNav "Distance_To_Traffic_Jam_Navigation";
BA_ "SysSignalName" SG_ 1282 DistToTrfcJamNav "DistToTrfcJamNav";
BA_ "CompuMethodName" SG_ 1282 MnvrngPntTypNav "MnvrngPntTypNav";
BA_ "ISignalName" SG_ 1282 MnvrngPntTypNav "IMnvrngPntTypNav";
BA_ "LongName" SG_ 1282 MnvrngPntTypNav "Maneuvering_Point_Type_Navigation";
BA_ "SysSignalName" SG_ 1282 MnvrngPntTypNav "MnvrngPntTypNav";
BA_ "CompuMethodName" SG_ 1282 TrfcJamRngNav "TrfcJamRngNav";
BA_ "GenSigStartValue" SG_ 1282 TrfcJamRngNav 255;
BA_ "ISignalName" SG_ 1282 TrfcJamRngNav "ITrfcJamRngNav";
BA_ "LongName" SG_ 1282 TrfcJamRngNav "Traffic_Jam_Range_Navigation";
BA_ "SysSignalName" SG_ 1282 TrfcJamRngNav "TrfcJamRngNav";
BA_ "CompuMethodName" SG_ 1282 NavSts "NavSts";
BA_ "ISignalName" SG_ 1282 NavSts "INavSts";
BA_ "LongName" SG_ 1282 NavSts "Navigation_Status";
BA_ "SysSignalName" SG_ 1282 NavSts "NavSts";
BA_ "CompuMethodName" SG_ 1282 SpdLmtNav "SpdLmtNav";
BA_ "GenSigStartValue" SG_ 1282 SpdLmtNav 31;
BA_ "ISignalName" SG_ 1282 SpdLmtNav "ISpdLmtNav";
BA_ "LongName" SG_ 1282 SpdLmtNav "Speed_Limit_Navigation";
BA_ "SysSignalName" SG_ 1282 SpdLmtNav "SpdLmtNav";
BA_ "CompuMethodName" SG_ 66 ICBVC_100ms_Group01_CRC "ICBVC_100ms_Group01_CRC";
BA_ "ISignalName" SG_ 66 ICBVC_100ms_Group01_CRC "IICBVC_100ms_Group01_CRC";
BA_ "SysSignalName" SG_ 66 ICBVC_100ms_Group01_CRC "ICBVC_100ms_Group01_CRC";
BA_ "CompuMethodName" SG_ 66 ICBVC_100ms_Group01_RC "ICBVC_100ms_Group01_RC";
BA_ "ISignalName" SG_ 66 ICBVC_100ms_Group01_RC "IICBVC_100ms_Group01_RC";
BA_ "SysSignalName" SG_ 66 ICBVC_100ms_Group01_RC "ICBVC_100ms_Group01_RC";
BA_ "CompuMethodName" SG_ 66 ICBVC_100ms_Group01_Reserved14 "ICBVC_100ms_Group01_Reserved14";
BA_ "GenSigStartValue" SG_ 66 ICBVC_100ms_Group01_Reserved14 7;
BA_ "ISignalName" SG_ 66 ICBVC_100ms_Group01_Reserved14 "IICBVC_100ms_Group01_Reserved14";
BA_ "SysSignalName" SG_ 66 ICBVC_100ms_Group01_Reserved14 "ICBVC_100ms_Group01_Reserved14";
BA_ "CompuMethodName" SG_ 66 DspMeasmtSys "DspMeasmtSys";
BA_ "ISignalName" SG_ 66 DspMeasmtSys "IDspMeasmtSys";
BA_ "LongName" SG_ 66 DspMeasmtSys "Display Measurement System";
BA_ "SysSignalName" SG_ 66 DspMeasmtSys "DspMeasmtSys";
BA_ "CompuMethodName" SG_ 66 ICBVC_100ms_Group01_Reserved21 "ICBVC_100ms_Group01_Reserved21";
BA_ "GenSigStartValue" SG_ 66 ICBVC_100ms_Group01_Reserved21 63;
BA_ "ISignalName" SG_ 66 ICBVC_100ms_Group01_Reserved21 "IICBVC_100ms_Group01_Reserved21";
BA_ "SysSignalName" SG_ 66 ICBVC_100ms_Group01_Reserved21 "ICBVC_100ms_Group01_Reserved21";
BA_ "CompuMethodName" SG_ 66 PDCSwReq "PDCSwReq";
BA_ "ISignalName" SG_ 66 PDCSwReq "IPDCSwReq";
BA_ "LongName" SG_ 66 PDCSwReq "Park Distance Control Switch Request";
BA_ "SysSignalName" SG_ 66 PDCSwReq "PDCSwReq";
BA_ "CompuMethodName" SG_ 66 PwrMdExtrCtrlAvlbl "PwrMdExtrCtrlAvlbl";
BA_ "ISignalName" SG_ 66 PwrMdExtrCtrlAvlbl "IPwrMdExtrCtrlAvlbl";
BA_ "LongName" SG_ 66 PwrMdExtrCtrlAvlbl "Power_Mode_Exterior_Control_Available";
BA_ "SysSignalName" SG_ 66 PwrMdExtrCtrlAvlbl "PwrMdExtrCtrlAvlbl";
BA_ "CompuMethodName" SG_ 66 MdOfPwrMd "MdOfPwrMd";
BA_ "ISignalName" SG_ 66 MdOfPwrMd "IMdOfPwrMd";
BA_ "LongName" SG_ 66 MdOfPwrMd "Mode_Of_Power_Mode";
BA_ "SysSignalName" SG_ 66 MdOfPwrMd "MdOfPwrMd";
BA_ "CompuMethodName" SG_ 66 ICBVC_100ms_Group01_Reserved31 "ICBVC_100ms_Group01_Reserved31";
BA_ "GenSigStartValue" SG_ 66 ICBVC_100ms_Group01_Reserved31 63;
BA_ "ISignalName" SG_ 66 ICBVC_100ms_Group01_Reserved31 "IICBVC_100ms_Group01_Reserved31";
BA_ "SysSignalName" SG_ 66 ICBVC_100ms_Group01_Reserved31 "ICBVC_100ms_Group01_Reserved31";
BA_ "CompuMethodName" SG_ 66 ClstrDspdVehSpd "ClstrDspdVehSpd";
BA_ "ISignalName" SG_ 66 ClstrDspdVehSpd "IClstrDspdVehSpd";
BA_ "LongName" SG_ 66 ClstrDspdVehSpd "Cluster Displayed Vehicle Speed";
BA_ "SysSignalName" SG_ 66 ClstrDspdVehSpd "ClstrDspdVehSpd";
BA_ "CompuMethodName" SG_ 66 ICBVC_100ms_Group01_Reserved47 "ICBVC_100ms_Group01_Reserved47";
BA_ "GenSigStartValue" SG_ 66 ICBVC_100ms_Group01_Reserved47 255;
BA_ "ISignalName" SG_ 66 ICBVC_100ms_Group01_Reserved47 "IICBVC_100ms_Group01_Reserved47";
BA_ "SysSignalName" SG_ 66 ICBVC_100ms_Group01_Reserved47 "ICBVC_100ms_Group01_Reserved47";
BA_ "CompuMethodName" SG_ 66 ICBVC_100ms_Group01_Reserved55 "ICBVC_100ms_Group01_Reserved55";
BA_ "GenSigStartValue" SG_ 66 ICBVC_100ms_Group01_Reserved55 255;
BA_ "ISignalName" SG_ 66 ICBVC_100ms_Group01_Reserved55 "IICBVC_100ms_Group01_Reserved55";
BA_ "SysSignalName" SG_ 66 ICBVC_100ms_Group01_Reserved55 "ICBVC_100ms_Group01_Reserved55";
BA_ "CompuMethodName" SG_ 66 ICBVC_100ms_Group01_Reserved63 "ICBVC_100ms_Group01_Reserved63";
BA_ "GenSigStartValue" SG_ 66 ICBVC_100ms_Group01_Reserved63 255;
BA_ "ISignalName" SG_ 66 ICBVC_100ms_Group01_Reserved63 "IICBVC_100ms_Group01_Reserved63";
BA_ "SysSignalName" SG_ 66 ICBVC_100ms_Group01_Reserved63 "ICBVC_100ms_Group01_Reserved63";
BA_ "CompuMethodName" SG_ 66 ICBVC_100ms_Group01_Reserved71 "ICBVC_100ms_Group01_Reserved71";
BA_ "GenSigStartValue" SG_ 66 ICBVC_100ms_Group01_Reserved71 255;
BA_ "ISignalName" SG_ 66 ICBVC_100ms_Group01_Reserved71 "IICBVC_100ms_Group01_Reserved71";
BA_ "SysSignalName" SG_ 66 ICBVC_100ms_Group01_Reserved71 "ICBVC_100ms_Group01_Reserved71";
BA_ "CompuMethodName" SG_ 66 ICBVC_100ms_Group01_Reserved72 "ICBVC_100ms_Group01_Reserved72";
BA_ "GenSigStartValue" SG_ 66 ICBVC_100ms_Group01_Reserved72 1;
BA_ "ISignalName" SG_ 66 ICBVC_100ms_Group01_Reserved72 "IICBVC_100ms_Group01_Reserved72";
BA_ "SysSignalName" SG_ 66 ICBVC_100ms_Group01_Reserved72 "ICBVC_100ms_Group01_Reserved72";
BA_ "CompuMethodName" SG_ 66 FRSeatVentCtrlSts "FRSeatVentCtrlSts";
BA_ "ISignalName" SG_ 66 FRSeatVentCtrlSts "IFRSeatVentCtrlSts";
BA_ "LongName" SG_ 66 FRSeatVentCtrlSts "Front Right Seat Vent Control Status";
BA_ "SysSignalName" SG_ 66 FRSeatVentCtrlSts "FRSeatVentCtrlSts";
BA_ "CompuMethodName" SG_ 66 ICBVC_100ms_Group01_Reserved79 "ICBVC_100ms_Group01_Reserved79";
BA_ "GenSigStartValue" SG_ 66 ICBVC_100ms_Group01_Reserved79 15;
BA_ "ISignalName" SG_ 66 ICBVC_100ms_Group01_Reserved79 "IICBVC_100ms_Group01_Reserved79";
BA_ "SysSignalName" SG_ 66 ICBVC_100ms_Group01_Reserved79 "ICBVC_100ms_Group01_Reserved79";
BA_ "CompuMethodName" SG_ 66 ICBVC_100ms_Group01_Reserved80 "ICBVC_100ms_Group01_Reserved80";
BA_ "GenSigStartValue" SG_ 66 ICBVC_100ms_Group01_Reserved80 1;
BA_ "ISignalName" SG_ 66 ICBVC_100ms_Group01_Reserved80 "IICBVC_100ms_Group01_Reserved80";
BA_ "SysSignalName" SG_ 66 ICBVC_100ms_Group01_Reserved80 "ICBVC_100ms_Group01_Reserved80";
BA_ "CompuMethodName" SG_ 66 FLSeatVentCtrlSts "FLSeatVentCtrlSts";
BA_ "ISignalName" SG_ 66 FLSeatVentCtrlSts "IFLSeatVentCtrlSts";
BA_ "LongName" SG_ 66 FLSeatVentCtrlSts "Front Left Seat Vent Control Status";
BA_ "SysSignalName" SG_ 66 FLSeatVentCtrlSts "FLSeatVentCtrlSts";
BA_ "CompuMethodName" SG_ 66 ICBVC_100ms_Group01_Reserved84 "ICBVC_100ms_Group01_Reserved84";
BA_ "GenSigStartValue" SG_ 66 ICBVC_100ms_Group01_Reserved84 1;
BA_ "ISignalName" SG_ 66 ICBVC_100ms_Group01_Reserved84 "IICBVC_100ms_Group01_Reserved84";
BA_ "SysSignalName" SG_ 66 ICBVC_100ms_Group01_Reserved84 "ICBVC_100ms_Group01_Reserved84";
BA_ "CompuMethodName" SG_ 66 FRSeatHeatCtrlSts "FRSeatHeatCtrlSts";
BA_ "ISignalName" SG_ 66 FRSeatHeatCtrlSts "IFRSeatHeatCtrlSts";
BA_ "LongName" SG_ 66 FRSeatHeatCtrlSts "Front Right Seat Heat Control Status";
BA_ "SysSignalName" SG_ 66 FRSeatHeatCtrlSts "FRSeatHeatCtrlSts";
BA_ "CompuMethodName" SG_ 66 ICBVC_100ms_Group01_Reserved92 "ICBVC_100ms_Group01_Reserved92";
BA_ "GenSigStartValue" SG_ 66 ICBVC_100ms_Group01_Reserved92 31;
BA_ "ISignalName" SG_ 66 ICBVC_100ms_Group01_Reserved92 "IICBVC_100ms_Group01_Reserved92";
BA_ "SysSignalName" SG_ 66 ICBVC_100ms_Group01_Reserved92 "ICBVC_100ms_Group01_Reserved92";
BA_ "CompuMethodName" SG_ 66 FLSeatHeatCtrlSts "FLSeatHeatCtrlSts";
BA_ "ISignalName" SG_ 66 FLSeatHeatCtrlSts "IFLSeatHeatCtrlSts";
BA_ "SysSignalName" SG_ 66 FLSeatHeatCtrlSts "FLSeatHeatCtrlSts";
BA_ "CompuMethodName" SG_ 66 ICBVC_100ms_Group01_Reserved103 "ICBVC_100ms_Group01_Reserved103";
BA_ "GenSigStartValue" SG_ 66 ICBVC_100ms_Group01_Reserved103 255;
BA_ "ISignalName" SG_ 66 ICBVC_100ms_Group01_Reserved103 "IICBVC_100ms_Group01_Reserved103";
BA_ "SysSignalName" SG_ 66 ICBVC_100ms_Group01_Reserved103 "ICBVC_100ms_Group01_Reserved103";
BA_ "CompuMethodName" SG_ 66 ICBVC_100ms_Group01_Reserved111 "ICBVC_100ms_Group01_Reserved111";
BA_ "GenSigStartValue" SG_ 66 ICBVC_100ms_Group01_Reserved111 255;
BA_ "ISignalName" SG_ 66 ICBVC_100ms_Group01_Reserved111 "IICBVC_100ms_Group01_Reserved111";
BA_ "SysSignalName" SG_ 66 ICBVC_100ms_Group01_Reserved111 "ICBVC_100ms_Group01_Reserved111";
BA_ "CompuMethodName" SG_ 66 ICBVC_100ms_Group01_Reserved119 "ICBVC_100ms_Group01_Reserved119";
BA_ "GenSigStartValue" SG_ 66 ICBVC_100ms_Group01_Reserved119 255;
BA_ "ISignalName" SG_ 66 ICBVC_100ms_Group01_Reserved119 "IICBVC_100ms_Group01_Reserved119";
BA_ "SysSignalName" SG_ 66 ICBVC_100ms_Group01_Reserved119 "ICBVC_100ms_Group01_Reserved119";
BA_ "CompuMethodName" SG_ 66 ICBVC_100ms_Group01_Reserved127 "ICBVC_100ms_Group01_Reserved127";
BA_ "GenSigStartValue" SG_ 66 ICBVC_100ms_Group01_Reserved127 255;
BA_ "ISignalName" SG_ 66 ICBVC_100ms_Group01_Reserved127 "IICBVC_100ms_Group01_Reserved127";
BA_ "SysSignalName" SG_ 66 ICBVC_100ms_Group01_Reserved127 "ICBVC_100ms_Group01_Reserved127";
BA_ "CompuMethodName" SG_ 871 AVMSt "AVMSt";
BA_ "ISignalName" SG_ 871 AVMSt "IAVMSt";
BA_ "LongName" SG_ 871 AVMSt "AVM_Display_Stats";
BA_ "SysSignalName" SG_ 871 AVMSt "AVMSt";
BA_ "CompuMethodName" SG_ 871 RstrFctryDeftsReq "RstrFctryDeftsReq";
BA_ "ISignalName" SG_ 871 RstrFctryDeftsReq "IRstrFctryDeftsReq";
BA_ "LongName" SG_ 871 RstrFctryDeftsReq "Restore Factory Defaults Request";
BA_ "SysSignalName" SG_ 871 RstrFctryDeftsReq "RstrFctryDeftsReq";
BA_ "CompuMethodName" SG_ 871 AudiopilotMICSts "AudiopilotMICSts";
BA_ "ISignalName" SG_ 871 AudiopilotMICSts "IAudiopilotMICSts";
BA_ "LongName" SG_ 871 AudiopilotMICSts "Audiopilot Microphone Stats";
BA_ "SysSignalName" SG_ 871 AudiopilotMICSts "AudiopilotMICSts";
BA_ "CompuMethodName" SG_ 871 ZXDSkndReq "ZXDSkndReq";
BA_ "ISignalName" SG_ 871 ZXDSkndReq "IZXDSkndReq";
BA_ "LongName" SG_ 871 ZXDSkndReq "ZXD_shakehand_request";
BA_ "SysSignalName" SG_ 871 ZXDSkndReq "ZXDSkndReq";
BA_ "CompuMethodName" SG_ 871 DCDCVolStptBkup "DCDCVolStptBkup";
BA_ "GenSigStartValue" SG_ 871 DCDCVolStptBkup 254;
BA_ "ISignalName" SG_ 871 DCDCVolStptBkup "IDCDCVolStptBkup";
BA_ "LongName" SG_ 871 DCDCVolStptBkup "Direct_Current_Direct_Current_Voltage_Setpoint_Backup";
BA_ "SysSignalName" SG_ 871 DCDCVolStptBkup "DCDCVolStptBkup";
BA_ "CompuMethodName" SG_ 906 NavCrntRoadTyp "NavCrntRoadTyp";
BA_ "ISignalName" SG_ 906 NavCrntRoadTyp "INavCrntRoadTyp";
BA_ "LongName" SG_ 906 NavCrntRoadTyp "Navigation_Current_Road_Type";
BA_ "SysSignalName" SG_ 906 NavCrntRoadTyp "NavCrntRoadTyp";
BA_ "CompuMethodName" SG_ 906 NavSpdLmtValUnit "NavSpdLmtValUnit";
BA_ "GenSigStartValue" SG_ 906 NavSpdLmtValUnit 2;
BA_ "ISignalName" SG_ 906 NavSpdLmtValUnit "INavSpdLmtValUnit";
BA_ "LongName" SG_ 906 NavSpdLmtValUnit "Navigation_Speed_Limit_Value_Units";
BA_ "SysSignalName" SG_ 906 NavSpdLmtValUnit "NavSpdLmtValUnit";
BA_ "CompuMethodName" SG_ 906 NavNewIconDist "NavNewIconDist";
BA_ "ISignalName" SG_ 906 NavNewIconDist "INavNewIconDist";
BA_ "LongName" SG_ 906 NavNewIconDist "Navigation_New_Icon_Distance";
BA_ "SysSignalName" SG_ 906 NavNewIconDist "NavNewIconDist";
BA_ "CompuMethodName" SG_ 906 NavSpdLmtValSts "NavSpdLmtValSts";
BA_ "GenSigStartValue" SG_ 906 NavSpdLmtValSts 2;
BA_ "ISignalName" SG_ 906 NavSpdLmtValSts "INavSpdLmtValSts";
BA_ "LongName" SG_ 906 NavSpdLmtValSts "Navigation Speed Limit Value Status";
BA_ "SysSignalName" SG_ 906 NavSpdLmtValSts "NavSpdLmtValSts";
BA_ "CompuMethodName" SG_ 906 NavDistFromFrtEleccEye "NavDistFromFrtEleccEye";
BA_ "ISignalName" SG_ 906 NavDistFromFrtEleccEye "INavDistFromFrtEleccEye";
BA_ "LongName" SG_ 906 NavDistFromFrtEleccEye "Navigation_Distance_From_Front_Electronic_Eye";
BA_ "SysSignalName" SG_ 906 NavDistFromFrtEleccEye "NavDistFromFrtEleccEye";
BA_ "CompuMethodName" SG_ 906 NavItvalSpdDetnDistRetDist "NavItvalSpdDetnDistRetDist";
BA_ "ISignalName" SG_ 906 NavItvalSpdDetnDistRetDist "INavItvalSpdDetnDistRetDist";
BA_ "LongName" SG_ 906 NavItvalSpdDetnDistRetDist "Navigation_Interval_Speed_Detection_Rest_Distance";
BA_ "SysSignalName" SG_ 906 NavItvalSpdDetnDistRetDist "NavItvalSpdDetnDistRetDist";
BA_ "CompuMethodName" SG_ 906 NavSpdLmtVal "NavSpdLmtVal";
BA_ "ISignalName" SG_ 906 NavSpdLmtVal "INavSpdLmtVal";
BA_ "LongName" SG_ 906 NavSpdLmtVal "Navigation Speed Limit Value";
BA_ "SysSignalName" SG_ 906 NavSpdLmtVal "NavSpdLmtVal";
BA_ "CompuMethodName" SG_ 906 NavCndSpdLmtVal "NavCndSpdLmtVal";
BA_ "ISignalName" SG_ 906 NavCndSpdLmtVal "INavCndSpdLmtVal";
BA_ "LongName" SG_ 906 NavCndSpdLmtVal "Navigation Conditional Speed Limit Value";
BA_ "SysSignalName" SG_ 906 NavCndSpdLmtVal "NavCndSpdLmtVal";
BA_ "CompuMethodName" SG_ 906 NavSpdLmtTyp "NavSpdLmtTyp";
BA_ "ISignalName" SG_ 906 NavSpdLmtTyp "INavSpdLmtTyp";
BA_ "LongName" SG_ 906 NavSpdLmtTyp "Navigation_Speed_Limit_Type";
BA_ "SysSignalName" SG_ 906 NavSpdLmtTyp "NavSpdLmtTyp";
BA_ "CompuMethodName" SG_ 906 NavNextRampOffset "NavNextRampOffset";
BA_ "ISignalName" SG_ 906 NavNextRampOffset "INavNextRampOffset";
BA_ "LongName" SG_ 906 NavNextRampOffset "Navigation Next Ramp Offest";
BA_ "SysSignalName" SG_ 906 NavNextRampOffset "NavNextRampOffset";
BA_ "CompuMethodName" SG_ 1104 NrwroadFwdCtlReq "NrwroadFwdCtlReq";
BA_ "ISignalName" SG_ 1104 NrwroadFwdCtlReq "INrwroadFwdCtlReq";
BA_ "LongName" SG_ 1104 NrwroadFwdCtlReq "Narrow road forward control requst";
BA_ "SysSignalName" SG_ 1104 NrwroadFwdCtlReq "NrwroadFwdCtlReq";
BA_ "CompuMethodName" SG_ 1104 AIParkngSpdsw "AIParkngSpdsw";
BA_ "ISignalName" SG_ 1104 AIParkngSpdsw "IAIParkngSpdsw";
BA_ "LongName" SG_ 1104 AIParkngSpdsw "Ai Parking speed switch";
BA_ "SysSignalName" SG_ 1104 AIParkngSpdsw "AIParkngSpdsw";
BA_ "CompuMethodName" SG_ 1104 NrwroadsltReq "NrwroadsltReq";
BA_ "ISignalName" SG_ 1104 NrwroadsltReq "INrwroadsltReq";
BA_ "LongName" SG_ 1104 NrwroadsltReq "Narrow road forwardsilentlyReq";
BA_ "SysSignalName" SG_ 1104 NrwroadsltReq "NrwroadsltReq";
BA_ "CompuMethodName" SG_ 1104 NrwroadFwdReq "NrwroadFwdReq";
BA_ "ISignalName" SG_ 1104 NrwroadFwdReq "INrwroadFwdReq";
BA_ "LongName" SG_ 1104 NrwroadFwdReq "Narrow road forwardReq";
BA_ "SysSignalName" SG_ 1104 NrwroadFwdReq "NrwroadFwdReq";
BA_ "CompuMethodName" SG_ 1104 MemPkngSwReq "MemPkngSwReq";
BA_ "ISignalName" SG_ 1104 MemPkngSwReq "IMemPkngSwReq";
BA_ "LongName" SG_ 1104 MemPkngSwReq "Memory_Parking_Switch_Request";
BA_ "SysSignalName" SG_ 1104 MemPkngSwReq "MemPkngSwReq";
BA_ "CompuMethodName" SG_ 1104 MemPkngSlntPtrlEnbSwReq "MemPkngSlntPtrlEnbSwReq";
BA_ "ISignalName" SG_ 1104 MemPkngSlntPtrlEnbSwReq "IMemPkngSlntPtrlEnbSwReq";
BA_ "LongName" SG_ 1104 MemPkngSlntPtrlEnbSwReq "Memory_Parking_Silent_Patrol_Enable_Switch_Request";
BA_ "SysSignalName" SG_ 1104 MemPkngSlntPtrlEnbSwReq "MemPkngSlntPtrlEnbSwReq";
BA_ "CompuMethodName" SG_ 832 FCWSnstvtLvlReq "FCWSnstvtLvlReq";
BA_ "ISignalName" SG_ 832 FCWSnstvtLvlReq "IFCWSnstvtLvlReq";
BA_ "LongName" SG_ 832 FCWSnstvtLvlReq "Forward_Collision_Warning_Sensitivity_Level_Request";
BA_ "SysSignalName" SG_ 832 FCWSnstvtLvlReq "FCWSnstvtLvlReq";
BA_ "CompuMethodName" SG_ 832 ELKSwReq "ELKSwReq";
BA_ "ISignalName" SG_ 832 ELKSwReq "IELKSwReq";
BA_ "LongName" SG_ 832 ELKSwReq "Emergency Lane Keeping Switch Request";
BA_ "SysSignalName" SG_ 832 ELKSwReq "ELKSwReq";
BA_ "CompuMethodName" SG_ 832 LDWAdoWrnngReq "LDWAdoWrnngReq";
BA_ "ISignalName" SG_ 832 LDWAdoWrnngReq "ILDWAdoWrnngReq";
BA_ "LongName" SG_ 832 LDWAdoWrnngReq "Lane_Departure_Warning_Audio_Warning_Request";
BA_ "SysSignalName" SG_ 832 LDWAdoWrnngReq "LDWAdoWrnngReq";
BA_ "CompuMethodName" SG_ 832 FCWSwReq "FCWSwReq";
BA_ "ISignalName" SG_ 832 FCWSwReq "IFCWSwReq";
BA_ "LongName" SG_ 832 FCWSwReq "Forward_Collision_Warning_Switch_Request";
BA_ "SysSignalName" SG_ 832 FCWSwReq "FCWSwReq";
BA_ "CompuMethodName" SG_ 832 TrfcLghtFuctionSwReq "TrfcLghtFuctionSwReq";
BA_ "ISignalName" SG_ 832 TrfcLghtFuctionSwReq "ITrfcLghtFuctionSwReq";
BA_ "LongName" SG_ 832 TrfcLghtFuctionSwReq "Traffic_Light_Fuction_Switch_Request";
BA_ "SysSignalName" SG_ 832 TrfcLghtFuctionSwReq "TrfcLghtFuctionSwReq";
BA_ "CompuMethodName" SG_ 832 DOWSelReq "DOWSelReq";
BA_ "ISignalName" SG_ 832 DOWSelReq "IDOWSelReq";
BA_ "LongName" SG_ 832 DOWSelReq "Door Open Warning Select Request";
BA_ "SysSignalName" SG_ 832 DOWSelReq "DOWSelReq";
BA_ "CompuMethodName" SG_ 832 BSDSelReq "BSDSelReq";
BA_ "ISignalName" SG_ 832 BSDSelReq "IBSDSelReq";
BA_ "LongName" SG_ 832 BSDSelReq "Blind Spot Detect Select Request";
BA_ "SysSignalName" SG_ 832 BSDSelReq "BSDSelReq";
BA_ "CompuMethodName" SG_ 832 AEBSwReq "AEBSwReq";
BA_ "ISignalName" SG_ 832 AEBSwReq "IAEBSwReq";
BA_ "LongName" SG_ 832 AEBSwReq "Autonomous_Emergency_Braking_Switch_Request";
BA_ "SysSignalName" SG_ 832 AEBSwReq "AEBSwReq";
BA_ "CompuMethodName" SG_ 832 LDWLKAHptWrnngReq "LDWLKAHptWrnngReq";
BA_ "ISignalName" SG_ 832 LDWLKAHptWrnngReq "ILDWLKAHptWrnngReq";
BA_ "LongName" SG_ 832 LDWLKAHptWrnngReq "Lane_Departure_Warning_Lane_Keeping_Haptic_Assist_Warning_Request";
BA_ "SysSignalName" SG_ 832 LDWLKAHptWrnngReq "LDWLKAHptWrnngReq";
BA_ "CompuMethodName" SG_ 832 RCWSelReq "RCWSelReq";
BA_ "ISignalName" SG_ 832 RCWSelReq "IRCWSelReq";
BA_ "LongName" SG_ 832 RCWSelReq "Rear Collision Warning Select Request";
BA_ "SysSignalName" SG_ 832 RCWSelReq "RCWSelReq";
BA_ "CompuMethodName" SG_ 832 NarwSpcAstSwReq "NarwSpcAstSwReq";
BA_ "ISignalName" SG_ 832 NarwSpcAstSwReq "INarwSpcAstSwReq";
BA_ "LongName" SG_ 832 NarwSpcAstSwReq "Narrow Space Assist Switch Request";
BA_ "SysSignalName" SG_ 832 NarwSpcAstSwReq "NarwSpcAstSwReq";
BA_ "CompuMethodName" SG_ 832 LDWSnstvtLvlReq "LDWSnstvtLvlReq";
BA_ "ISignalName" SG_ 832 LDWSnstvtLvlReq "ILDWSnstvtLvlReq";
BA_ "LongName" SG_ 832 LDWSnstvtLvlReq "Lane_Departure_Warning_Sensitivity_Level_Request";
BA_ "SysSignalName" SG_ 832 LDWSnstvtLvlReq "LDWSnstvtLvlReq";
BA_ "CompuMethodName" SG_ 832 RDASwReq "RDASwReq";
BA_ "ISignalName" SG_ 832 RDASwReq "IRDASwReq";
BA_ "LongName" SG_ 832 RDASwReq "Rear Drive Assist Switch Request";
BA_ "SysSignalName" SG_ 832 RDASwReq "RDASwReq";
BA_ "CompuMethodName" SG_ 832 RCTSysSelReq "RCTSysSelReq";
BA_ "ISignalName" SG_ 832 RCTSysSelReq "IRCTSysSelReq";
BA_ "LongName" SG_ 832 RCTSysSelReq "Rear Cross Traffic System Select Request";
BA_ "SysSignalName" SG_ 832 RCTSysSelReq "RCTSysSelReq";
BA_ "CompuMethodName" SG_ 832 LCASelReq "LCASelReq";
BA_ "ISignalName" SG_ 832 LCASelReq "ILCASelReq";
BA_ "LongName" SG_ 832 LCASelReq "Lane Change Assist Select Request";
BA_ "SysSignalName" SG_ 832 LCASelReq "LCASelReq";
BA_ "CompuMethodName" SG_ 832 LDWLKASwReq "LDWLKASwReq";
BA_ "ISignalName" SG_ 832 LDWLKASwReq "ILDWLKASwReq";
BA_ "LongName" SG_ 832 LDWLKASwReq "Lane_Departure_Warning_Lane_Keeping_Assist_Switch_Request";
BA_ "SysSignalName" SG_ 832 LDWLKASwReq "LDWLKASwReq";
BA_ "CompuMethodName" SG_ 482 ICBVC_50ms_Group11_CRC "ICBVC_50ms_Group11_CRC";
BA_ "ISignalName" SG_ 482 ICBVC_50ms_Group11_CRC "IICBVC_50ms_Group11_CRC";
BA_ "SysSignalName" SG_ 482 ICBVC_50ms_Group11_CRC "ICBVC_50ms_Group11_CRC";
BA_ "CompuMethodName" SG_ 482 ICBVC_50ms_Group11_RC "ICBVC_50ms_Group11_RC";
BA_ "ISignalName" SG_ 482 ICBVC_50ms_Group11_RC "IICBVC_50ms_Group11_RC";
BA_ "SysSignalName" SG_ 482 ICBVC_50ms_Group11_RC "ICBVC_50ms_Group11_RC";
BA_ "CompuMethodName" SG_ 482 TrPfShftPtrnSw3A "TrPfShftPtrnSw3A";
BA_ "ISignalName" SG_ 482 TrPfShftPtrnSw3A "ITrPfShftPtrnSw3A";
BA_ "SysSignalName" SG_ 482 TrPfShftPtrnSw3A "TrPfShftPtrnSw3A";
BA_ "CompuMethodName" SG_ 482 TrPfShftPtrnSw2A "TrPfShftPtrnSw2A";
BA_ "ISignalName" SG_ 482 TrPfShftPtrnSw2A "ITrPfShftPtrnSw2A";
BA_ "SysSignalName" SG_ 482 TrPfShftPtrnSw2A "TrPfShftPtrnSw2A";
BA_ "CompuMethodName" SG_ 482 PfTrTapUpDwnSwSta "PfTrTapUpDwnSwSta";
BA_ "ISignalName" SG_ 482 PfTrTapUpDwnSwSta "IPfTrTapUpDwnSwSta";
BA_ "SysSignalName" SG_ 482 PfTrTapUpDwnSwSta "PfTrTapUpDwnSwSta";
BA_ "CompuMethodName" SG_ 482 ICBVC_50ms_Group11_Reserved1 "ICBVC_50ms_Group11_Reserved1";
BA_ "GenSigStartValue" SG_ 482 ICBVC_50ms_Group11_Reserved1 255;
BA_ "ISignalName" SG_ 482 ICBVC_50ms_Group11_Reserved1 "IICBVC_50ms_Group11_Reserved1";
BA_ "SysSignalName" SG_ 482 ICBVC_50ms_Group11_Reserved1 "ICBVC_50ms_Group11_Reserved1";
BA_ "CompuMethodName" SG_ 482 ICBVC_50ms_Group11_Reserved2 "ICBVC_50ms_Group11_Reserved2";
BA_ "GenSigStartValue" SG_ 482 ICBVC_50ms_Group11_Reserved2 255;
BA_ "ISignalName" SG_ 482 ICBVC_50ms_Group11_Reserved2 "IICBVC_50ms_Group11_Reserved2";
BA_ "SysSignalName" SG_ 482 ICBVC_50ms_Group11_Reserved2 "ICBVC_50ms_Group11_Reserved2";
BA_ "CompuMethodName" SG_ 482 StrgWhlTipcSwDataIntgty "StrgWhlTipcSwDataIntgty";
BA_ "ISignalName" SG_ 482 StrgWhlTipcSwDataIntgty "IStrgWhlTipcSwDataIntgty";
BA_ "SysSignalName" SG_ 482 StrgWhlTipcSwDataIntgty "StrgWhlTipcSwDataIntgty";
BA_ "CompuMethodName" SG_ 482 ICBVC_50ms_Group11_Reserved3 "ICBVC_50ms_Group11_Reserved3";
BA_ "GenSigStartValue" SG_ 482 ICBVC_50ms_Group11_Reserved3 1;
BA_ "ISignalName" SG_ 482 ICBVC_50ms_Group11_Reserved3 "IICBVC_50ms_Group11_Reserved3";
BA_ "SysSignalName" SG_ 482 ICBVC_50ms_Group11_Reserved3 "ICBVC_50ms_Group11_Reserved3";
BA_ "CompuMethodName" SG_ 482 CCSwStsDistIncSwA "CCSwStsDistIncSwA";
BA_ "ISignalName" SG_ 482 CCSwStsDistIncSwA "ICCSwStsDistIncSwA";
BA_ "LongName" SG_ 482 CCSwStsDistIncSwA "Cruise_Control_Switch_Status_Distance_Increase_Switch_Active";
BA_ "SysSignalName" SG_ 482 CCSwStsDistIncSwA "CCSwStsDistIncSwA";
BA_ "CompuMethodName" SG_ 482 CCSwStsDistDecSwA "CCSwStsDistDecSwA";
BA_ "ISignalName" SG_ 482 CCSwStsDistDecSwA "ICCSwStsDistDecSwA";
BA_ "LongName" SG_ 482 CCSwStsDistDecSwA "Cruise_Control_Switch_Status_Distance_Decrease_Switch_Active";
BA_ "SysSignalName" SG_ 482 CCSwStsDistDecSwA "CCSwStsDistDecSwA";
BA_ "CompuMethodName" SG_ 482 CCSwStsSpdIncSwA "CCSwStsSpdIncSwA";
BA_ "ISignalName" SG_ 482 CCSwStsSpdIncSwA "ICCSwStsSpdIncSwA";
BA_ "LongName" SG_ 482 CCSwStsSpdIncSwA "Cruise_Control_Switch_Status_Speed_Increase_Switch_Active";
BA_ "SysSignalName" SG_ 482 CCSwStsSpdIncSwA "CCSwStsSpdIncSwA";
BA_ "CompuMethodName" SG_ 482 CCSwStsSpdDecSwA "CCSwStsSpdDecSwA";
BA_ "ISignalName" SG_ 482 CCSwStsSpdDecSwA "ICCSwStsSpdDecSwA";
BA_ "LongName" SG_ 482 CCSwStsSpdDecSwA "Cruise_Control_Switch_Status_Speed_Decrease_Switch_Active";
BA_ "SysSignalName" SG_ 482 CCSwStsSpdDecSwA "CCSwStsSpdDecSwA";
BA_ "CompuMethodName" SG_ 482 CCSwStsSwDataIntgty "CCSwStsSwDataIntgty";
BA_ "ISignalName" SG_ 482 CCSwStsSwDataIntgty "ICCSwStsSwDataIntgty";
BA_ "LongName" SG_ 482 CCSwStsSwDataIntgty "CCSw Sts Sw Data Intgty";
BA_ "SysSignalName" SG_ 482 CCSwStsSwDataIntgty "CCSwStsSwDataIntgty";
BA_ "CompuMethodName" SG_ 482 CCSwStsOnSwA "CCSwStsOnSwA";
BA_ "ISignalName" SG_ 482 CCSwStsOnSwA "ICCSwStsOnSwA";
BA_ "LongName" SG_ 482 CCSwStsOnSwA "CCSw Sts On Sw A";
BA_ "SysSignalName" SG_ 482 CCSwStsOnSwA "CCSwStsOnSwA";
BA_ "CompuMethodName" SG_ 482 CCSwStsCanclSwA "CCSwStsCanclSwA";
BA_ "ISignalName" SG_ 482 CCSwStsCanclSwA "ICCSwStsCanclSwA";
BA_ "LongName" SG_ 482 CCSwStsCanclSwA "CCSw Sts Cancl Sw A";
BA_ "SysSignalName" SG_ 482 CCSwStsCanclSwA "CCSwStsCanclSwA";
BA_ "CompuMethodName" SG_ 482 PfTrTapUpDwnEnbSwSta "PfTrTapUpDwnEnbSwSta";
BA_ "ISignalName" SG_ 482 PfTrTapUpDwnEnbSwSta "IPfTrTapUpDwnEnbSwSta";
BA_ "SysSignalName" SG_ 482 PfTrTapUpDwnEnbSwSta "PfTrTapUpDwnEnbSwSta";
BA_ "CompuMethodName" SG_ 482 PfTrTapUpDwnSecySwSta "PfTrTapUpDwnSecySwSta";
BA_ "ISignalName" SG_ 482 PfTrTapUpDwnSecySwSta "IPfTrTapUpDwnSecySwSta";
BA_ "SysSignalName" SG_ 482 PfTrTapUpDwnSecySwSta "PfTrTapUpDwnSecySwSta";
BA_ "CompuMethodName" SG_ 482 ICBVC_50ms_Group11_Reserved4 "ICBVC_50ms_Group11_Reserved4";
BA_ "GenSigStartValue" SG_ 482 ICBVC_50ms_Group11_Reserved4 3;
BA_ "ISignalName" SG_ 482 ICBVC_50ms_Group11_Reserved4 "IICBVC_50ms_Group11_Reserved4";
BA_ "SysSignalName" SG_ 482 ICBVC_50ms_Group11_Reserved4 "ICBVC_50ms_Group11_Reserved4";
BA_ "CompuMethodName" SG_ 482 TrPfShftPtrnSw1A "TrPfShftPtrnSw1A";
BA_ "ISignalName" SG_ 482 TrPfShftPtrnSw1A "ITrPfShftPtrnSw1A";
BA_ "SysSignalName" SG_ 482 TrPfShftPtrnSw1A "TrPfShftPtrnSw1A";
BA_ "CompuMethodName" SG_ 482 ICBVC_50ms_Group11_Reserved5 "ICBVC_50ms_Group11_Reserved5";
BA_ "GenSigStartValue" SG_ 482 ICBVC_50ms_Group11_Reserved5 1;
BA_ "ISignalName" SG_ 482 ICBVC_50ms_Group11_Reserved5 "IICBVC_50ms_Group11_Reserved5";
BA_ "SysSignalName" SG_ 482 ICBVC_50ms_Group11_Reserved5 "ICBVC_50ms_Group11_Reserved5";
BA_ "CompuMethodName" SG_ 482 SWSSelUpSwA "SWSSelUpSwA";
BA_ "ISignalName" SG_ 482 SWSSelUpSwA "ISWSSelUpSwA";
BA_ "LongName" SG_ 482 SWSSelUpSwA "Steering Wheel Switch Select Up Switch Active_l";
BA_ "SysSignalName" SG_ 482 SWSSelUpSwA "SWSSelUpSwA";
BA_ "CompuMethodName" SG_ 482 SWSSelRSwA "SWSSelRSwA";
BA_ "ISignalName" SG_ 482 SWSSelRSwA "ISWSSelRSwA";
BA_ "LongName" SG_ 482 SWSSelRSwA "Steering Wheel Switch Select Right Switch Active_l";
BA_ "SysSignalName" SG_ 482 SWSSelRSwA "SWSSelRSwA";
BA_ "CompuMethodName" SG_ 482 SWSSelLSwA "SWSSelLSwA";
BA_ "ISignalName" SG_ 482 SWSSelLSwA "ISWSSelLSwA";
BA_ "LongName" SG_ 482 SWSSelLSwA "Steering Wheel Switch Select Left Switch Active_l";
BA_ "SysSignalName" SG_ 482 SWSSelLSwA "SWSSelLSwA";
BA_ "CompuMethodName" SG_ 482 SWSSelDwnSwA "SWSSelDwnSwA";
BA_ "ISignalName" SG_ 482 SWSSelDwnSwA "ISWSSelDwnSwA";
BA_ "LongName" SG_ 482 SWSSelDwnSwA "Steering Wheel Switch Select Down Switch Active_l";
BA_ "SysSignalName" SG_ 482 SWSSelDwnSwA "SWSSelDwnSwA";
BA_ "CompuMethodName" SG_ 482 SWSCnfmSwA "SWSCnfmSwA";
BA_ "ISignalName" SG_ 482 SWSCnfmSwA "ISWSCnfmSwA";
BA_ "LongName" SG_ 482 SWSCnfmSwA "Steering Wheel Switch Confirm Switch Active_l";
BA_ "SysSignalName" SG_ 482 SWSCnfmSwA "SWSCnfmSwA";
BA_ "CompuMethodName" SG_ 482 CCSwStsRsmSwA "CCSwStsRsmSwA";
BA_ "ISignalName" SG_ 482 CCSwStsRsmSwA "ICCSwStsRsmSwA";
BA_ "LongName" SG_ 482 CCSwStsRsmSwA "CCSw Sts Rsm Sw A";
BA_ "SysSignalName" SG_ 482 CCSwStsRsmSwA "CCSwStsRsmSwA";
BA_ "CompuMethodName" SG_ 482 ICBVC_50ms_Group11_Reserved6 "ICBVC_50ms_Group11_Reserved6";
BA_ "GenSigStartValue" SG_ 482 ICBVC_50ms_Group11_Reserved6 1;
BA_ "ISignalName" SG_ 482 ICBVC_50ms_Group11_Reserved6 "IICBVC_50ms_Group11_Reserved6";
BA_ "SysSignalName" SG_ 482 ICBVC_50ms_Group11_Reserved6 "ICBVC_50ms_Group11_Reserved6";
BA_ "CompuMethodName" SG_ 482 HMISafFltsts "HMISafFltsts";
BA_ "ISignalName" SG_ 482 HMISafFltsts "IHMISafFltsts";
BA_ "LongName" SG_ 482 HMISafFltsts "HMI_Safety_Fault_Status";
BA_ "SysSignalName" SG_ 482 HMISafFltsts "HMISafFltsts";
BA_ "CompuMethodName" SG_ 482 SwStaE2EErr "SwStaE2EErr";
BA_ "ISignalName" SG_ 482 SwStaE2EErr "ISwStaE2EErr";
BA_ "LongName" SG_ 482 SwStaE2EErr "Switch_Status_E2E_Error";
BA_ "SysSignalName" SG_ 482 SwStaE2EErr "SwStaE2EErr";
BA_ "CompuMethodName" SG_ 482 TrPfShftPtrnSw4A "TrPfShftPtrnSw4A";
BA_ "ISignalName" SG_ 482 TrPfShftPtrnSw4A "ITrPfShftPtrnSw4A";
BA_ "SysSignalName" SG_ 482 TrPfShftPtrnSw4A "TrPfShftPtrnSw4A";
BA_ "CompuMethodName" SG_ 1010 ICBVC_50ms_Group13_CRC "ICBVC_50ms_Group13_CRC";
BA_ "ISignalName" SG_ 1010 ICBVC_50ms_Group13_CRC "IICBVC_50ms_Group13_CRC";
BA_ "LongName" SG_ 1010 ICBVC_50ms_Group13_CRC "ICBVC_50ms_Group13_CRC";
BA_ "SysSignalName" SG_ 1010 ICBVC_50ms_Group13_CRC "ICBVC_50ms_Group13_CRC";
BA_ "CompuMethodName" SG_ 1010 ICBVC_50ms_Group13_RC "ICBVC_50ms_Group13_RC";
BA_ "ISignalName" SG_ 1010 ICBVC_50ms_Group13_RC "IICBVC_50ms_Group13_RC";
BA_ "LongName" SG_ 1010 ICBVC_50ms_Group13_RC "ICBVC_50ms_Group13_RC";
BA_ "SysSignalName" SG_ 1010 ICBVC_50ms_Group13_RC "ICBVC_50ms_Group13_RC";
BA_ "CompuMethodName" SG_ 1010 ICBVC_50ms_Group13_Reserved1 "ICBVC_50ms_Group13_Reserved1";
BA_ "GenSigStartValue" SG_ 1010 ICBVC_50ms_Group13_Reserved1 15;
BA_ "ISignalName" SG_ 1010 ICBVC_50ms_Group13_Reserved1 "IICBVC_50ms_Group13_Reserved1";
BA_ "SysSignalName" SG_ 1010 ICBVC_50ms_Group13_Reserved1 "ICBVC_50ms_Group13_Reserved1";
BA_ "CompuMethodName" SG_ 1010 ICBVC_50ms_Group13_Reserved2 "ICBVC_50ms_Group13_Reserved2";
BA_ "GenSigStartValue" SG_ 1010 ICBVC_50ms_Group13_Reserved2 255;
BA_ "ISignalName" SG_ 1010 ICBVC_50ms_Group13_Reserved2 "IICBVC_50ms_Group13_Reserved2";
BA_ "SysSignalName" SG_ 1010 ICBVC_50ms_Group13_Reserved2 "ICBVC_50ms_Group13_Reserved2";
BA_ "CompuMethodName" SG_ 1010 ICBVC_50ms_Group13_Reserved3 "ICBVC_50ms_Group13_Reserved3";
BA_ "GenSigStartValue" SG_ 1010 ICBVC_50ms_Group13_Reserved3 255;
BA_ "ISignalName" SG_ 1010 ICBVC_50ms_Group13_Reserved3 "IICBVC_50ms_Group13_Reserved3";
BA_ "SysSignalName" SG_ 1010 ICBVC_50ms_Group13_Reserved3 "ICBVC_50ms_Group13_Reserved3";
BA_ "CompuMethodName" SG_ 1010 TgtParkingChosed "TgtParkingChosed";
BA_ "ISignalName" SG_ 1010 TgtParkingChosed "ITgtParkingChosed";
BA_ "LongName" SG_ 1010 TgtParkingChosed "Target_Parking_Chosed";
BA_ "SysSignalName" SG_ 1010 TgtParkingChosed "TgtParkingChosed";
BA_ "CompuMethodName" SG_ 1010 SpdLmtMdFICM "SpdLmtMdFICM";
BA_ "ISignalName" SG_ 1010 SpdLmtMdFICM "ISpdLmtMdFICM";
BA_ "LongName" SG_ 1010 SpdLmtMdFICM "Speed Limit Modle FICM";
BA_ "SysSignalName" SG_ 1010 SpdLmtMdFICM "SpdLmtMdFICM";
BA_ "CompuMethodName" SG_ 1010 AutocParkngSwReq "AutocParkngSwReq";
BA_ "ISignalName" SG_ 1010 AutocParkngSwReq "IAutocParkngSwReq";
BA_ "LongName" SG_ 1010 AutocParkngSwReq "Auto Parking Switch Request";
BA_ "SysSignalName" SG_ 1010 AutocParkngSwReq "AutocParkngSwReq";
BA_ "CompuMethodName" SG_ 1010 IMATESysSts "IMATESysSts";
BA_ "ISignalName" SG_ 1010 IMATESysSts "IIMATESysSts";
BA_ "SysSignalName" SG_ 1010 IMATESysSts "IMATESysSts";
BA_ "CompuMethodName" SG_ 1010 ICBVC_50ms_Group13_Reserved4 "ICBVC_50ms_Group13_Reserved4";
BA_ "GenSigStartValue" SG_ 1010 ICBVC_50ms_Group13_Reserved4 31;
BA_ "ISignalName" SG_ 1010 ICBVC_50ms_Group13_Reserved4 "IICBVC_50ms_Group13_Reserved4";
BA_ "SysSignalName" SG_ 1010 ICBVC_50ms_Group13_Reserved4 "ICBVC_50ms_Group13_Reserved4";
BA_ "CompuMethodName" SG_ 1010 ICBVC_50ms_Group13_Reserved5 "ICBVC_50ms_Group13_Reserved5";
BA_ "GenSigStartValue" SG_ 1010 ICBVC_50ms_Group13_Reserved5 255;
BA_ "ISignalName" SG_ 1010 ICBVC_50ms_Group13_Reserved5 "IICBVC_50ms_Group13_Reserved5";
BA_ "SysSignalName" SG_ 1010 ICBVC_50ms_Group13_Reserved5 "ICBVC_50ms_Group13_Reserved5";
BA_ "CompuMethodName" SG_ 1010 PwrMdCtrlResp "PwrMdCtrlResp";
BA_ "ISignalName" SG_ 1010 PwrMdCtrlResp "IPwrMdCtrlResp";
BA_ "LongName" SG_ 1010 PwrMdCtrlResp "Power mode control Response";
BA_ "SysSignalName" SG_ 1010 PwrMdCtrlResp "PwrMdCtrlResp";
BA_ "CompuMethodName" SG_ 1010 ICBVC_50ms_Group13_Reserved6 "ICBVC_50ms_Group13_Reserved6";
BA_ "GenSigStartValue" SG_ 1010 ICBVC_50ms_Group13_Reserved6 31;
BA_ "ISignalName" SG_ 1010 ICBVC_50ms_Group13_Reserved6 "IICBVC_50ms_Group13_Reserved6";
BA_ "SysSignalName" SG_ 1010 ICBVC_50ms_Group13_Reserved6 "ICBVC_50ms_Group13_Reserved6";
BA_ "CompuMethodName" SG_ 1010 ICBVC_50ms_Group13_Reserved7 "ICBVC_50ms_Group13_Reserved7";
BA_ "GenSigStartValue" SG_ 1010 ICBVC_50ms_Group13_Reserved7 255;
BA_ "ISignalName" SG_ 1010 ICBVC_50ms_Group13_Reserved7 "IICBVC_50ms_Group13_Reserved7";
BA_ "SysSignalName" SG_ 1010 ICBVC_50ms_Group13_Reserved7 "ICBVC_50ms_Group13_Reserved7";
BA_ "CompuMethodName" SG_ 1010 ICBVC_50ms_Group13_Reserved8 "ICBVC_50ms_Group13_Reserved8";
BA_ "GenSigStartValue" SG_ 1010 ICBVC_50ms_Group13_Reserved8 255;
BA_ "ISignalName" SG_ 1010 ICBVC_50ms_Group13_Reserved8 "IICBVC_50ms_Group13_Reserved8";
BA_ "SysSignalName" SG_ 1010 ICBVC_50ms_Group13_Reserved8 "ICBVC_50ms_Group13_Reserved8";
BA_ "CompuMethodName" SG_ 1010 ICBVC_50ms_Group13_Reserved10 "ICBVC_50ms_Group13_Reserved10";
BA_ "GenSigStartValue" SG_ 1010 ICBVC_50ms_Group13_Reserved10 31;
BA_ "ISignalName" SG_ 1010 ICBVC_50ms_Group13_Reserved10 "IICBVC_50ms_Group13_Reserved10";
BA_ "SysSignalName" SG_ 1010 ICBVC_50ms_Group13_Reserved10 "ICBVC_50ms_Group13_Reserved10";
BA_ "CompuMethodName" SG_ 1010 FRDircnLghtFltsts "FRDircnLghtFltsts";
BA_ "ISignalName" SG_ 1010 FRDircnLghtFltsts "IFRDircnLghtFltsts";
BA_ "LongName" SG_ 1010 FRDircnLghtFltsts "Right_Front_Direction_Light_Fault_Status";
BA_ "SysSignalName" SG_ 1010 FRDircnLghtFltsts "FRDircnLghtFltsts";
BA_ "CompuMethodName" SG_ 1010 ICBVC_50ms_Group13_Reserved9 "ICBVC_50ms_Group13_Reserved9";
BA_ "GenSigStartValue" SG_ 1010 ICBVC_50ms_Group13_Reserved9 1;
BA_ "ISignalName" SG_ 1010 ICBVC_50ms_Group13_Reserved9 "IICBVC_50ms_Group13_Reserved9";
BA_ "SysSignalName" SG_ 1010 ICBVC_50ms_Group13_Reserved9 "ICBVC_50ms_Group13_Reserved9";
BA_ "CompuMethodName" SG_ 1010 FLDircnLghtFltsts "FLDircnLghtFltsts";
BA_ "ISignalName" SG_ 1010 FLDircnLghtFltsts "IFLDircnLghtFltsts";
BA_ "LongName" SG_ 1010 FLDircnLghtFltsts "Left_Front_Direction_Light_Fault_Status";
BA_ "SysSignalName" SG_ 1010 FLDircnLghtFltsts "FLDircnLghtFltsts";
BA_ "CompuMethodName" SG_ 1010 ICBVC_50ms_Group13_Reserved12 "ICBVC_50ms_Group13_Reserved12";
BA_ "GenSigStartValue" SG_ 1010 ICBVC_50ms_Group13_Reserved12 7;
BA_ "ISignalName" SG_ 1010 ICBVC_50ms_Group13_Reserved12 "IICBVC_50ms_Group13_Reserved12";
BA_ "SysSignalName" SG_ 1010 ICBVC_50ms_Group13_Reserved12 "ICBVC_50ms_Group13_Reserved12";
BA_ "CompuMethodName" SG_ 1010 FrSsdManuCtrl "FrSsdManuCtrl";
BA_ "ISignalName" SG_ 1010 FrSsdManuCtrl "IFrSsdManuCtrl";
BA_ "LongName" SG_ 1010 FrSsdManuCtrl "Front_Sunshade_Manual_Control";
BA_ "SysSignalName" SG_ 1010 FrSsdManuCtrl "FrSsdManuCtrl";
BA_ "CompuMethodName" SG_ 1010 ICBVC_50ms_Group13_Reserved11 "ICBVC_50ms_Group13_Reserved11";
BA_ "GenSigStartValue" SG_ 1010 ICBVC_50ms_Group13_Reserved11 7;
BA_ "ISignalName" SG_ 1010 ICBVC_50ms_Group13_Reserved11 "IICBVC_50ms_Group13_Reserved11";
BA_ "SysSignalName" SG_ 1010 ICBVC_50ms_Group13_Reserved11 "ICBVC_50ms_Group13_Reserved11";
BA_ "CompuMethodName" SG_ 1010 ICBVC_50ms_Group13_Reserved13 "ICBVC_50ms_Group13_Reserved13";
BA_ "GenSigStartValue" SG_ 1010 ICBVC_50ms_Group13_Reserved13 255;
BA_ "ISignalName" SG_ 1010 ICBVC_50ms_Group13_Reserved13 "IICBVC_50ms_Group13_Reserved13";
BA_ "SysSignalName" SG_ 1010 ICBVC_50ms_Group13_Reserved13 "ICBVC_50ms_Group13_Reserved13";
BA_ "CompuMethodName" SG_ 1010 ICBVC_50ms_Group13_Reserved14 "ICBVC_50ms_Group13_Reserved14";
BA_ "GenSigStartValue" SG_ 1010 ICBVC_50ms_Group13_Reserved14 255;
BA_ "ISignalName" SG_ 1010 ICBVC_50ms_Group13_Reserved14 "IICBVC_50ms_Group13_Reserved14";
BA_ "SysSignalName" SG_ 1010 ICBVC_50ms_Group13_Reserved14 "ICBVC_50ms_Group13_Reserved14";
BA_ "CompuMethodName" SG_ 1010 ICBVC_50ms_Group13_Reserved15 "ICBVC_50ms_Group13_Reserved15";
BA_ "GenSigStartValue" SG_ 1010 ICBVC_50ms_Group13_Reserved15 255;
BA_ "ISignalName" SG_ 1010 ICBVC_50ms_Group13_Reserved15 "IICBVC_50ms_Group13_Reserved15";
BA_ "SysSignalName" SG_ 1010 ICBVC_50ms_Group13_Reserved15 "ICBVC_50ms_Group13_Reserved15";
BA_ "CompuMethodName" SG_ 1010 ICBVC_50ms_Group13_Reserved16 "ICBVC_50ms_Group13_Reserved16";
BA_ "GenSigStartValue" SG_ 1010 ICBVC_50ms_Group13_Reserved16 255;
BA_ "ISignalName" SG_ 1010 ICBVC_50ms_Group13_Reserved16 "IICBVC_50ms_Group13_Reserved16";
BA_ "SysSignalName" SG_ 1010 ICBVC_50ms_Group13_Reserved16 "ICBVC_50ms_Group13_Reserved16";
VAL_ 820 DILampsCtrl 0 "DILampsCtrl_0_No_Request" 1 "DILampsCtrl_1_Left_ON" 2 "DILampsCtrl_2_Right_ON" 3 "DILampsCtrl_3_OFF";
VAL_ 820 AutoLaneChngSetResp 0 "AutoLaneChngSetResp_0_unavailable" 1 "AutoLaneChngSetResp_1_Level1" 2 "AutoLaneChngSetResp_2_Level2" 3 "AutoLaneChngSetResp_3_Level3";
VAL_ 820 AutoLaneChngSwDspCmd 0 "AutoLaneChngSwDspCmd_0_unavailable" 1 "AutoLaneChngSwDspCmd_1_off" 2 "AutoLaneChngSwDspCmd_2_LaneChangeSuggestion" 3 "AutoLaneChngSwDspCmd_3_AlcWithDriver" 4 "AutoLaneChngSwDspCmd_4_AlcWithoutDriver_reserved" 5 "AutoLaneChngSwDspCmd_5_Reserved" 6 "AutoLaneChngSwDspCmd_6_Reserved" 7 "AutoLaneChngSwDspCmd_7_Reserved";
VAL_ 820 AutoLaneChngMsgReq 0 "AutoLaneChngMsgReq_0_NoDisplay" 1 "AutoLaneChngMsgReq_1_LaneChangeInhibit" 2 "AutoLaneChngMsgReq_2_WaitingForLaneChangeStarting" 3 "AutoLaneChngMsgReq_3_LaneChangeInProgress" 4 "AutoLaneChngMsgReq_4_LaneChangeSucces" 5 "AutoLaneChngMsgReq_5_LaneChangeFailed" 6 "AutoLaneChngMsgReq_6_LaneChangeSuppressByDriver" 7 "AutoLaneChngMsgReq_7_ReturnToEgoLaneByDriver" 8 "AutoLaneChngMsgReq_8_ReturnToEgoLaneByALC" 9 "AutoLaneChngMsgReq_9_LaneChange_ManoeuvreWithRisk" 16 "AutoLaneChngMsgReq_16_ReturnToEgoLaneSuccess" 17 "AutoLaneChngMsgReq_17_TOR" 18 "AutoLaneChngMsgReq_18_LowSpeed";
VAL_ 820 HzrdLampsCtrl 0 "HzrdLampsCtrl_0_No_Request" 1 "HzrdLampsCtrl_1_ON" 2 "HzrdLampsCtrl_2_OFF" 3 "HzrdLampsCtrl_3_Reserved";
VAL_ 1105 ELKSysFltSts 0 "ELKSysFltSts_0_no_error" 1 "ELKSysFltSts_1_performance_degradation" 2 "ELKSysFltSts_2_system_temporary_unavailable" 3 "ELKSysFltSts_3_service_required";
VAL_ 1105 NrwroadFwdSta 0 "NrwroadFwdSta_0_No_request" 1 "NrwroadFwdSta_1_ON" 2 "NrwroadFwdSta_2_OFF" 3 "NrwroadFwdSta_3_Unavailable";
VAL_ 1105 NrwroadsltSta 0 "NrwroadsltSta_0_No_request" 1 "NrwroadsltSta_1_ON" 2 "NrwroadsltSta_2_OFF" 3 "NrwroadsltSta_3_Unavailable";
VAL_ 1105 ELKDspCmd 0 "ELKDspCmd_0_Unavailable" 1 "ELKDspCmd_1_off" 2 "ELKDspCmd_2_on";
VAL_ 1105 MemParkngBtnRcnm 0 "MemParkngBtnRcnm_0_noRecommended" 1 "MemParkngBtnRcnm_1_Recommended" 2 "MemParkngBtnRcnm_2_Reserve1" 3 "MemParkngBtnRcnm_3_Reserve2";
VAL_ 1106 NarrowRoadForwardSts 0 "NarrowRoadForwardSts_0_off" 1 "NarrowRoadForwardSts_1_enable" 2 "NarrowRoadForwardSts_2_Unavailable" 3 "NarrowRoadForwardSts_3_The_conditions_are_not_met" 4 "NarrowRoadForwardSts_4_Rready" 5 "NarrowRoadForwardSts_5_Moving_forward" 6 "NarrowRoadForwardSts_6_Moving_forward_Is_Over" 7 "NarrowRoadForwardSts_7_Interruption";
VAL_ 1106 NarrowRoadBackwardSts 0 "NarrowRoadBackwardSts_0_off" 1 "NarrowRoadBackwardSts_1_enable" 2 "NarrowRoadBackwardSts_2_Unavailable" 3 "NarrowRoadBackwardSts_3_The_conditions_are_not_met" 4 "NarrowRoadBackwardSts_4_Rready" 5 "NarrowRoadBackwardSts_5_Moving_backward" 6 "NarrowRoadBackwardSts_6_Moving_backward_Is_Over" 7 "NarrowRoadBackwardSts_7_Interruption";
VAL_ 1106 TrfcLghtStSp 0 "TrfcLghtStSp_0_off_0x1EqualsTrfcLghtStSp_1_enable_0x2EqualsTrfcLghtStSp_2_Unavailable_0x3EqualsTrfcLghtStSp_3_override_0x4EqualsTrfcLghtStSp_4_Yellow_light_ahead_automatic_deceleration_in_progress_0x5EqualsTrfcLghtStSp_5_Red_light_ahead_automatic_parking_in_progress_0x6EqualsTrfcLghtStSp_6_Red_light_ahead_stopped_0x7EqualsTrfcLghtStSp_7_Green_light_ahead_automatic_go_off_0x8EqualsTrfcLghtStSp_8_Green_light_ahead_automatic_start_successful";
VAL_ 151 AIParkngEPAMdsts 0 "AIParkngEPAMdsw_0_Lockmode" 1 "AIParkngEPAMdsw_0_Simplemode";
VAL_ 151 D2DSwReqResps 0 "D2DSwReqResps_0_unavailable" 1 "D2DSwReqResps_1_off" 2 "D2DSwReqResps_2_on" 3 "D2DSwReqResps_3_reserved";
VAL_ 151 FCTBSysFltSts 0 "FCTBSysFltSts_0_No_Error" 1 "FCTBSysFltSts_1_System_Temporary_Unvailable" 2 "FCTBSysFltSts_2_Service_Required" 3 "FCTBSysFltSts_3_Service_Required";
VAL_ 151 D2DPriETClanSwReqResps 0 "D2DPriETClanSwReqResps_0_unavailable" 1 "D2DPriETClanSwReqResps_1_off" 2 "D2DPriETClanSwReqResps_2_on" 3 "D2DPriETClanSwReqResps_3_reserved";
VAL_ 382 ACCSdslReq 0 "ACCSdslReq_0_No_Request" 1 "ACCSdslReq_1_Request";
VAL_ 382 ACCGoReq 0 "ACCGoReq_0_NoRequest" 1 "ACCGoReq_1_Request";
VAL_ 382 ACCAccReqSts_CH 0 "ACCAccReqSts_CH_0_No_Request" 1 "ACCAccReqSts_CH_1_ACC_Acceleration_Request";
VAL_ 382 APAEPBOPReq 0 "APAEPBOPReq_0_No_Request" 1 "APAEPBOPReq_1_Apply" 2 "APAEPBOPReq_2_Release";
VAL_ 382 ACCSysFltSts 0 "ACCSysFltSts_0_NoError" 1 "ACCSysFltSts_1_PerformanceDegradation" 2 "ACCSysFltSts_2_SystemTemporaryUnvailable" 3 "ACCSysFltSts_3_ServiceRequired" 4 "ACCSysFltSts_4_Reserved" 5 "ACCSysFltSts_5_Reserved" 6 "ACCSysFltSts_6_Reserved" 7 "ACCSysFltSts_7_Reserved";
VAL_ 382 ACCSysSts 0 "ACCSysSts_0_Off" 1 "ACCSysSts_1_StandBy" 2 "ACCSysSts_2_Active" 3 "ACCSysSts_3_Override" 4 "ACCSysSts_4_BrakeOnly" 5 "ACCSysSts_5_StandstillActive" 6 "ACCSysSts_6_StandstillWait" 7 "ACCSysSts_7_Passive";
VAL_ 382 APASCSAcclReqSts 0 "APASCSAcclReqSts_0_NoRequest" 1 "APASCSAcclReqSts_1_DecelerationRequest";
VAL_ 382 APAEPBOPReqV 0 "APAEPBOPReqV_0_Valid" 1 "APAEPBOPReqV_1_Invalid";
VAL_ 382 AutodDrvngSysSCSSdslReqV 0 "AutodDrvngSysSCSSdslReqV_0_Valid" 1 "AutodDrvngSysSCSSdslReqV_1_Invalid";
VAL_ 382 AutodDrvngSysSCSSdslReq 0 "AutodDrvngSysSCSSdslReq_0_NoRequest" 1 "AutodDrvngSysSCSSdslReq_1_request";
VAL_ 382 AutodDrvngSysEmgcBrkReqV 0 "AutodDrvngSysEmgcBrkReqV_0_Valid" 1 "AutodDrvngSysEmgcBrkReqV_1_Invalid";
VAL_ 382 AutodDrvngSysEmgcBrkReq 0 "AutodDrvngSysEmgcBrkReq_0_NoRequest" 1 "AutodDrvngSysEmgcBrkReq_1_EmergencyBrakeRequest";
VAL_ 382 AutodDrvngSysSCSDrvOffReqV 0 "AutodDrvngSysSCSDrvOffReqV_0_Valid" 1 "AutodDrvngSysSCSDrvOffReqV_1_Invalid";
VAL_ 382 AutodDrvngSysSCSDrvOffReq 0 "AutodDrvngSysSCSDrvOffReq_0_NoRequest" 1 "AutodDrvngSysSCSDrvOffReq_1_DriveOffRequest";
VAL_ 382 AutodDrvngSysMdReqV 0 "AutodDrvngSysMdReqV_0_Valid" 1 "AutodDrvngSysMdReqV_1_Invalid";
VAL_ 382 AutodDrvngSysMdReq 0 "AutodDrvngSysMdReq_0_DriverModeRequest" 1 "AutodDrvngSysMdReq_1_AutomatedDriverModeRequest";
VAL_ 382 AutodDrvngSysFlrStsV 0 "AutodDrvngSysFlrStsV_0_Valid" 1 "AutodDrvngSysFlrStsV_1_Invalid";
VAL_ 382 AutodDrvngSysFlrSts 0 "AutodDrvngSysFlrSts_0_NoError" 1 "AutodDrvngSysFlrSts_1_PerformanceDegradation" 2 "AutodDrvngSysFlrSts_2_SystemUnavailable" 3 "AutodDrvngSysFlrSts_3_Reserved" 4 "AutodDrvngSysFlrSts_4_Reserved" 5 "AutodDrvngSysFlrSts_5_Reserved" 6 "AutodDrvngSysFlrSts_6_Reserved" 7 "AutodDrvngSysFlrSts_7_Reserved";
VAL_ 385 NSAReqAVMDis 0 "NSAReqAVMDis_0_NoRequest" 1 "NSAReqAVMDis_1_Request";
VAL_ 385 NSADisFucSts 0 "NSADisFucSts_0_Off" 1 "NSADisFucSts_1_Standby" 2 "NSADisFucSts_2_Active" 3 "NSADisFucSts_3_Fault";
VAL_ 385 NSABacSysSts 0 "NSABacSysSts_0_Off" 1 "NSABacSysSts_1_Standby" 2 "NSABacSysSts_2_BackwardActive" 3 "NSABacSysSts_3_Quit" 4 "NSABacSysSts_4_Error";
VAL_ 385 NSAForSysSts 0 "NSAForSysSts_0_Off" 1 "NSAForSysSts_1_Standby" 2 "NSAForSysSts_2_ForwardActive" 3 "NSAForSysSts_3_Quit" 4 "NSAForSysSts_4_Error" 5 "NSAForSysSts_5_Pause" 6 "NSAForSysSts_6_Complete" 7 "NSAForSysSts_7_Passive";
VAL_ 343 AEBPrflReq 0 "AEBPrflReq_0_False" 1 "AEBPrflReq_1_True";
VAL_ 343 AEBSysSts 0 "AEBSysSts_0_Off" 1 "AEBSysSts_1_Standby" 2 "AEBSysSts_2_Disable" 3 "AEBSysSts_3_Override" 4 "AEBSysSts_4_Active" 5 "AEBSysSts_5_Reserved" 6 "AEBSysSts_6_Reserved" 7 "AEBSysSts_7_Reserved";
VAL_ 343 AEBDclReqSts 0 "AEBDclReqSts_0_NoRequest" 1 "AEBDclReqSts_1_AebDecelerationRequest" 2 "AEBDclReqSts_2_PebDecelerationRequest";
VAL_ 343 AEBBrkJerkLvlReq 0 "AEBBrkJerkLvlReq_0_NoRequest" 1 "AEBBrkJerkLvlReq_1_Level1_low" 2 "AEBBrkJerkLvlReq_2_Level2_middle" 3 "AEBBrkJerkLvlReq_3_Level3_high";
VAL_ 343 AEBHydBrkAstLvlReq 0 "AEBHydBrkAstLvlReq_0_NoRequest" 1 "AEBHydBrkAstLvlReq_1_Level1_low" 2 "AEBHydBrkAstLvlReq_2_Level2_middle" 3 "AEBHydBrkAstLvlReq_3_Level3_high" 4 "AEBHydBrkAstLvlReq_4_Reserved" 5 "AEBHydBrkAstLvlReq_5_Reserved" 6 "AEBHydBrkAstLvlReq_6_Reserved" 7 "AEBHydBrkAstLvlReq_7_Reserved";
VAL_ 343 AEBSysFltSts 0 "AEBSysFltSts_0_NoError" 1 "AEBSysFltSts_1_PerformanceDegradation" 2 "AEBSysFltSts_2_SystemTemporaryUnvailable" 3 "AEBSysFltSts_3_ServiceRequired" 4 "AEBSysFltSts_4_Reserved" 5 "AEBSysFltSts_5_Reserved" 6 "AEBSysFltSts_6_Reserved" 7 "AEBSysFltSts_7_Reserved";
VAL_ 736 FrtMidRObsRng 0 "FrtMidRObsRng_0_No_Obstacle" 1 "FrtMidRObsRng_1_Range_1" 2 "FrtMidRObsRng_2_Range_2" 3 "FrtMidRObsRng_3_Range_3" 4 "FrtMidRObsRng_4_Range_4" 5 "FrtMidRObsRng_5_Range_5" 6 "FrtMidRObsRng_6_Range_6" 7 "FrtMidRObsRng_7_Range_7" 8 "FrtMidRObsRng_8_Range_8" 9 "FrtMidRObsRng_9_Range_9" 10 "FrtMidRObsRng_10_Range_10" 11 "FrtMidRObsRng_11_Range_11" 12 "FrtMidRObsRng_12_Range_12" 13 "FrtMidRObsRng_13_Range_13" 14 "FrtMidRObsRng_14_Range_14" 15 "FrtMidRObsRng_15_Range_15";
VAL_ 736 FrtPDCAudWrnng 0 "FrtPDCAudWrnng_0_NoObstacle" 1 "FrtPDCAudWrnng_1_Range1" 2 "FrtPDCAudWrnng_2_Range2" 3 "FrtPDCAudWrnng_3_Range3" 4 "FrtPDCAudWrnng_4_Range4" 5 "FrtPDCAudWrnng_5_Range5" 6 "FrtPDCAudWrnng_6_Range6" 7 "FrtPDCAudWrnng_7_Range7" 8 "FrtPDCAudWrnng_8_Range8" 9 "FrtPDCAudWrnng_9_Range9" 10 "FrtPDCAudWrnng_10_Range10" 11 "FrtPDCAudWrnng_11_Range11" 12 "FrtPDCAudWrnng_12_Range12" 13 "FrtPDCAudWrnng_13_Range13" 14 "FrtPDCAudWrnng_14_Range14" 15 "FrtPDCAudWrnng_15_Range15";
VAL_ 736 RrMidLObsRng 0 "RrMidLObsRng_0_No_Obstacle" 1 "RrMidLObsRng_1_Range_1" 2 "RrMidLObsRng_2_Range_2" 3 "RrMidLObsRng_3_Range_3" 4 "RrMidLObsRng_4_Range_4" 5 "RrMidLObsRng_5_Range_5" 6 "RrMidLObsRng_6_Range_6" 7 "RrMidLObsRng_7_Range_7" 8 "RrMidLObsRng_8_Range_8" 9 "RrMidLObsRng_9_Range_9" 10 "RrMidLObsRng_10_Range_10" 11 "RrMidLObsRng_11_Range_11" 12 "RrMidLObsRng_12_Range_12" 13 "RrMidLObsRng_13_Range_13" 14 "RrMidLObsRng_14_Range_14" 15 "RrMidLObsRng_15_Range_15";
VAL_ 736 RLObsRng 0 "RLObsRng_0_No_Obstacle" 1 "RLObsRng_1_Range_1" 2 "RLObsRng_2_Range_2" 3 "RLObsRng_3_Range_3" 4 "RLObsRng_4_Range_4" 5 "RLObsRng_5_Range_5" 6 "RLObsRng_6_Range_6" 7 "RLObsRng_7_Range_7" 8 "RLObsRng_8_Range_8" 9 "RLObsRng_9_Range_9" 10 "RLObsRng_10_Range_10" 11 "RLObsRng_11_Range_11" 12 "RLObsRng_12_Range_12" 13 "RLObsRng_13_Range_13" 14 "RLObsRng_14_Range_14" 15 "RLObsRng_15_Range_15";
VAL_ 736 RrMidRObsRng 0 "RrMidRObsRng_0_No_Obstacle" 1 "RrMidRObsRng_1_Range_1" 2 "RrMidRObsRng_2_Range_2" 3 "RrMidRObsRng_3_Range_3" 4 "RrMidRObsRng_4_Range_4" 5 "RrMidRObsRng_5_Range_5" 6 "RrMidRObsRng_6_Range_6" 7 "RrMidRObsRng_7_Range_7" 8 "RrMidRObsRng_8_Range_8" 9 "RrMidRObsRng_9_Range_9" 10 "RrMidRObsRng_10_Range_10" 11 "RrMidRObsRng_11_Range_11" 12 "RrMidRObsRng_12_Range_12" 13 "RrMidRObsRng_13_Range_13" 14 "RrMidRObsRng_14_Range_14" 15 "RrMidRObsRng_15_Range_15";
VAL_ 736 PDCSysSts 0 "PDCSysSts_0_System_OK" 1 "PDCSysSts_1_System_initialization_sucessful" 2 "PDCSysSts_2_System_Failed" 3 "PDCSysSts_3_System_Disabled" 4 "PDCSysSts_4_Front_PDC_Disabled" 5 "PDCSysSts_5_Front_PDC_Failed" 6 "PDCSysSts_6_Rear_PDC_Failed" 7 "PDCSysSts_7_Rear_PDC_Disabled";
VAL_ 736 FLSideObsRng 0 "FLSideObsRng_0_No_Obstacle" 1 "FLSideObsRng_1_Range_1" 2 "FLSideObsRng_2_Range_2" 3 "FLSideObsRng_3_Range_3" 4 "FLSideObsRng_4_Range_4" 5 "FLSideObsRng_5_Range_5" 6 "FLSideObsRng_6_Range_6" 7 "FLSideObsRng_7_Range_7" 8 "FLSideObsRng_8_Range_8" 9 "FLSideObsRng_9_Range_9" 10 "FLSideObsRng_10_Range_10" 11 "FLSideObsRng_11_Range_11" 12 "FLSideObsRng_12_Range_12" 13 "FLSideObsRng_13_Range_13" 14 "FLSideObsRng_14_Range_14" 15 "FLSideObsRng_15_Range_15";
VAL_ 736 RrPDCAudWrnng 0 "RrPDCAudWrnng_0_No_Obstacle" 1 "RrPDCAudWrnng_1_Range_1" 2 "RrPDCAudWrnng_2_Range_2" 3 "RrPDCAudWrnng_3_Range_3" 4 "RrPDCAudWrnng_4_Range_4" 5 "RrPDCAudWrnng_5_Range_5" 6 "RrPDCAudWrnng_6_Range_6" 7 "RrPDCAudWrnng_7_Range_7" 8 "RrPDCAudWrnng_8_Range_8" 9 "RrPDCAudWrnng_9_Range_9" 10 "RrPDCAudWrnng_10_Range_10" 11 "RrPDCAudWrnng_11_Range_11" 12 "RrPDCAudWrnng_12_Range_12" 13 "RrPDCAudWrnng_13_Range_13" 14 "RrPDCAudWrnng_14_Range_14" 15 "RrPDCAudWrnng_15_Range_15";
VAL_ 736 RLSideObsRng 0 "FLSideObsRng_0_No_Obstacle" 1 "FLSideObsRng_1_Range_1" 2 "FLSideObsRng_2_Range_2" 3 "FLSideObsRng_3_Range_3" 4 "FLSideObsRng_4_Range_4" 5 "FLSideObsRng_5_Range_5" 6 "FLSideObsRng_6_Range_6" 7 "FLSideObsRng_7_Range_7" 8 "FLSideObsRng_8_Range_8" 9 "FLSideObsRng_9_Range_9" 10 "FLSideObsRng_10_Range_10" 11 "FLSideObsRng_11_Range_11" 12 "FLSideObsRng_12_Range_12" 13 "FLSideObsRng_13_Range_13" 14 "FLSideObsRng_14_Range_14" 15 "FLSideObsRng_15_Range_15";
VAL_ 736 FRSideObsRng 0 "FLSideObsRng_0_No_Obstacle" 1 "FLSideObsRng_1_Range_1" 2 "FLSideObsRng_2_Range_2" 3 "FLSideObsRng_3_Range_3" 4 "FLSideObsRng_4_Range_4" 5 "FLSideObsRng_5_Range_5" 6 "FLSideObsRng_6_Range_6" 7 "FLSideObsRng_7_Range_7" 8 "FLSideObsRng_8_Range_8" 9 "FLSideObsRng_9_Range_9" 10 "FLSideObsRng_10_Range_10" 11 "FLSideObsRng_11_Range_11" 12 "FLSideObsRng_12_Range_12" 13 "FLSideObsRng_13_Range_13" 14 "FLSideObsRng_14_Range_14" 15 "FLSideObsRng_15_Range_15";
VAL_ 736 RRSideObsRng 0 "FLSideObsRng_0_No_Obstacle" 1 "FLSideObsRng_1_Range_1" 2 "FLSideObsRng_2_Range_2" 3 "FLSideObsRng_3_Range_3" 4 "FLSideObsRng_4_Range_4" 5 "FLSideObsRng_5_Range_5" 6 "FLSideObsRng_6_Range_6" 7 "FLSideObsRng_7_Range_7" 8 "FLSideObsRng_8_Range_8" 9 "FLSideObsRng_9_Range_9" 10 "FLSideObsRng_10_Range_10" 11 "FLSideObsRng_11_Range_11" 12 "FLSideObsRng_12_Range_12" 13 "FLSideObsRng_13_Range_13" 14 "FLSideObsRng_14_Range_14" 15 "FLSideObsRng_15_Range_15";
VAL_ 736 FLObsRng 0 "FLObsRng_0_No_Obstacle" 1 "FLObsRng_1_Range_1" 2 "FLObsRng_2_Range_2" 3 "FLObsRng_3_Range_3" 4 "FLObsRng_4_Range_4" 5 "FLObsRng_5_Range_5" 6 "FLObsRng_6_Range_6" 7 "FLObsRng_7_Range_7" 8 "FLObsRng_8_Range_8" 9 "FLObsRng_9_Range_9" 10 "FLObsRng_10_Range_10" 11 "FLObsRng_11_Range_11" 12 "FLObsRng_12_Range_12" 13 "FLObsRng_13_Range_13" 14 "FLObsRng_14_Range_14" 15 "FLObsRng_15_Range_15";
VAL_ 736 RRObsRng 0 "RRObsRng_0_No_Obstacle" 1 "RRObsRng_1_Range_1" 2 "RRObsRng_2_Range_2" 3 "RRObsRng_3_Range_3" 4 "RRObsRng_4_Range_4" 5 "RRObsRng_5_Range_5" 6 "RRObsRng_6_Range_6" 7 "RRObsRng_7_Range_7" 8 "RRObsRng_8_Range_8" 9 "RRObsRng_9_Range_9" 10 "RRObsRng_10_Range_10" 11 "RRObsRng_11_Range_11" 12 "RRObsRng_12_Range_12" 13 "RRObsRng_13_Range_13" 14 "RRObsRng_14_Range_14" 15 "RRObsRng_15_Range_15";
VAL_ 736 FRObsRng 0 "FRObsRng_0_No_Obstacle" 1 "FRObsRng_1_Range_1" 2 "FRObsRng_2_Range_2" 3 "FRObsRng_3_Range_3" 4 "FRObsRng_4_Range_4" 5 "FRObsRng_5_Range_5" 6 "FRObsRng_6_Range_6" 7 "FRObsRng_7_Range_7" 8 "FRObsRng_8_Range_8" 9 "FRObsRng_9_Range_9" 10 "FRObsRng_10_Range_10" 11 "FRObsRng_11_Range_11" 12 "FRObsRng_12_Range_12" 13 "FRObsRng_13_Range_13" 14 "FRObsRng_14_Range_14" 15 "FRObsRng_15_Range_15";
VAL_ 736 LADSAFnInd_Tester 0 "LADSAFnInd_0_IDLE" 1 "LADSAFnInd_1_RADS" 2 "LADSAFnInd_2_ESSSwap_Park" 3 "LADSAFnInd_3_NPA" 4 "LADSAFnInd_4_AVP" 5 "LADSAFnInd_5_Remember_Build_Map" 6 "LADSAFnInd_6_Remember_Summon" 7 "LADSAFnInd_7_Remember_ParkIn" 8 "LADSAFnInd_8_RemoteOnekeyParkIn_Super" 9 "LADSAFnInd_9_ParkIn_super" 10 "LADSAFnInd_10_ParkIn" 11 "LADSAFnInd_11_ParkOut" 12 "LADSAFnInd_12_NRCD" 13 "LADSAFnInd_13_RemoteOnekeyParkIn" 14 "LADSAFnInd_14_RemoteOnekeyParkOut" 15 "LADSAFnInd_15_NCP";
VAL_ 736 FrtMidLObsRng 0 "FrtMidLObsRng_0_No_Obstacle" 1 "FrtMidLObsRng_1_Range_1" 2 "FrtMidLObsRng_2_Range_2" 3 "FrtMidLObsRng_3_Range_3" 4 "FrtMidLObsRng_4_Range_4" 5 "FrtMidLObsRng_5_Range_5" 6 "FrtMidLObsRng_6_Range_6" 7 "FrtMidLObsRng_7_Range_7" 8 "FrtMidLObsRng_8_Range_8" 9 "FrtMidLObsRng_9_Range_9" 10 "FrtMidLObsRng_10_Range_10" 11 "FrtMidLObsRng_11_Range_11" 12 "FrtMidLObsRng_12_Range_12" 13 "FrtMidLObsRng_13_Range_13" 14 "FrtMidLObsRng_14_Range_14" 15 "FrtMidLObsRng_15_Range_15";
VAL_ 736 FRSObsRng 0 "FRSObsRng1_0_NoObstacle" 1 "FRSObsRng1_1_Range1" 2 "FRSObsRng1_2_Range2" 3 "FRSObsRng1_3_Range3" 4 "FRSObsRng1_4_Range4" 5 "FRSObsRng1_5_Range5" 6 "FRSObsRng1_6_Range6" 7 "FRSObsRng1_7_Range7" 8 "FRSObsRng1_8_Range8" 9 "FRSObsRng1_9_Range9" 10 "FRSObsRng1_10_Range10" 11 "FRSObsRng1_11_Range11" 12 "FRSObsRng1_12_Range12" 13 "FRSObsRng1_13_Range13" 14 "FRSObsRng1_14_Range14" 15 "FRSObsRng1_15_Range15";
VAL_ 736 FLSObsRng 0 "FLSObsRng1_0_NoObstacle" 1 "FLSObsRng1_1_Range1" 2 "FLSObsRng1_2_Range2" 3 "FLSObsRng1_3_Range3" 4 "FLSObsRng1_4_Range4" 5 "FLSObsRng1_5_Range5" 6 "FLSObsRng1_6_Range6" 7 "FLSObsRng1_7_Range7" 8 "FLSObsRng1_8_Range8" 9 "FLSObsRng1_9_Range9" 10 "FLSObsRng1_10_Range10" 11 "FLSObsRng1_11_Range11" 12 "FLSObsRng1_12_Range12" 13 "FLSObsRng1_13_Range13" 14 "FLSObsRng1_14_Range14" 15 "FLSObsRng1_15_Range15";
VAL_ 736 RRSObsRng 0 "RRSObsRng1_0_NoObstacle" 1 "RRSObsRng1_1_Range1" 2 "RRSObsRng1_2_Range2" 3 "RRSObsRng1_3_Range3" 4 "RRSObsRng1_4_Range4" 5 "RRSObsRng1_5_Range5" 6 "RRSObsRng1_6_Range6" 7 "RRSObsRng1_7_Range7" 8 "RRSObsRng1_8_Range8" 9 "RRSObsRng1_9_Range9" 10 "RRSObsRng1_10_Range10" 11 "RRSObsRng1_11_Range11" 12 "RRSObsRng1_12_Range12" 13 "RRSObsRng1_13_Range13" 14 "RRSObsRng1_14_Range14" 15 "RRSObsRng1_15_Range15";
VAL_ 736 RLSObsRng 0 "RLSObsRng1_0_NoObstacle" 1 "RLSObsRng1_1_Range1" 2 "RLSObsRng1_2_Range2" 3 "RLSObsRng1_3_Range3" 4 "RLSObsRng1_4_Range4" 5 "RLSObsRng1_5_Range5" 6 "RLSObsRng1_6_Range6" 7 "RLSObsRng1_7_Range7" 8 "RLSObsRng1_8_Range8" 9 "RLSObsRng1_9_Range9" 10 "RLSObsRng1_10_Range10" 11 "RLSObsRng1_11_Range11" 12 "RLSObsRng1_12_Range12" 13 "RLSObsRng1_13_Range13" 14 "RLSObsRng1_14_Range14" 15 "RLSObsRng1_15_Range15";
VAL_ 893 MemPkngSwResp 0 "MemPkngSwResp_0_Default" 1 "MemPkngSwResp_1_ON" 2 "MemPkngSwResp_2_OFF";
VAL_ 893 MemPkngSlntPtrlEnbSwResp 0 "MemPkngSlntPtrlEnbSwResp_0_Default" 1 "MemPkngSlntPtrlEnbSwResp_1_ON" 2 "MemPkngSlntPtrlEnbSwResp_2_OFF" 3 "MemPkngSlntPtrlEnbSwResp_3_reserved";
VAL_ 893 PEBSysFltSts 0 "PEBSysFltSts_0_No_error" 1 "PEBSysFltSts_1_Performance_degradation" 2 "PEBSysFltSts_2_System_temporary_unavailable" 3 "PEBSysFltSts_3_Service_required";
VAL_ 314 D2DSysSts 0 "D2DSysSts_0_Off" 1 "D2DSysSts_1_Passive" 2 "D2DSysSts_2_Standby" 3 "D2DSysSts_3_active_LPNP" 4 "D2DSysSts_4_active_NP" 5 "D2DSysSts_5_Override" 6 "D2DSysSts_6_TOR" 7 "D2DSysSts_7_Prohibit" 8 "D2DSysSts_8_Fault" 9 "D2DSysSts_9_SafeStop" 10 "D2DSysSts_10_reserved" 11 "D2DSysSts_11_reserved";
VAL_ 314 ACCObjDet 0 "ACCObjDet_0_False" 1 "ACCObjDet_1_True";
VAL_ 360 APAShifterPosReqd 0 "APAShifterPosReqd_0_ScuInitialization" 1 "APAShifterPosReqd_1_S" 2 "APAShifterPosReqd_2_W" 3 "APAShifterPosReqd_3_M" 5 "APAShifterPosReqd_5_D" 6 "APAShifterPosReqd_6_N" 7 "APAShifterPosReqd_7_R" 8 "APAShifterPosReqd_8_P" 9 "APAShifterPosReqd_9_Reserved" 10 "APAShifterPosReqd_10_Error";
VAL_ 360 APASCUReqSts 0 "APASCUReqSts_0_No_Request" 1 "APASCUReqSts_1_Request" 2 "APASCUReqSts_2_Active" 3 "APASCUReqSts_3_Reversed";
VAL_ 360 APACmdEPSSts 0 "APACmdEPSSts_0_No_request" 1 "APACmdEPSSts_1_Control_EPS_request" 2 "APACmdEPSSts_2_EPS_control";
VAL_ 360 APAShifterPosReqdV 0 "APAShifterPosReqdV_0_Valid" 1 "APAShifterPosReqdV_1_Invalid";
VAL_ 360 APASCUReqStsV 0 "APASCUReqStsV_0_Valid" 1 "APASCUReqStsV_1_Invalid";
VAL_ 360 APAF 0 "APAF_0_Normal" 1 "APAF_1_APA_failure";
VAL_ 474 LDWLKARVsulznReq 0 "LDWLKARVsulznReq_0_no_display" 1 "LDWLKARVsulznReq_1_line_tracking" 2 "LDWLKARVsulznReq_2_intervention" 3 "LDWLKARVsulznReq_3_warning" 4 "LDWLKARVsulznReq_4_intervention_and_warning" 5 "LDWLKARVsulznReq_5_Reserved" 6 "LDWLKARVsulznReq_6_Reserved" 7 "LDWLKARVsulznReq_7_Reserved";
VAL_ 474 LDWLKAVbnLvlReq 0 "LDWLKAVbnLvlReq_0_NoRequest" 1 "LDWLKAVbnLvlReq_1_Level1" 2 "LDWLKAVbnLvlReq_2_Level2" 3 "LDWLKAVbnLvlReq_3_Level3";
VAL_ 474 LDWSysFltSts 0 "LDWSysFltSts_0_no_error" 1 "LDWSysFltSts_1_performance_degradation" 2 "LDWSysFltSts_2_system_temporary_unavailable" 3 "LDWSysFltSts_3_service_required" 4 "LDWSysFltSts_4_Reserved" 5 "LDWSysFltSts_5_Reserved" 6 "LDWSysFltSts_6_Reserved" 7 "LDWSysFltSts_7_Reserved";
VAL_ 474 LDWSysSts 0 "LDWSysSts_0_Off" 1 "LDWSysSts_1_Stand_by" 2 "LDWSysSts_2_Active" 3 "LDWSysSts_3_Override" 4 "LDWSysSts_4_service_required" 5 "LDWSysSts_5_system_temporary_unavailable" 6 "LDWSysSts_6_Active_no_warning" 7 "LDWSysSts_7_reserved";
VAL_ 474 LDWLKALVsulznReq 0 "LDWLKALVsulznReq_0_no_display" 1 "LDWLKALVsulznReq_1_line_tracking" 2 "LDWLKALVsulznReq_2_intervention" 3 "LDWLKALVsulznReq_3_warning" 4 "LDWLKALVsulznReq_4_intervention_and_warning" 5 "LDWLKALVsulznReq_5_Reserved" 6 "LDWLKALVsulznReq_6_Reserved" 7 "LDWLKALVsulznReq_7_Reserved";
VAL_ 351 APAVCUReqSts 0 "APAVCUReqSts_0_NoRequest" 1 "APAVCUReqSts_1_RequestSpeedControl" 2 "APAVCUReqSts_2_RequestTorqueControl" 3 "APAVCUReqSts_3_Active";
VAL_ 351 APARevrDrgReq 0 "APARevrDrgReq_0_NoRequest" 1 "APARevrDrgReq_1_RequestReverseDrag";
VAL_ 424 AutodDrvngSysStsV 0 "AutodDrvngSysStsV_0_Valid" 1 "AutodDrvngSysStsV_1_Invalid";
VAL_ 424 APASts 0 "APASts_0_Disable" 1 "APASts_1_Standby" 2 "APASts_2_Semi_apaActive" 3 "APASts_3_Fully_apaActive" 4 "APASts_4_Failed";
VAL_ 424 AutodDrvngSysSts 0 "AutodDrvngSysSts_CH_0_Off" 1 "AutodDrvngSysSts_CH_1_APA_Disable" 2 "AutodDrvngSysSts_CH_2_APA_Standby" 3 "AutodDrvngSysSts_CH_3_Semi_APA_Active" 4 "AutodDrvngSysSts_CH_4_Fully_APA_Active" 5 "AutodDrvngSysSts_CH_5_APA_Failed" 6 "AutodDrvngSysSts_CH_6_Automated_driving_system_Disable" 7 "AutodDrvngSysSts_CH_7_Automated_driving_system_Standby" 8 "AutodDrvngSysSts_CH_8_Automated_driving_system_Failed" 9 "AutodDrvngSysSts_CH_9_Automated_driving_system_active";
VAL_ 50 IPDTripCntResetResp 0 "IPDTripCntResetResp_0_Failed" 1 "IPDTripCntResetResp_1_Success";
VAL_ 178 IPDAlgFlag 0 "IPDAlgFlag_0_NationalAlgorism" 1 "IPDAlgFlag_1_InternationalAlgorism";
VAL_ 178 IPDFailedReason 0 "IPDFailedReason_0_Default" 1 "IPDFailedReason_1_VerifyFailed" 2 "IPDFailedReason_2_WrongFV" 3 "IPDFailedReason_3_WrongBuildMAC";
VAL_ 178 IPDTripNvmTag 0 "IPDTripNvmTag_0_Success" 1 "IPDTripNvmTag_1_Failed";
VAL_ 178 IPDKeyStatus 0 "IPDKeyStatus_0_WrittenAndReadSuccess" 1 "IPDKeyStatus_1_NotWrittenOrReadFailed";
VAL_ 81 TJAICASysFltSts 0 "TJAICASysFltSts_0_noerror" 1 "TJAICASysFltSts_1_performancedegradation" 2 "TJAICASysFltSts_2_systemtemporaryunavailable" 3 "TJAICASysFltSts_3_servicerequired" 4 "TJAICASysFltSts_4_Reserved" 5 "TJAICASysFltSts_5_Reserved" 6 "TJAICASysFltSts_6_Reserved" 7 "TJAICASysFltSts_7_Reserved";
VAL_ 81 ACCToqReqSts 0 "ACCToqReqSts_0__No_request" 1 "ACCToqReqSts_1__Torque_request_request" 2 "ACCToqReqSts_2_Reserved1" 3 "ACCToqReqSts_3_Reserved2";
VAL_ 81 LKASysFltSts 0 "LKASysFltSts_0_noerror" 1 "LKASysFltSts_1_performancedegradation" 2 "LKASysFltSts_2_systemtemporaryunavailable" 3 "LKASysFltSts_3_servicerequired";
VAL_ 81 TJAICASysSts 0 "TJAICASysSts_0_Off" 1 "TJAICASysSts_1_Standby" 2 "TJAICASysSts_2_Active" 3 "TJAICASysSts_3_Override" 4 "TJAICASysSts_4_Passive" 5 "TJAICASysSts_5_Degradation" 6 "TJAICASysSts_6_SafeStop" 7 "TJAICASysSts_7_Prohibition";
VAL_ 81 LKASysSts 0 "LKASysSts_0_Off" 1 "LKASysSts_1_Standby" 2 "LKASysSts_2_Active" 3 "LKASysSts_3_Override" 4 "LKASysSts_4_Active_no_warning";
VAL_ 1282 MnvrngPntTypNav 0 "MnvrngPntTypNav_0_TurnInvalid" 1 "MnvrngPntTypNav_1_TurnFront" 2 "MnvrngPntTypNav_2_TurnLeft" 3 "MnvrngPntTypNav_3_TurnRight" 4 "MnvrngPntTypNav_4_KeepLeft" 5 "MnvrngPntTypNav_5_KeepRight" 6 "MnvrngPntTypNav_6_TurnLeftFront" 7 "MnvrngPntTypNav_7_TurnRightFront" 8 "MnvrngPntTypNav_8_TurnLeftBack" 9 "MnvrngPntTypNav_9_TurnRightBack" 10 "MnvrngPntTypNav_10_TurnLeftUturn" 11 "MnvrngPntTypNav_11_TurnRightUturn" 12 "MnvrngPntTypNav_12_TurnThreebranchLeft" 13 "MnvrngPntTypNav_13_TurnThreebranchCenter" 14 "MnvrngPntTypNav_14_TurnThreebranchRight" 15 "MnvrngPntTypNav_15_TurnExitbranchMainLeft" 16 "MnvrngPntTypNav_16_TurnExitbranchMainRight" 17 "MnvrngPntTypNav_17_TurnExitbranchRampLeft" 18 "MnvrngPntTypNav_18_TurnExitbranchRampRight" 19 "MnvrngPntTypNav_19_GoStraightLeft" 20 "MnvrngPntTypNav_20_GoStraightRight" 21 "MnvrngPntTypNav_21_TurnRing" 22 "MnvrngPntTypNav_22_TurnRingOut" 23 "MnvrngPntTypNav_23_TurnRingOutAnticlockwise135" 24 "MnvrngPntTypNav_24_TurnRingOutAnticlockwise90" 25 "MnvrngPntTypNav_25_TurnRingOutAnticlockwise45" 26 "MnvrngPntTypNav_26_TurnRingOutAnticlockwise0" 27 "MnvrngPntTypNav_27_TurnRingOutAnticlockwise225" 28 "MnvrngPntTypNav_28_TurnRingOutAnticlockwise270" 29 "MnvrngPntTypNav_29_TurnRingOutAnticlockwise135" 30 "MnvrngPntTypNav_30_TurnRingOutAnticlockwise360" 31 "MnvrngPntTypNav_31_TurnRingOutClockwise225" 32 "MnvrngPntTypNav_32_TurnRingOutClockwise270" 33 "MnvrngPntTypNav_33_TurnRingOutClockwise315" 34 "MnvrngPntTypNav_34_TurnRingOutClockwise360" 35 "MnvrngPntTypNav_35_TurnRingOutClockwise45" 36 "MnvrngPntTypNav_36_TurnRingOutClockwise90" 37 "MnvrngPntTypNav_37_TurnRingOutClockwise135" 38 "MnvrngPntTypNav_38_TurnRingOutClockwise180" 39 "MnvrngPntTypNav_39_DirectRouteDrive" 40 "MnvrngPntTypNav_40_TollStation" 41 "MnvrngPntTypNav_41_Ferry" 42 "MnvrngPntTypNav_42_TunnelEntrance" 43 "MnvrngPntTypNav_43_BridgeEntrance" 44 "MnvrngPntTypNav_44_StartingPoint" 45 "MnvrngPntTypNav_45_PassedPoint1" 46 "MnvrngPntTypNav_46_PassedPoint2" 47 "MnvrngPntTypNav_47_PassedPoint3" 48 "MnvrngPntTypNav_48_PassedPoint4" 49 "MnvrngPntTypNav_49_PassedPoint5" 50 "MnvrngPntTypNav_50_destination";
VAL_ 1282 NavSts 0 "NavSts_0_Cruise" 1 "NavSts_1_navigation" 2 "NavSts_2_invalid";
VAL_ 66 DspMeasmtSys 0 "DspMeasSys_0_kph" 1 "DspMeasSys_1_mph";
VAL_ 66 PDCSwReq 0 "PDCSwReq_0_No_request" 1 "PDCSwReq_1_Short_press" 2 "PDCSwReq_2_Long_press" 3 "PDCSwReq_3_Reserved";
VAL_ 66 PwrMdExtrCtrlAvlbl 0 "PwrMdExtrCtrlAvlbl_0_NotAvailable" 1 "PwrMdExtrCtrlAvlbl_1_Available";
VAL_ 66 MdOfPwrMd 0 "MdOfPwrMd_0_NormalMode" 1 "MdOfPwrMd_1_AutomatedDrivingMode";
VAL_ 66 ClstrDspdVehSpd 255 "ClstrDspdVehSpd_255_Speed_Signal_Missing_Error_of_SCS";
VAL_ 66 FRSeatVentCtrlSts 0 "FRSeatVentCtrlSts_0_Inactive" 1 "FRSeatVentCtrlSts_1_Local_control" 2 "FRSeatVentCtrlSts_2__1" 3 "FRSeatVentCtrlSts_3__2" 4 "FRSeatVentCtrlSts_4_Remote_control";
VAL_ 66 FLSeatVentCtrlSts 0 "FLSeatVentCtrlSts_0_Inactive" 1 "FLSeatVentCtrlSts_1_Local_control" 2 "FLSeatVentCtrlSts_2__1" 3 "FLSeatVentCtrlSts_3__2" 4 "FLSeatVentCtrlSts_4_Remote_control";
VAL_ 66 FRSeatHeatCtrlSts 0 "FRSeatHeatCtrlSts_0_Inactive" 1 "FRSeatHeatCtrlSts_1_Local_control" 2 "FRSeatHeatCtrlSts_2__1" 3 "FRSeatHeatCtrlSts_3__2" 4 "FRSeatHeatCtrlSts_4_Remote_control";
VAL_ 66 FLSeatHeatCtrlSts 0 "FLSeatHeatCtrlSts_0_Inactive" 1 "FLSeatHeatCtrlSts_1_Local_control" 2 "FLSeatHeatCtrlSts_2__1" 3 "FLSeatHeatCtrlSts_3__2" 4 "FLSeatHeatCtrlSts_4_Remote_control";
VAL_ 871 AVMSt 0 "AVMSt_0_NoDisplay" 1 "AVMSt_1_Display" 2 "AVMSt_2_DriverCloseAVM" 3 "AVMSt_3_Fault";
VAL_ 871 RstrFctryDeftsReq 0 "RstrFctryDeftsReq_0_False" 1 "RstrFctryDeftsReq_1_True";
VAL_ 871 AudiopilotMICSts 0 "AudiopilotMICSts_0_Ture" 1 "AudiopilotMICSts_1_Fault";
VAL_ 871 ZXDSkndReq 0 "ZXDSkndReq_0_false" 1 "ZXDSkndReq_1_ture";
VAL_ 871 DCDCVolStptBkup 254 "DCDCVolStptBkup_254_Init" 255 "DCDCVolStptBkup_255_Invalid";
VAL_ 906 NavCrntRoadTyp 0 "NavCrntRoadTyp_0_Unknown" 1 "NavCrntRoadTyp_1_Highway" 2 "NavCrntRoadTyp_2_inter_urban_roads" 3 "NavCrntRoadTyp_3_City_roads" 4 "NavCrntRoadTyp_4_Ramp" 5 "NavCrntRoadTyp_5_National_road" 6 "NavCrntRoadTyp_6_Provincial_road" 7 "NavCrntRoadTyp_7_County_road" 8 "NavCrntRoadTyp_8_Village_road" 9 "NavCrntRoadTyp_9_City_express_way" 10 "NavCrntRoadTyp_10_Major_urban_road" 11 "NavCrntRoadTyp_11_Secondary_urban_road" 12 "NavCrntRoadTyp_12_Normal_urban_road" 13 "NavCrntRoadTyp_13_Non_Navigation_Road" 14 "NavCrntRoadTyp_14_Reserve";
VAL_ 906 NavSpdLmtValUnit 0 "NavSpdLmtValUnit_0_Unknown" 1 "NavSpdLmtValUnit_1_MPH" 2 "NavSpdLmtValUnit_2_KMH" 3 "NavSpdLmtValUnit_3_Reserved";
VAL_ 906 NavNewIconDist 0 "NavNewIconDist_0_no_newIcon_ahead" 21 "NavNewIconDist_21_over_2km";
VAL_ 906 NavSpdLmtValSts 0 "NavSpdLmtValSts_0_Fault" 1 "NavSpdLmtValSts_1_Inactive" 2 "NavSpdLmtValSts_2_Active" 3 "NavSpdLmtValSts_3_reserved";
VAL_ 906 NavDistFromFrtEleccEye 0 "NavDistFromFrtEleccEye_0_no_SLC_ahead" 61 "NavDistFromFrtEleccEye_61_over_6km";
VAL_ 906 NavItvalSpdDetnDistRetDist 0 "NavItvalSpdDetnDistRetDist_0_not_in_ISD" 251 "NavItvalSpdDetnDistRetDist_251_over_70km";
VAL_ 906 NavSpdLmtTyp 0 "NavSpdLmtTyp_0_Not_specific" 1 "NavSpdLmtTyp_1_Camera_detection" 2 "NavSpdLmtTyp_2_Interval_speed_detection";
VAL_ 1104 NrwroadFwdCtlReq 0 "NrwroadFwdCtlReq_0_NoRequest" 1 "NrwroadFwdCtlReq_1_Entry" 2 "NrwroadFwdCtlReq_2_Start" 3 "NrwroadFwdCtlReq_3_Pause" 4 "NrwroadFwdCtlReq_4_Continue" 5 "NrwroadFwdCtlReq_5_Exit" 6 "NrwroadFwdCtlReq_6_Reserved6" 7 "NrwroadFwdCtlReq_7_Reserved7" 8 "NrwroadFwdCtlReq_8_Reserved8" 9 "NrwroadFwdCtlReq_9_Reserved9" 10 "NrwroadFwdCtlReq_10_Reserved10" 11 "NrwroadFwdCtlReq_11_Reserved11" 12 "NrwroadFwdCtlReq_12_Reserved12" 13 "NrwroadFwdCtlReq_13_Reserved13" 14 "NrwroadFwdCtlReq_14_Reserved14" 15 "NrwroadFwdCtlReq_15_Reserved15";
VAL_ 1104 AIParkngSpdsw 0 "AIParkngSpdsw_0_no_request" 1 "AIParkngSpdsw_1_Low_speed" 2 "AIParkngSpdsw_2_Normal_speed" 3 "AIParkngSpdsw_3_High_speed";
VAL_ 1104 NrwroadsltReq 0 "NrwroadsltReq_0_No_request" 1 "NrwroadsltReq_1_ON" 2 "NrwroadsltReq_2_OFF" 3 "NrwroadsltReq_3_Unavailable";
VAL_ 1104 NrwroadFwdReq 0 "NrwroadFwdReq_0_No_request" 1 "NrwroadFwdReq_1_ON" 2 "NrwroadFwdReq_2_OFF" 3 "NrwroadFwdReq_3_Unavailable";
VAL_ 1104 MemPkngSwReq 0 "MemPkngSwReq_0_NoRequest" 1 "MemPkngSwReq_1_ON" 2 "MemPkngSwReq_2_OFF";
VAL_ 1104 MemPkngSlntPtrlEnbSwReq 0 "MemPkngSlntPtrlEnbSwReq_0_no_request" 1 "MemPkngSlntPtrlEnbSwReq_1_ON" 2 "MemPkngSlntPtrlEnbSwReq_2_OFF" 3 "MemPkngSlntPtrlEnbSwReq_3_reserved";
VAL_ 832 FCWSnstvtLvlReq 0 "FCWSnstvtLvlReq_0_NoRequest" 1 "FCWSnstvtLvlReq_1_level1_low" 2 "FCWSnstvtLvlReq_2_level2_middle" 3 "FCWSnstvtLvlReq_3_level3_high" 4 "FCWSnstvtLvlReq_4_reserved" 5 "FCWSnstvtLvlReq_5_reserved" 6 "FCWSnstvtLvlReq_6_reserved" 7 "FCWSnstvtLvlReq_7_reserved";
VAL_ 832 ELKSwReq 0 "ELKSwReq_0_no_request" 1 "ELKSwReq_1_off" 2 "ELKSwReq_2_on" 3 "ELKSwReq_3_reserved";
VAL_ 832 LDWAdoWrnngReq 0 "LDWAdoWrnngReq_0_no_request" 1 "LDWAdoWrnngReq_1_off" 2 "LDWAdoWrnngReq_2_on";
VAL_ 832 FCWSwReq 0 "FCWSwReq_0_NoRequest" 1 "FCWSwReq_1_off" 2 "FCWSwReq_2_on" 3 "FCWSwReq_3_reserved";
VAL_ 832 TrfcLghtFuctionSwReq 0 "TrfcLghtFuctionSwReq_0_TrfcLghtFnSwReq_0_NoRequest" 1 "TrfcLghtFuctionSwReq_1_TrfcLghtFnSwReq_1_OFF" 2 "TrfcLghtFuctionSwReq_2_TrfcLghtFnSwReq_2_Warning" 3 "TrfcLghtFuctionSwReq_3_TrfcLghtFnSwReq_3_Contorl";
VAL_ 832 DOWSelReq 0 "DOWSelReq_0_no_request" 1 "DOWSelReq_1_driver_switch_Off_request" 2 "DOWSelReq_2_driver_switch_on_request" 3 "DOWSelReq_3_reserve";
VAL_ 832 BSDSelReq 0 "BSDSelReq_0_no_request" 1 "BSDSelReq_1_driver_switch_Off_request" 2 "BSDSelReq_2_driver_switch_on_request" 3 "BSDSelReq_3_reserve";
VAL_ 832 AEBSwReq 0 "AEBSwReq_0_NoRequest" 1 "AEBSwReq_1_off" 2 "AEBSwReq_2_on" 3 "AEBSwReq_3_reserved";
VAL_ 832 LDWLKAHptWrnngReq 0 "LDWLKAHptWrnngReq_0_no_request" 1 "LDWLKAHptWrnngReq_1_off" 2 "LDWLKAHptWrnngReq_2_on";
VAL_ 832 RCWSelReq 0 "RCWSelReq_0_no_request" 1 "RCWSelReq_1_driver_switch_Off_request" 2 "RCWSelReq_2_driver_switch_on_request" 3 "RCWSelReq_3_reserve";
VAL_ 832 NarwSpcAstSwReq 0 "NarwSpcAstSwReq_0_NoRequest" 1 "NarwSpcAstSwReq_1_ON" 2 "NarwSpcAstSwReq_2_OFF";
VAL_ 832 LDWSnstvtLvlReq 0 "LDWSnstvtLvlReq_0_NoRequest" 1 "LDWSnstvtLvlReq_1_Low" 2 "LDWSnstvtLvlReq_2_Standard" 3 "LDWSnstvtLvlReq_3_High";
VAL_ 832 RDASwReq 0 "RDASwReq_0_no_request" 1 "RDASwReq_1_driver_switch_Off_request" 2 "RDASwReq_2_driver_switch_on_request" 3 "RDASwReq_3_reserve";
VAL_ 832 RCTSysSelReq 0 "RCTSysSelReq_0_no_request" 1 "RCTSysSelReq_1_driver_switch_RCTA_Off_request" 2 "RCTSysSelReq_2_driver_switch_RCTA_on_request" 3 "RCTSysSelReq_3_driver_switch_RCTB_RCTA_on_request";
VAL_ 832 LCASelReq 0 "LCASelReq_0_no_request" 1 "LCASelReq_1_driver_switch_Off_request" 2 "LCASelReq_2_driver_switch_on_request" 3 "LCASelReq_3_reserve";
VAL_ 832 LDWLKASwReq 0 "LDWLKASwReq_0_no_request" 1 "LDWLKASwReq_1_off" 2 "LDWLKASwReq_2_LDW" 3 "LDWLKASwReq_3_LDP" 4 "LDWLKASwReq_4_LKA" 5 "LDWLKASwReq_5_ELK";
VAL_ 482 TrPfShftPtrnSw3A 0 "TrPfShftPtrnSw3A_0_False" 1 "TrPfShftPtrnSw3A_1_True";
VAL_ 482 TrPfShftPtrnSw2A 0 "TrPfShftPtrnSw2A_0_False" 1 "TrPfShftPtrnSw2A_1_True";
VAL_ 482 PfTrTapUpDwnSwSta 0 "PfTrTapUpDwnSwSta_0__No_Activation" 1 "PfTrTapUpDwnSwSta_1__Increment_Switch_Active" 2 "PfTrTapUpDwnSwSta_2__Decrement_Switch_Active" 3 "PfTrTapUpDwnSwSta_3__Illegal_Up_Down_Switch_State_Active";
VAL_ 482 StrgWhlTipcSwDataIntgty 0 "StrgWhlTipcSwDataIntgty_l_0_Data_Valid" 1 "StrgWhlTipcSwDataIntgty_l_1_Data_Invalid";
VAL_ 482 CCSwStsDistIncSwA 0 "CCSwStsDistIncSwA_0_False" 1 "CCSwStsDistIncSwA_1_True";
VAL_ 482 CCSwStsDistDecSwA 0 "CCSwStsDistDecSwA_0_False" 1 "CCSwStsDistDecSwA_1_True";
VAL_ 482 CCSwStsSpdIncSwA 0 "CCSwStsSpdIncSwA_0_False" 1 "CCSwStsSpdIncSwA_1_True";
VAL_ 482 CCSwStsSpdDecSwA 0 "CCSwStsSpdDecSwA_0_False" 1 "CCSwStsSpdDecSwA_1_True";
VAL_ 482 CCSwStsSwDataIntgty 0 "CCSwStsSwDataIntgty_0_Data_Valid" 1 "CCSwStsSwDataIntgty_1_Data_Invalid" 2 "CCSwStsSwDataIntgty_2_Failure_Detected" 3 "CCSwStsSwDataIntgty_3_Illegal_Range";
VAL_ 482 CCSwStsOnSwA 0 "CCSwStsOnSwA_0_False" 1 "CCSwStsOnSwA_1_True";
VAL_ 482 CCSwStsCanclSwA 0 "CCSwStsCanclSwA_0_False" 1 "CCSwStsCanclSwA_1_True";
VAL_ 482 PfTrTapUpDwnEnbSwSta 0 "PfTrTapUpDwnEnbSwSta_0__No_Activation" 1 "PfTrTapUpDwnEnbSwSta_1__Driver_Shift_Control_Enable_Switch_Active" 2 "PfTrTapUpDwnEnbSwSta_2__Electronic_Range_Select_Enable_Switch_Active" 3 "PfTrTapUpDwnEnbSwSta_3__Illegal_Enable_Switch_State_Active";
VAL_ 482 PfTrTapUpDwnSecySwSta 0 "PfTrTapUpDwnSecySwSta_0__No_Activation" 1 "PfTrTapUpDwnSecySwSta_1__Increment_Switch_Active" 2 "PfTrTapUpDwnSecySwSta_2__Decrement_Switch_Active" 3 "PfTrTapUpDwnSecySwSta_3__Illegal_Up_Down_Switch_State_Active";
VAL_ 482 TrPfShftPtrnSw1A 0 "TrPfShftPtrnSw1A_0_False" 1 "TrPfShftPtrnSw1A_1_True";
VAL_ 482 SWSSelUpSwA 0 "SWSSelUpSwA_0_False" 1 "SWSSelUpSwA_1_True";
VAL_ 482 SWSSelRSwA 0 "SWSSelRSwA_0_False" 1 "SWSSelRSwA_1_True";
VAL_ 482 SWSSelLSwA 0 "SWSSelLSwA_0_False" 1 "SWSSelLSwA_1_True";
VAL_ 482 SWSSelDwnSwA 0 "SWSSelDwnSwA_0_False" 1 "SWSSelDwnSwA_1_True";
VAL_ 482 SWSCnfmSwA 0 "SWSCnfmSwA_0_False" 1 "SWSCnfmSwA_1_True";
VAL_ 482 CCSwStsRsmSwA 0 "CCSwStsRsmSwA_0_False" 1 "CCSwStsRsmSwA_1_True";
VAL_ 482 HMISafFltsts 0 "HMISafFltsts_0_normal" 1 "HMISafFltsts_1_ZXDFault" 2 "HMISafFltsts_2_IPKFault" 3 "HMISafFltsts_3_CheckIPDE2EFault" 4 "HMISafFltsts_4_HMIFault" 5 "HMISafFltsts_5_HMINonCriricalFault" 6 "HMISafFltsts_6_Reserved" 7 "HMISafFltsts_7_Reserved";
VAL_ 482 SwStaE2EErr 0 "SwStaE2EErr_0_OK" 1 "SwStaE2EErr_1_NONEWDATA" 2 "SwStaE2EErr_2_WRONGCRC" 3 "SwStaE2EErr_3_SYNC" 4 "SwStaE2EErr_4_INITIAL" 5 "SwStaE2EErr_5_REPEATED" 6 "SwStaE2EErr_6_OKSOMELOST" 7 "SwStaE2EErr_7_WRONGSEQUENCE";
VAL_ 482 TrPfShftPtrnSw4A 0 "TrPfShftPtrnSw4A_0_False" 1 "TrPfShftPtrnSw4A_1_True";
VAL_ 1010 TgtParkingChosed 0 "TgtParkingChosed_0_NoChosed" 1 "TgtParkingChosed_1_ChosedId1" 2 "TgtParkingChosed_2_ChosedId2" 3 "TgtParkingChosed_3_ChosedId3" 4 "TgtParkingChosed_4_ChosedId4" 5 "TgtParkingChosed_5_ChosedId5" 6 "TgtParkingChosed_6_ChosedId6" 7 "TgtParkingChosed_7_ChosedId7" 8 "TgtParkingChosed_8_ChosedId8" 9 "TgtParkingChosed_9_ChosedId9" 10 "TgtParkingChosed_10_ChosedId10" 11 "TgtParkingChosed_11_ChosedId11" 12 "TgtParkingChosed_12_ChosedId12" 13 "TgtParkingChosed_13_Reserved" 14 "TgtParkingChosed_14_Reserved" 15 "TgtParkingChosed_15_Reserved";
VAL_ 1010 SpdLmtMdFICM 0 "SpdLmtMdFICM_0_NoRequest" 1 "SpdLmtMdFICM_1_Off" 2 "SpdLmtMdFICM_2_SLIF" 3 "SpdLmtMdFICM_3_ISA";
VAL_ 1010 AutocParkngSwReq 0 "AutocParkngSwReq_0_Idle" 1 "AutocParkngSwReq_1_Press" 2 "AutocParkngSwReq_2_off" 3 "AutocParkngSwReq_3_Error";
VAL_ 1010 IMATESysSts 0 "IMATESysSts_0_Off" 1 "IMATESysSts_1_Standby" 2 "IMATESysSts_2_Active" 3 "IMATESysSts_3_Fault" 4 "IMATESysSts_4_DMS_unknown" 5 "IMATESysSts_5_DMS_normal" 6 "IMATESysSts_6_DMS_abnormal" 7 "IMATESysSts_7_DMS_obstruction";
VAL_ 1010 PwrMdCtrlResp 0 "PwrMdCtrlResp__0_No_Request" 1 "PwrMdCtrlResp__1_Approved" 2 "PwrMdCtrlResp__2_Authentication_Failure" 3 "PwrMdCtrlResp__3_Other_Reason" 4 "PwrMdCtrlResp__4_FeatureisTimeout" 5 "PwrMdCtrlResp__5_Featureisnotsupported";
VAL_ 1010 FRDircnLghtFltsts 0 "FRDircnLghtFltsts_0_False" 1 "FRDircnLghtFltsts_1_True";
VAL_ 1010 FLDircnLghtFltsts 0 "FLDircnLghtFltsts_0_False" 1 "FLDircnLghtFltsts_1_True";
VAL_ 1010 FrSsdManuCtrl 0 "FrSsdManuCtrl_0_No_Request" 1 "FrSsdManuCtrl_1_Manual_Open" 2 "FrSsdManuCtrl_2_Manual_Close" 3 "FrSsdManuCtrl_3_Reserve";
SIG_GROUP_ 820 IICBAD_100ms_Group37 1 : AutoLaneChngMsgReq AutoLaneChngSetResp AutoLaneChngSwDspCmd DILampsCtrl HzrdLampsCtrl ICBAD_100ms_Group37_CRC ICBAD_100ms_Group37_RC ICBAD_100ms_Group37_Reserved1 ICBAD_100ms_Group37_Reserved2 ICBAD_100ms_Group37_Reserved3 ICBAD_100ms_Group37_Reserved4 ICBAD_100ms_Group37_Reserved5 ICBAD_100ms_Group37_Reserved6 ICBAD_100ms_Group37_Reserved7 ICBAD_100ms_Group37_Reserved8;
SIG_GROUP_ 382 IICBAD_20ms_Group07 1 : ACCAccReqSts_CH ACCAccReqVal ACCGoReq ACCSdslReq ACCSysFltSts ACCSysSts AIPkgAPASCSAcclReqVal APAEPBOPReq APAEPBOPReqV APASCSAcclReqSts AutodDrvngSysEmgcBrkReq AutodDrvngSysEmgcBrkReqV AutodDrvngSysFlrSts AutodDrvngSysFlrStsV AutodDrvngSysMdReq AutodDrvngSysMdReqV AutodDrvngSysSCSDrvOffReq AutodDrvngSysSCSDrvOffReqV AutodDrvngSysSCSSdslReq AutodDrvngSysSCSSdslReqV ICBAD_20ms_Group07_CRC ICBAD_20ms_Group07_RC ICBAD_20ms_Group07_Reserved1;
SIG_GROUP_ 385 IICBAD_20ms_Group09 1 : ICBAD_20ms_Group09_CRC ICBAD_20ms_Group09_RC ICBAD_20ms_Group09_Reserved1 ICBAD_20ms_Group09_Reserved2 ICBAD_20ms_Group09_Reserved3 ICBAD_20ms_Group09_Reserved4 ICBAD_20ms_Group09_Reserved5 ICBAD_20ms_Group09_Reserved6 NSABacSysSts NSADisFucSts NSAForSysSts NSAReqAVMDis;
SIG_GROUP_ 343 IICBAD_20ms_Group46 1 : AEBBrkJerkLvlReq AEBDclReqSts AEBDclReqToqVal AEBDclReqVal AEBHydBrkAstLvlReq AEBPrflReq AEBSysFltSts AEBSysSts ICBAD_20ms_Group46_CRC ICBAD_20ms_Group46_RC ICBAD_20ms_Group46_Reserved1 ICBAD_20ms_Group46_Reserved2;
SIG_GROUP_ 893 IICBAD_100ms_Group25 1 : ICBAD_100ms_Group25_CRC ICBAD_100ms_Group25_RC ICBAD_100ms_Group25_Reserved103 ICBAD_100ms_Group25_Reserved111 ICBAD_100ms_Group25_Reserved119 ICBAD_100ms_Group25_Reserved127 ICBAD_100ms_Group25_Reserved135 ICBAD_100ms_Group25_Reserved143 ICBAD_100ms_Group25_Reserved15 ICBAD_100ms_Group25_Reserved151 ICBAD_100ms_Group25_Reserved159 ICBAD_100ms_Group25_Reserved167 ICBAD_100ms_Group25_Reserved175 ICBAD_100ms_Group25_Reserved183 ICBAD_100ms_Group25_Reserved191 ICBAD_100ms_Group25_Reserved23 ICBAD_100ms_Group25_Reserved31 ICBAD_100ms_Group25_Reserved39 ICBAD_100ms_Group25_Reserved47 ICBAD_100ms_Group25_Reserved55 ICBAD_100ms_Group25_Reserved63 ICBAD_100ms_Group25_Reserved71 ICBAD_100ms_Group25_Reserved79 ICBAD_100ms_Group25_Reserved87 ICBAD_100ms_Group25_Reserved95 MemPkngSlntPtrlEnbSwResp MemPkngSwResp PEBSysFltSts;
SIG_GROUP_ 360 IICBAD_20ms_Group13 1 : APACmdEPSSts APAF APASCUReqSts APASCUReqStsV APAShifterPosReqd APAShifterPosReqdV APATrgtEPSStrgWhlAng ICBAD_20ms_Group13_CRC ICBAD_20ms_Group13_RC ICBAD_20ms_Group13_Reserved1 ICBAD_20ms_Group13_Reserved2 ICBAD_20ms_Group13_Reserved3 ICBAD_20ms_Group13_Reserved4 ICBAD_20ms_Group13_Reserved5;
SIG_GROUP_ 474 IICBAD_20ms_Group48 1 : ICBAD_20ms_Group48_CRC ICBAD_20ms_Group48_RC ICBAD_20ms_Group48_Reserved1 ICBAD_20ms_Group48_Reserved2 ICBAD_20ms_Group48_Reserved3 ICBAD_20ms_Group48_Reserved4 ICBAD_20ms_Group48_Reserved5 ICBAD_20ms_Group48_Reserved6 LDWLKALVsulznReq LDWLKARVsulznReq LDWLKAVbnLvlReq LDWSysFltSts LDWSysSts;
SIG_GROUP_ 351 IICBAD_20ms_Group05 1 : APACrpSpdReqVal_IPD APARevrDrgReq APAToqReqVal APATotWhlToqReqVal APAVCUReqSts ICBAD_20ms_Group05_CRC ICBAD_20ms_Group05_RC ICBAD_20ms_Group05_Reserved1 ICBAD_20ms_Group05_Reserved10 ICBAD_20ms_Group05_Reserved11 ICBAD_20ms_Group05_Reserved12 ICBAD_20ms_Group05_Reserved13 ICBAD_20ms_Group05_Reserved14 ICBAD_20ms_Group05_Reserved15 ICBAD_20ms_Group05_Reserved2 ICBAD_20ms_Group05_Reserved3 ICBAD_20ms_Group05_Reserved4 ICBAD_20ms_Group05_Reserved5 ICBAD_20ms_Group05_Reserved6 ICBAD_20ms_Group05_Reserved7 ICBAD_20ms_Group05_Reserved8 ICBAD_20ms_Group05_Reserved9;
SIG_GROUP_ 424 IICBAD_20ms_Group12 1 : APASts AutodDrvngSysSts AutodDrvngSysStsV ICBAD_20ms_Group12_CRC ICBAD_20ms_Group12_RC ICBAD_20ms_Group12_Reserved1 ICBAD_20ms_Group12_Reserved2 ICBAD_20ms_Group12_Reserved3 ICBAD_20ms_Group12_Reserved4 ICBAD_20ms_Group12_Reserved5 ICBAD_20ms_Group12_Reserved6;
SIG_GROUP_ 81 IICBAD_ZONE_20ms_Group13 1 : ACCToqReqSts ACCToqReqVal ICBAD_ZONE_20ms_Group13_CRC ICBAD_ZONE_20ms_Group13_RC ICBAD_ZONE_20ms_Group13_Reserved0 ICBAD_ZONE_20ms_Group13_Reserved1 ICBAD_ZONE_20ms_Group13_Reserved2 ICBAD_ZONE_20ms_Group13_Reserved3 ICBAD_ZONE_20ms_Group13_Reserved4 ICBAD_ZONE_20ms_Group13_Reserved5 LKASysFltSts LKASysSts TJAICASysFltSts TJAICASysSts;
SIG_GROUP_ 66 IICBVC_100ms_Group01 1 : ClstrDspdVehSpd DspMeasmtSys FLSeatHeatCtrlSts FLSeatVentCtrlSts FRSeatHeatCtrlSts FRSeatVentCtrlSts ICBVC_100ms_Group01_CRC ICBVC_100ms_Group01_RC ICBVC_100ms_Group01_Reserved103 ICBVC_100ms_Group01_Reserved111 ICBVC_100ms_Group01_Reserved119 ICBVC_100ms_Group01_Reserved127 ICBVC_100ms_Group01_Reserved14 ICBVC_100ms_Group01_Reserved21 ICBVC_100ms_Group01_Reserved31 ICBVC_100ms_Group01_Reserved47 ICBVC_100ms_Group01_Reserved55 ICBVC_100ms_Group01_Reserved63 ICBVC_100ms_Group01_Reserved71 ICBVC_100ms_Group01_Reserved72 ICBVC_100ms_Group01_Reserved79 ICBVC_100ms_Group01_Reserved80 ICBVC_100ms_Group01_Reserved84 ICBVC_100ms_Group01_Reserved92 MdOfPwrMd PDCSwReq PwrMdExtrCtrlAvlbl;
SIG_GROUP_ 482 IICBVC_50ms_Group11 1 : CCSwStsCanclSwA CCSwStsDistDecSwA CCSwStsDistIncSwA CCSwStsOnSwA CCSwStsRsmSwA CCSwStsSpdDecSwA CCSwStsSpdIncSwA CCSwStsSwDataIntgty HMISafFltsts ICBVC_50ms_Group11_CRC ICBVC_50ms_Group11_RC ICBVC_50ms_Group11_Reserved1 ICBVC_50ms_Group11_Reserved2 ICBVC_50ms_Group11_Reserved3 ICBVC_50ms_Group11_Reserved4 ICBVC_50ms_Group11_Reserved5 ICBVC_50ms_Group11_Reserved6 PfTrTapUpDwnEnbSwSta PfTrTapUpDwnSecySwSta PfTrTapUpDwnSwSta SWSCnfmSwA SWSSelDwnSwA SWSSelLSwA SWSSelRSwA SWSSelUpSwA StrgWhlTipcSwDataIntgty SwStaE2EErr TrPfShftPtrnSw1A TrPfShftPtrnSw2A TrPfShftPtrnSw3A TrPfShftPtrnSw4A;
SIG_GROUP_ 1010 IICBVC_50ms_Group13 1 : AutocParkngSwReq FLDircnLghtFltsts FRDircnLghtFltsts FrSsdManuCtrl ICBVC_50ms_Group13_CRC ICBVC_50ms_Group13_RC ICBVC_50ms_Group13_Reserved1 ICBVC_50ms_Group13_Reserved10 ICBVC_50ms_Group13_Reserved11 ICBVC_50ms_Group13_Reserved12 ICBVC_50ms_Group13_Reserved13 ICBVC_50ms_Group13_Reserved14 ICBVC_50ms_Group13_Reserved15 ICBVC_50ms_Group13_Reserved16 ICBVC_50ms_Group13_Reserved2 ICBVC_50ms_Group13_Reserved3 ICBVC_50ms_Group13_Reserved4 ICBVC_50ms_Group13_Reserved5 ICBVC_50ms_Group13_Reserved6 ICBVC_50ms_Group13_Reserved7 ICBVC_50ms_Group13_Reserved8 ICBVC_50ms_Group13_Reserved9 IMATESysSts PwrMdCtrlResp SpdLmtMdFICM TgtParkingChosed;
